VERSION ""

NS_ :

BS_:

BU_: BMS CVC_P EVCC FMCU RMCU POD_GW PCU ADCU_P DUMMY_ECU

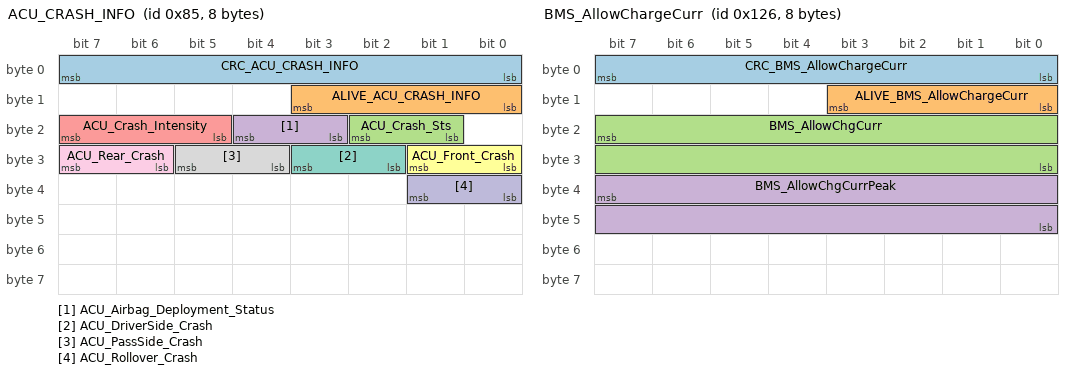
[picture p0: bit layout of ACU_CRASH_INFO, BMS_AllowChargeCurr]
BO_ 133 ACU_CRASH_INFO: 8 CVC_P
 SG_ CRC_ACU_CRASH_INFO : 7|8@0+ (1,0) [0|255] ""  BMS,EVCC,FMCU,RMCU,POD_GW,PCU
 SG_ ALIVE_ACU_CRASH_INFO : 11|4@0+ (1,0) [0|15] ""  BMS,EVCC,FMCU,RMCU,POD_GW,PCU
 SG_ ACU_Crash_Sts : 18|2@0+ (1,0) [0|3] ""  BMS,EVCC,FMCU,RMCU,POD_GW,PCU
 SG_ ACU_Airbag_Deployment_Status : 20|2@0+ (1,0) [0|3] ""  BMS,EVCC,FMCU,RMCU,POD_GW,PCU
 SG_ ACU_Crash_Intensity : 23|3@0+ (1,0) [0|7] ""  BMS,EVCC,FMCU,RMCU,POD_GW,PCU
 SG_ ACU_Front_Crash : 25|2@0+ (1,0) [0|3] ""  BMS,EVCC,FMCU,RMCU,POD_GW,PCU
 SG_ ACU_DriverSide_Crash : 27|2@0+ (1,0) [0|3] ""  BMS,EVCC,FMCU,RMCU,POD_GW,PCU
 SG_ ACU_PassSide_Crash : 29|2@0+ (1,0) [0|3] ""  BMS,EVCC,FMCU,RMCU,POD_GW,PCU
 SG_ ACU_Rear_Crash : 31|2@0+ (1,0) [0|3] ""  BMS,EVCC,FMCU,RMCU,POD_GW,PCU
 SG_ ACU_Rollover_Crash : 33|2@0+ (1,0) [0|3] ""  BMS,EVCC,FMCU,RMCU,POD_GW,PCU

BO_ 294 BMS_AllowChargeCurr: 8 BMS
 SG_ CRC_BMS_AllowChargeCurr : 7|8@0+ (1,0) [0|255] ""  CVC_P,EVCC
 SG_ ALIVE_BMS_AllowChargeCurr : 11|4@0+ (1,0) [0|15] ""  CVC_P,EVCC
 SG_ BMS_AllowChgCurr : 23|16@0+ (0.1,0) [0|1500] "A"  CVC_P,EVCC
 SG_ BMS_AllowChgCurrPeak : 39|16@0+ (0.1,0) [0|1500] "A"  CVC_P,EVCC

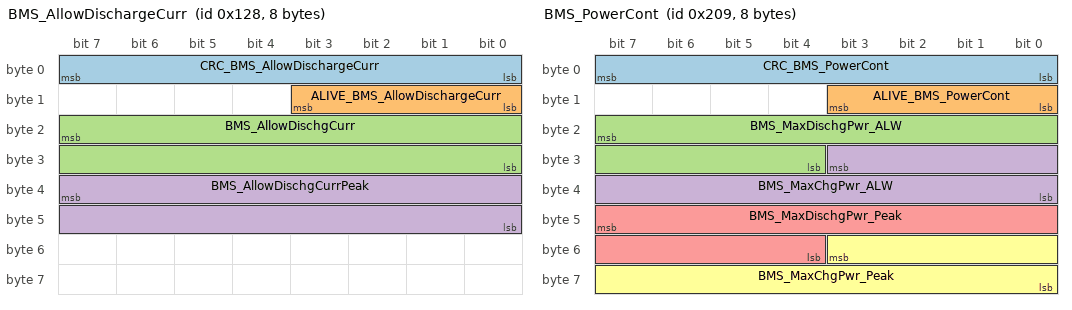
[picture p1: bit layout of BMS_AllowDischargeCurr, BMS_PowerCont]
BO_ 296 BMS_AllowDischargeCurr: 8 BMS
 SG_ CRC_BMS_AllowDischargeCurr : 7|8@0+ (1,0) [0|255] ""  CVC_P
 SG_ ALIVE_BMS_AllowDischargeCurr : 11|4@0+ (1,0) [0|15] ""  CVC_P
 SG_ BMS_AllowDischgCurr : 23|16@0+ (0.1,0) [0|1500] "A"  CVC_P
 SG_ BMS_AllowDischgCurrPeak : 39|16@0+ (0.1,0) [0|1500] "A"  CVC_P

BO_ 372 BMS_CurMeas: 24 BMS
 SG_ CRC_BMS_CurMeas : 7|8@0+ (1,0) [0|255] ""  CVC_P,EVCC,FMCU,RMCU,POD_GW,PCU
 SG_ ALIVE_BMS_CurMeas : 11|4@0+ (1,0) [0|15] ""  CVC_P,EVCC,FMCU,RMCU,POD_GW,PCU
 SG_ BMS_StartOfMeasument_STS : 15|1@0+ (1,0) [0|1] ""  CVC_P,EVCC
 SG_ BMS_PackCur_MEAS : 23|16@0+ (0.1,-3276.8) [-3276.8|3276.7] "A"  CVC_P,EVCC,FMCU,RMCU,POD_GW,PCU
 SG_ BMS_HVPackVol_MEAS : 39|16@0+ (0.1,0) [0|800] "V"  CVC_P,EVCC,FMCU,RMCU,PCU
 SG_ BMS_HVLinkVol_MEAS : 55|16@0+ (0.1,0) [0|800] "V"  CVC_P,EVCC,FMCU,RMCU,PCU
 SG_ BMS_HVBusVol_MEAS : 71|16@0+ (0.1,0) [0|800] "V"  CVC_P,EVCC,PCU
 SG_ BMS_HVFuseVol_MEAS : 87|16@0+ (0.1,0) [0|800] "V"  CVC_P
 SG_ BMS_MainNegRelay_Volt : 103|8@0+ (0.1,0) [0|5] "V"  CVC_P
 SG_ BMS_CellNumMinCellVol : 111|8@0+ (1,0) [0|255] ""  CVC_P
 SG_ BMS_CellNumMaxCellVol : 119|8@0+ (1,0) [0|255] ""  CVC_P
 SG_ BMS_MinCellVol : 127|13@0+ (0.001,0) [0|6] "V"  CVC_P
 SG_ BMS_MaxCellVol : 143|13@0+ (0.001,0) [0|6] "V"  CVC_P
 SG_ BMS_MaxMinDiffCellVol : 159|13@0+ (0.001,0) [0|2] "V"  CVC_P
 SG_ BMS_CVC_Insulation_Mon_Sts : 162|1@0+ (1,0) [0|1] ""  CVC_P,EVCC
 SG_ BMS_PackInsuRes : 175|16@0+ (1,0) [0|60000] "kOhm"  CVC_P,EVCC

BO_ 521 BMS_PowerCont: 8 BMS
 SG_ CRC_BMS_PowerCont : 7|8@0+ (1,0) [0|255] ""  CVC_P,FMCU,RMCU,PCU
 SG_ ALIVE_BMS_PowerCont : 11|4@0+ (1,0) [0|15] ""  CVC_P,FMCU,RMCU,PCU
 SG_ BMS_MaxDischgPwr_ALW : 23|12@0+ (0.1,0) [0|400] "kW"  CVC_P,FMCU,RMCU,PCU
 SG_ BMS_MaxChgPwr_ALW : 27|12@0+ (0.1,0) [0|400] "kW"  CVC_P,FMCU,RMCU,PCU
 SG_ BMS_MaxDischgPwr_Peak : 47|12@0+ (0.2,0) [0|800] "kW"  CVC_P,FMCU,RMCU,PCU
 SG_ BMS_MaxChgPwr_Peak : 51|12@0+ (0.2,0) [0|800] "kW"  CVC_P,FMCU,RMCU,PCU

BO_ 533 BMS_Sts: 16 BMS
 SG_ CRC_BMS_Sts : 7|8@0+ (1,0) [0|255] ""  CVC_P,EVCC,FMCU,RMCU,POD_GW,PCU
 SG_ ALIVE_BMS_Sts : 11|4@0+ (1,0) [0|15] ""  CVC_P,EVCC,FMCU,RMCU,POD_GW,PCU
 SG_ BMS_BatBalance_ERR : 12|1@0+ (1,0) [0|1] ""  CVC_P,EVCC,FMCU,RMCU,POD_GW,PCU
 SG_ BMS_Balance_STS : 13|1@0+ (1,0) [0|1] ""  CVC_P,EVCC,FMCU,RMCU,POD_GW,PCU
 SG_ BMS_IGN_Sts : 14|1@0+ (1,0) [0|1] ""  CVC_P,EVCC,FMCU,RMCU,POD_GW,PCU
 SG_ BMS_HWCrash_Sts : 15|1@0+ (1,0) [0|1] ""  CVC_P,EVCC,FMCU,RMCU,POD_GW,PCU
 SG_ BMS_HVIL_STS : 17|2@0+ (1,0) [0|3] ""  CVC_P,EVCC,FMCU,RMCU,POD_GW,PCU
 SG_ BMS_HVOnOff_STS : 19|2@0+ (1,0) [0|3] ""  CVC_P,EVCC,FMCU,RMCU,POD_GW,PCU
 SG_ BMS_ERR_LEV : 23|4@0+ (1,0) [0|7] ""  CVC_P,EVCC,FMCU,RMCU,POD_GW,PCU
 SG_ BMS_SocActual_EST : 25|10@0+ (0.1,0) [0|100] "%"  CVC_P,EVCC,FMCU,RMCU,POD_GW,PCU
 SG_ BMS_Sys_STS : 29|4@0+ (1,0) [0|15] ""  CVC_P,EVCC,FMCU,RMCU,POD_GW,PCU
 SG_ BMS_ISU_Status : 31|2@0+ (1,0) [0|3] ""  CVC_P,EVCC,FMCU,RMCU,POD_GW,PCU
 SG_ BMS_SOH : 47|8@0+ (0.5,0) [0|100] "%"  CVC_P,EVCC,FMCU,RMCU,POD_GW,PCU
 SG_ BMS_SOE : 55|8@0+ (0.5,0) [0|100] "%"  CVC_P,EVCC,FMCU,RMCU,POD_GW,PCU
 SG_ BMS_HV_Sts : 63|8@0+ (1,0) [0|255] ""  CVC_P,EVCC,FMCU,RMCU,POD_GW,PCU
 SG_ BMS_Display_SOC : 71|10@0+ (0.1,0) [0|100] "%"  CVC_P,EVCC,FMCU,RMCU,PCU
 SG_ BMS_SOCE : 87|14@0+ (0.01,0) [0|100] "%"  CVC_P

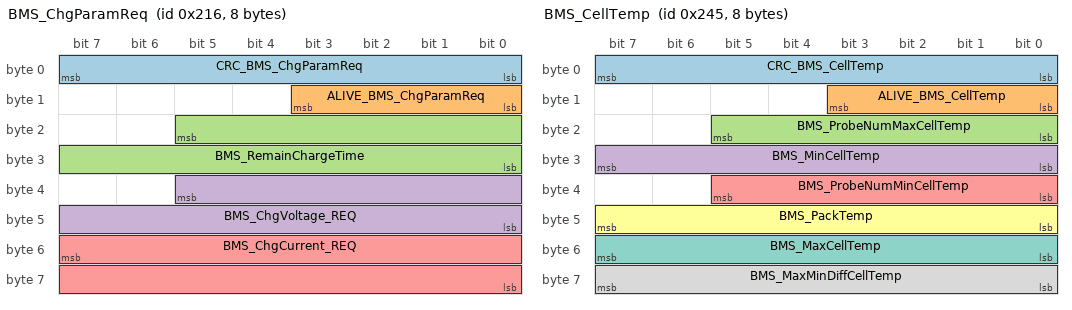
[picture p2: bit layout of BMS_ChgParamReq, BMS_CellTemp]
BO_ 534 BMS_ChgParamReq: 8 BMS
 SG_ CRC_BMS_ChgParamReq : 7|8@0+ (1,0) [0|255] ""  CVC_P,EVCC
 SG_ ALIVE_BMS_ChgParamReq : 11|4@0+ (1,0) [0|15] ""  CVC_P,EVCC
 SG_ BMS_RemainChargeTime : 21|14@0+ (1,0) [0|16383] "min"  CVC_P,EVCC
 SG_ BMS_ChgVoltage_REQ : 37|14@0+ (0.1,0) [0|800] "V"  CVC_P,EVCC
 SG_ BMS_ChgCurrent_REQ : 55|16@0+ (0.1,0) [0|1500] "A"  CVC_P,EVCC

BO_ 581 BMS_CellTemp: 8 BMS
 SG_ CRC_BMS_CellTemp : 7|8@0+ (1,0) [0|255] ""  CVC_P,EVCC,POD_GW
 SG_ ALIVE_BMS_CellTemp : 11|4@0+ (1,0) [0|15] ""  CVC_P,EVCC,POD_GW
 SG_ BMS_ProbeNumMaxCellTemp : 21|6@0+ (1,0) [0|63] ""  CVC_P,POD_GW
 SG_ BMS_MinCellTemp : 31|8@0+ (1,-40) [-40|215] "Degree C"  CVC_P
 SG_ BMS_ProbeNumMinCellTemp : 37|6@0+ (1,0) [0|63] ""  CVC_P,POD_GW
 SG_ BMS_PackTemp : 47|8@0+ (1,-40) [-40|215] "Degree C"  CVC_P
 SG_ BMS_MaxCellTemp : 55|8@0+ (1,-40) [-40|215] "Degree C"  CVC_P
 SG_ BMS_MaxMinDiffCellTemp : 63|8@0+ (1,-40) [-40|215] "Degree C"  CVC_P

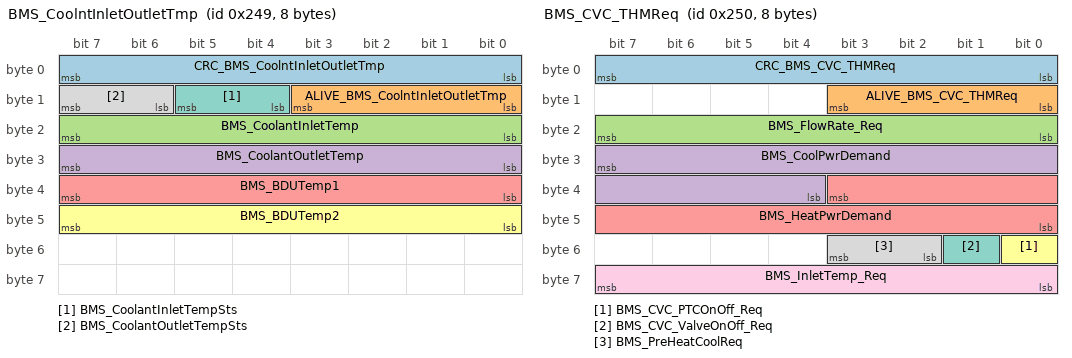
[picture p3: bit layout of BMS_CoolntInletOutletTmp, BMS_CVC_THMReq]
BO_ 585 BMS_CoolntInletOutletTmp: 8 BMS
 SG_ CRC_BMS_CoolntInletOutletTmp : 7|8@0+ (1,0) [0|255] ""  CVC_P,POD_GW
 SG_ ALIVE_BMS_CoolntInletOutletTmp : 11|4@0+ (1,0) [0|15] ""  CVC_P,POD_GW
 SG_ BMS_CoolantInletTemp : 23|8@0+ (1,-40) [-40|130] "Degree C"  CVC_P
 SG_ BMS_CoolantOutletTemp : 31|8@0+ (1,-40) [-40|130] "Degree C"  CVC_P
 SG_ BMS_BDUTemp1 : 39|8@0+ (1,-40) [-40|215] "Degree C"  CVC_P
 SG_ BMS_BDUTemp2 : 47|8@0+ (1,-40) [-40|215] "Degree C"  CVC_P
 SG_ BMS_CoolantInletTempSts : 13|2@0+ (1,0) [0|3] ""  CVC_P,POD_GW
 SG_ BMS_CoolantOutletTempSts : 15|2@0+ (1,0) [0|3] ""  CVC_P,POD_GW

BO_ 592 BMS_CVC_THMReq: 8 BMS
 SG_ CRC_BMS_CVC_THMReq : 7|8@0+ (1,0) [0|255] ""  CVC_P
 SG_ ALIVE_BMS_CVC_THMReq : 11|4@0+ (1,0) [0|15] ""  CVC_P
 SG_ BMS_FlowRate_Req : 23|8@0+ (1,0) [0|50] "l/min"  CVC_P
 SG_ BMS_CoolPwrDemand : 31|12@0+ (0.1,0) [0|10] "kW"  CVC_P
 SG_ BMS_HeatPwrDemand : 35|12@0+ (0.1,0) [0|10] "kW"  CVC_P
 SG_ BMS_CVC_PTCOnOff_Req : 48|1@0+ (1,0) [0|1] ""  CVC_P
 SG_ BMS_CVC_ValveOnOff_Req : 49|1@0+ (1,0) [0|1] ""  CVC_P
 SG_ BMS_PreHeatCoolReq : 51|2@0+ (1,0) [0|3] ""  CVC_P
 SG_ BMS_InletTemp_Req : 63|8@0+ (1,-40) [-40|215] "Degree C"  CVC_P

BO_ 816 BMS_HistData: 8 BMS
 SG_ CRC_BMS_HistData : 7|8@0+ (1,0) [0|255] ""  CVC_P
 SG_ ALIVE_BMS_HistData : 11|4@0+ (1,0) [0|15] ""  CVC_P
 SG_ BMS_ContactorAging : 23|8@0+ (1,0) [0|100] ""  CVC_P

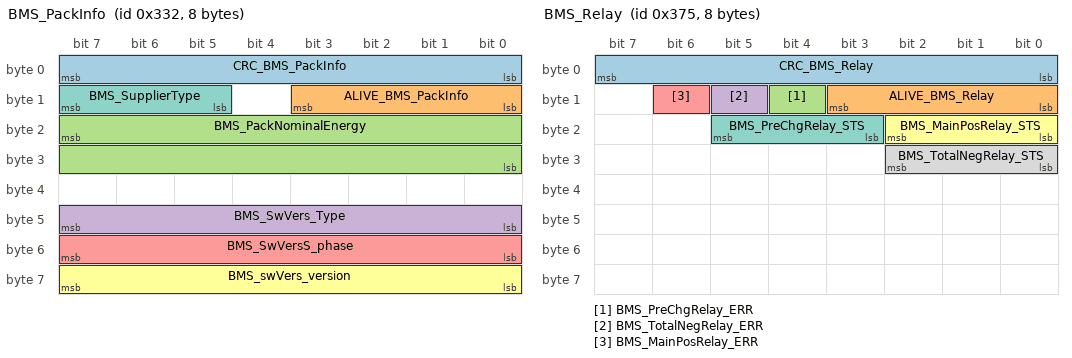
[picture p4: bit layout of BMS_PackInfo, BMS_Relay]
BO_ 818 BMS_PackInfo: 8 BMS
 SG_ CRC_BMS_PackInfo : 7|8@0+ (1,0) [0|255] ""  CVC_P
 SG_ ALIVE_BMS_PackInfo : 11|4@0+ (1,0) [0|15] ""  CVC_P
 SG_ BMS_PackNominalEnergy : 23|16@0+ (0.1,0) [0|6553.5] "kWh"  CVC_P
 SG_ BMS_SwVers_Type : 47|8@0+ (1,0) [0|255] ""  DUMMY_ECU
 SG_ BMS_SwVersS_phase : 55|8@0+ (1,0) [0|255] ""  DUMMY_ECU
 SG_ BMS_swVers_version : 63|8@0+ (1,0) [0|255] ""  DUMMY_ECU
 SG_ BMS_SupplierType : 15|3@0+ (1,0) [0|7] ""  DUMMY_ECU

BO_ 885 BMS_Relay: 8 BMS
 SG_ CRC_BMS_Relay : 7|8@0+ (1,0) [0|255] ""  CVC_P,FMCU,RMCU,POD_GW,PCU
 SG_ ALIVE_BMS_Relay : 11|4@0+ (1,0) [0|15] ""  CVC_P,FMCU,RMCU,POD_GW,PCU
 SG_ BMS_PreChgRelay_ERR : 12|1@0+ (1,0) [0|1] ""  CVC_P,FMCU,RMCU,POD_GW,PCU
 SG_ BMS_TotalNegRelay_ERR : 13|1@0+ (1,0) [0|1] ""  CVC_P,FMCU,RMCU,POD_GW,PCU
 SG_ BMS_MainPosRelay_ERR : 14|1@0+ (1,0) [0|1] ""  CVC_P,FMCU,RMCU,POD_GW,PCU
 SG_ BMS_MainPosRelay_STS : 18|3@0+ (1,0) [0|7] ""  CVC_P,FMCU,RMCU,POD_GW,PCU
 SG_ BMS_PreChgRelay_STS : 21|3@0+ (1,0) [0|7] ""  CVC_P,FMCU,RMCU,POD_GW,PCU
 SG_ BMS_TotalNegRelay_STS : 26|3@0+ (1,0) [0|7] ""  CVC_P,FMCU,RMCU,POD_GW,PCU

BO_ 1110 BMS_ERROR: 24 BMS
 SG_ CRC_BMS_ERROR : 7|8@0+ (1,0) [0|255] ""  CVC_P,PCU
 SG_ ALIVE_BMS_ERROR : 11|4@0+ (1,0) [0|15] ""  CVC_P,PCU
 SG_ BMS_CellLowVol_ERR : 17|2@0+ (1,0) [0|3] ""  CVC_P
 SG_ BMS_HVIL_Err : 19|2@0+ (1,0) [0|3] ""  CVC_P,PCU
 SG_ BMS_PackInsu_ERR : 21|2@0+ (1,0) [0|3] ""  CVC_P
 SG_ BMS_CellVoltDiff_ERR : 23|2@0+ (1,0) [0|3] ""  CVC_P
 SG_ BMS_ProbeTempDiff_ERR : 25|2@0+ (1,0) [0|3] ""  CVC_P
 SG_ BMS_PackHighVol_ERR : 27|2@0+ (1,0) [0|3] ""  CVC_P,PCU
 SG_ BMS_PackLowVol_ERR : 29|2@0+ (1,0) [0|3] ""  CVC_P
 SG_ BMS_CellHighVol_ERR : 31|2@0+ (1,0) [0|3] ""  CVC_P
 SG_ BMS_ProbeHighTemp_ERR : 33|2@0+ (1,0) [0|3] ""  CVC_P,PCU
 SG_ BMS_FuseStatus_ERR : 35|2@0+ (1,0) [0|1] ""  CVC_P
 SG_ BMS_PackOverCurr_ERR : 37|2@0+ (1,0) [0|3] ""  CVC_P,PCU
 SG_ BMS_ProbeLowTemp_ERR : 39|2@0+ (1,0) [0|3] ""  CVC_P,PCU
 SG_ BMS_faultnumber : 47|64@0+ (1,0) [0|1.84467E+019] ""  CVC_P
 SG_ EHPMon_bErrVehIslnRNvMon : 15|1@0+ (1,0) [0|1] ""  CVC_P
 SG_ EHPMon_bErrPackIslnRNvMon : 14|1@0+ (1,0) [0|1] ""  CVC_P

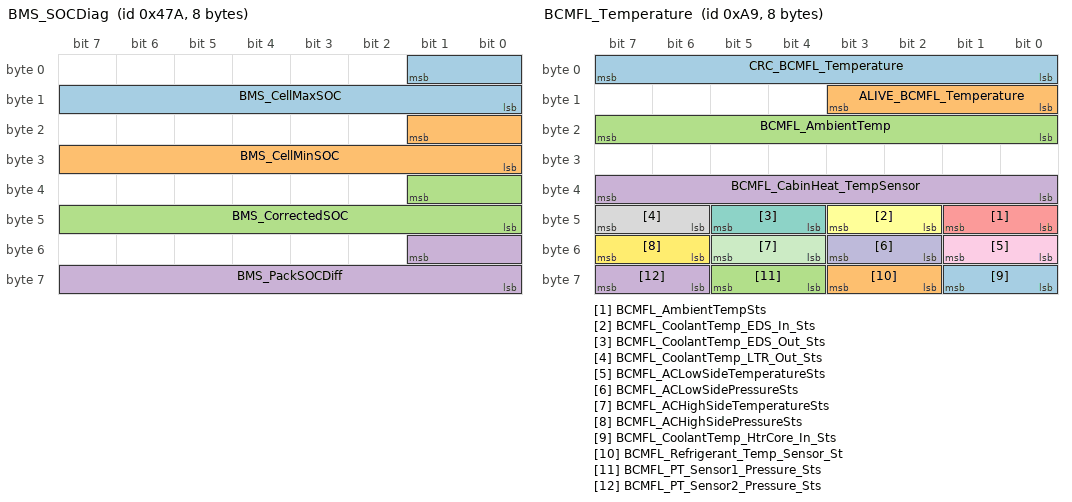
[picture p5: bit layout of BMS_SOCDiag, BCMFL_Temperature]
BO_ 1146 BMS_SOCDiag: 8 BMS
 SG_ BMS_CellMaxSOC : 1|10@0+ (0.1,0) [0|100] "%"  FMCU,RMCU,PCU
 SG_ BMS_CellMinSOC : 17|10@0+ (0.1,0) [0|100] "%"  FMCU,RMCU,PCU
 SG_ BMS_CorrectedSOC : 33|10@0+ (0.1,0) [0|100] "%"  FMCU,RMCU,PCU
 SG_ BMS_PackSOCDiff : 49|10@0+ (0.1,0) [0|100] "%"  FMCU,RMCU,PCU

BO_ 1171 BMS_WarnMsg: 8 BMS
 SG_ CRC_BMS_WarnMsg : 7|8@0+ (1,0) [0|255] ""  CVC_P,PCU
 SG_ ALIVE_BMS_WarnMsg : 11|4@0+ (1,0) [0|15] ""  CVC_P,PCU
 SG_ BMS_PackTempSts : 13|2@0+ (1,0) [0|3] ""  CVC_P
 SG_ BMS_ThermalRunaway : 14|1@0+ (1,0) [0|1] ""  CVC_P,PCU
 SG_ BMS_BatteryReplacement : 15|1@0+ (1,0) [0|1] ""  CVC_P
 SG_ BMS_Warning_PowerDegrade : 16|1@0+ (1,0) [0|1] ""  CVC_P
 SG_ BMS_Warning_DeltaSoC : 17|1@0+ (1,0) [0|1] ""  CVC_P
 SG_ BMS_Warning_HVILSts : 18|1@0+ (1,0) [0|1] ""  CVC_P
 SG_ BMS_Warning_Isolation : 19|1@0+ (1,0) [0|1] ""  CVC_P
 SG_ BMS_Warning_CoolantLeakage : 20|1@0+ (1,0) [0|1] ""  CVC_P
 SG_ BMS_MalfunctionSts : 21|1@0+ (1,0) [0|1] ""  CVC_P
 SG_ BMS_LowBattery : 23|2@0+ (1,0) [0|3] ""  CVC_P
 SG_ BMS_Warning_DeltaTemperature : 31|8@0+ (1,0) [0|255] ""  CVC_P
 SG_ BMS_Warning_BDUTemperatureSts : 39|8@0+ (1,0) [0|255] ""  CVC_P
 SG_ BMS_Warning_Contactor_Aging : 47|1@0+ (1,0) [0|1] ""  CVC_P
 SG_ BMS_Reserved_signal4 : 55|8@0+ (1,0) [0|255] ""  CVC_P
 SG_ BMS_Reserved_signal5 : 63|8@0+ (1,0) [0|255] ""  CVC_P

BO_ 1952 BMS_CellTemp_Info: 64 BMS
 SG_ BMS_CellT1 : 7|8@0+ (1,-40) [-40|210] "Degree C"  DUMMY_ECU
 SG_ BMS_CellT2 : 15|8@0+ (1,-40) [-40|210] "Degree C"  DUMMY_ECU
 SG_ BMS_CellT3 : 23|8@0+ (1,-40) [-40|210] "Degree C"  DUMMY_ECU
 SG_ BMS_CellT4 : 31|8@0+ (1,-40) [-40|210] "Degree C"  DUMMY_ECU
 SG_ BMS_CellT5 : 39|8@0+ (1,-40) [-40|210] "Degree C"  DUMMY_ECU
 SG_ BMS_CellT6 : 47|8@0+ (1,-40) [-40|210] "Degree C"  DUMMY_ECU
 SG_ BMS_CellT7 : 55|8@0+ (1,-40) [-40|210] "Degree C"  DUMMY_ECU
 SG_ BMS_CellT8 : 63|8@0+ (1,-40) [-40|210] "Degree C"  DUMMY_ECU
 SG_ BMS_CellT9 : 71|8@0+ (1,-40) [-40|210] "Degree C"  DUMMY_ECU
 SG_ BMS_CellT10 : 79|8@0+ (1,-40) [-40|210] "Degree C"  DUMMY_ECU
 SG_ BMS_CellT11 : 87|8@0+ (1,-40) [-40|210] "Degree C"  DUMMY_ECU
 SG_ BMS_CellT12 : 95|8@0+ (1,-40) [-40|210] "Degree C"  DUMMY_ECU
 SG_ BMS_CellT13 : 103|8@0+ (1,-40) [-40|210] "Degree C"  DUMMY_ECU
 SG_ BMS_CellT14 : 111|8@0+ (1,-40) [-40|210] "Degree C"  DUMMY_ECU
 SG_ BMS_CellT15 : 119|8@0+ (1,-40) [-40|210] "Degree C"  DUMMY_ECU
 SG_ BMS_CellT16 : 127|8@0+ (1,-40) [-40|210] "Degree C"  DUMMY_ECU
 SG_ BMS_CellT17 : 135|8@0+ (1,-40) [-40|210] "Degree C"  DUMMY_ECU
 SG_ BMS_CellT18 : 143|8@0+ (1,-40) [-40|210] "Degree C"  DUMMY_ECU
 SG_ BMS_CellT19 : 151|8@0+ (1,-40) [-40|210] "Degree C"  DUMMY_ECU
 SG_ BMS_CellT20 : 159|8@0+ (1,-40) [-40|210] "Degree C"  DUMMY_ECU
 SG_ BMS_CellT21 : 167|8@0+ (1,-40) [-40|210] "Degree C"  DUMMY_ECU
 SG_ BMS_CellT22 : 175|8@0+ (1,-40) [-40|210] "Degree C"  DUMMY_ECU
 SG_ BMS_CellT23 : 183|8@0+ (1,-40) [-40|210] "Degree C"  DUMMY_ECU
 SG_ BMS_CellT24 : 191|8@0+ (1,-40) [-40|210] "Degree C"  DUMMY_ECU
 SG_ BMS_CellT25 : 199|8@0+ (1,-40) [-40|210] "Degree C"  DUMMY_ECU
 SG_ BMS_CellT26 : 207|8@0+ (1,-40) [-40|210] "Degree C"  DUMMY_ECU
 SG_ BMS_CellT27 : 215|8@0+ (1,-40) [-40|210] "Degree C"  DUMMY_ECU
 SG_ BMS_CellT28 : 223|8@0+ (1,-40) [-40|210] "Degree C"  DUMMY_ECU
 SG_ BMS_CellT29 : 231|8@0+ (1,-40) [-40|210] "Degree C"  DUMMY_ECU
 SG_ BMS_CellT30 : 239|8@0+ (1,-40) [-40|210] "Degree C"  DUMMY_ECU
 SG_ BMS_CellT31 : 247|8@0+ (1,-40) [-40|210] "Degree C"  DUMMY_ECU
 SG_ BMS_CellT32 : 255|8@0+ (1,-40) [-40|210] "Degree C"  DUMMY_ECU
 SG_ BMS_CellT33 : 263|8@0+ (1,-40) [-40|210] "Degree C"  DUMMY_ECU
 SG_ BMS_CellT34 : 271|8@0+ (1,-40) [-40|210] "Degree C"  DUMMY_ECU
 SG_ BMS_CellT35 : 279|8@0+ (1,-40) [-40|210] "Degree C"  DUMMY_ECU
 SG_ BMS_CellT36 : 287|8@0+ (1,-40) [-40|210] "Degree C"  DUMMY_ECU
 SG_ BMS_BalArea_Temperature1 : 295|8@0+ (1,-50) [-50|150] "Degree C"  DUMMY_ECU
 SG_ BMS_BalArea_Temperature2 : 303|8@0+ (1,-50) [-50|150] "Degree C"  DUMMY_ECU
 SG_ BMS_BalArea_Temperature3 : 311|8@0+ (1,-50) [-50|150] "Degree C"  DUMMY_ECU
 SG_ BMS_BalArea_Temperature4 : 319|8@0+ (1,-50) [-50|150] "Degree C"  DUMMY_ECU
 SG_ BMS_BalArea_Temperature5 : 327|8@0+ (1,-50) [-50|150] "Degree C"  DUMMY_ECU
 SG_ BMS_BalArea_Temperature6 : 335|8@0+ (1,-50) [-50|150] "Degree C"  DUMMY_ECU
 SG_ BMS_BalArea_Temperature7 : 343|8@0+ (1,-50) [-50|150] "Degree C"  DUMMY_ECU
 SG_ BMS_BalArea_Temperature8 : 351|8@0+ (1,-50) [-50|150] "Degree C"  DUMMY_ECU
 SG_ BMS_BPS_pressureValue : 375|16@0+ (0.1,0) [0|409.5] "kpa"  DUMMY_ECU
 SG_ BMS_CVS_Temperature : 359|16@0+ (1,-50) [-50|150] "Degree C"  DUMMY_ECU
 SG_ BMS_KL30_Voltage : 391|16@0+ (0.001,0) [0|18] "V"  DUMMY_ECU

BO_ 1953 BMS_CellVolt_Info01: 64 BMS
 SG_ BMS_CellVolt_1 : 7|16@0+ (0.001,0) [0|5] "V"  DUMMY_ECU
 SG_ BMS_CellVolt_2 : 23|16@0+ (0.001,0) [0|5] "V"  DUMMY_ECU
 SG_ BMS_CellVolt_3 : 39|16@0+ (0.001,0) [0|5] "V"  DUMMY_ECU
 SG_ BMS_CellVolt_4 : 55|16@0+ (0.001,0) [0|5] "V"  DUMMY_ECU
 SG_ BMS_CellVolt_5 : 71|16@0+ (0.001,0) [0|5] "V"  DUMMY_ECU
 SG_ BMS_CellVolt_6 : 87|16@0+ (0.001,0) [0|5] "V"  DUMMY_ECU
 SG_ BMS_CellVolt_7 : 103|16@0+ (0.001,0) [0|5] "V"  DUMMY_ECU
 SG_ BMS_CellVolt_8 : 423|16@0+ (0.001,0) [0|5] "V"  DUMMY_ECU
 SG_ BMS_CellVolt_9 : 311|16@0+ (0.001,0) [0|5] "V"  DUMMY_ECU
 SG_ BMS_CellVolt_10 : 215|16@0+ (0.001,0) [0|5] "V"  DUMMY_ECU
 SG_ BMS_CellVolt_11 : 327|16@0+ (0.001,0) [0|5] "V"  DUMMY_ECU
 SG_ BMS_CellVolt_12 : 439|16@0+ (0.001,0) [0|5] "V"  DUMMY_ECU
 SG_ BMS_CellVolt_13 : 119|16@0+ (0.001,0) [0|5] "V"  DUMMY_ECU
 SG_ BMS_CellVolt_14 : 231|16@0+ (0.001,0) [0|5] "V"  DUMMY_ECU
 SG_ BMS_CellVolt_15 : 343|16@0+ (0.001,0) [0|5] "V"  DUMMY_ECU
 SG_ BMS_CellVolt_16 : 455|16@0+ (0.001,0) [0|5] "V"  DUMMY_ECU
 SG_ BMS_CellVolt_17 : 135|16@0+ (0.001,0) [0|5] "V"  DUMMY_ECU
 SG_ BMS_CellVolt_18 : 247|16@0+ (0.001,0) [0|5] "V"  DUMMY_ECU
 SG_ BMS_CellVolt_19 : 359|16@0+ (0.001,0) [0|5] "V"  DUMMY_ECU
 SG_ BMS_CellVolt_20 : 471|16@0+ (0.001,0) [0|5] "V"  DUMMY_ECU
 SG_ BMS_CellVolt_21 : 151|16@0+ (0.001,0) [0|5] "V"  DUMMY_ECU
 SG_ BMS_CellVolt_22 : 263|16@0+ (0.001,0) [0|5] "V"  DUMMY_ECU
 SG_ BMS_CellVolt_23 : 375|16@0+ (0.001,0) [0|5] "V"  DUMMY_ECU
 SG_ BMS_CellVolt_24 : 487|16@0+ (0.001,0) [0|5] "V"  DUMMY_ECU
 SG_ BMS_CellVolt_25 : 167|16@0+ (0.001,0) [0|5] "V"  DUMMY_ECU
 SG_ BMS_CellVolt_26 : 279|16@0+ (0.001,0) [0|5] "V"  DUMMY_ECU
 SG_ BMS_CellVolt_27 : 391|16@0+ (0.001,0) [0|5] "V"  DUMMY_ECU
 SG_ BMS_CellVolt_28 : 503|16@0+ (0.001,0) [0|5] "V"  DUMMY_ECU
 SG_ BMS_CellVolt_29 : 183|16@0+ (0.001,0) [0|5] "V"  DUMMY_ECU
 SG_ BMS_CellVolt_30 : 295|16@0+ (0.001,0) [0|5] "V"  DUMMY_ECU
 SG_ BMS_CellVolt_31 : 407|16@0+ (0.001,0) [0|5] "V"  DUMMY_ECU
 SG_ BMS_CellVolt_32 : 199|16@0+ (0.001,0) [0|5] "V"  DUMMY_ECU

BO_ 1954 BMS_CellVolt_Info02: 64 BMS
 SG_ BMS_CellVolt_33 : 71|16@0+ (0.001,0) [0|5] "V"  DUMMY_ECU
 SG_ BMS_CellVolt_34 : 87|16@0+ (0.001,0) [0|5] "V"  DUMMY_ECU
 SG_ BMS_CellVolt_35 : 103|16@0+ (0.001,0) [0|5] "V"  DUMMY_ECU
 SG_ BMS_CellVolt_36 : 119|16@0+ (0.001,0) [0|5] "V"  DUMMY_ECU
 SG_ BMS_CellVolt_37 : 135|16@0+ (0.001,0) [0|5] "V"  DUMMY_ECU
 SG_ BMS_CellVolt_38 : 151|16@0+ (0.001,0) [0|5] "V"  DUMMY_ECU
 SG_ BMS_CellVolt_39 : 167|16@0+ (0.001,0) [0|5] "V"  DUMMY_ECU
 SG_ BMS_CellVolt_40 : 183|16@0+ (0.001,0) [0|5] "V"  DUMMY_ECU
 SG_ BMS_CellVolt_41 : 199|16@0+ (0.001,0) [0|5] "V"  DUMMY_ECU
 SG_ BMS_CellVolt_42 : 215|16@0+ (0.001,0) [0|5] "V"  DUMMY_ECU
 SG_ BMS_CellVolt_43 : 231|16@0+ (0.001,0) [0|5] "V"  DUMMY_ECU
 SG_ BMS_CellVolt_44 : 247|16@0+ (0.001,0) [0|5] "V"  DUMMY_ECU
 SG_ BMS_CellVolt_45 : 263|16@0+ (0.001,0) [0|5] "V"  DUMMY_ECU
 SG_ BMS_CellVolt_46 : 279|16@0+ (0.001,0) [0|5] "V"  DUMMY_ECU
 SG_ BMS_CellVolt_47 : 295|16@0+ (0.001,0) [0|5] "V"  DUMMY_ECU
 SG_ BMS_CellVolt_48 : 311|16@0+ (0.001,0) [0|5] "V"  DUMMY_ECU
 SG_ BMS_CellVolt_49 : 327|16@0+ (0.001,0) [0|5] "V"  DUMMY_ECU
 SG_ BMS_CellVolt_50 : 343|16@0+ (0.001,0) [0|5] "V"  DUMMY_ECU
 SG_ BMS_CellVolt_51 : 359|16@0+ (0.001,0) [0|5] "V"  DUMMY_ECU
 SG_ BMS_CellVolt_52 : 375|16@0+ (0.001,0) [0|5] "V"  DUMMY_ECU
 SG_ BMS_CellVolt_53 : 391|16@0+ (0.001,0) [0|5] "V"  DUMMY_ECU
 SG_ BMS_CellVolt_54 : 407|16@0+ (0.001,0) [0|5] "V"  DUMMY_ECU
 SG_ BMS_CellVolt_55 : 423|16@0+ (0.001,0) [0|5] "V"  DUMMY_ECU
 SG_ BMS_CellVolt_56 : 439|16@0+ (0.001,0) [0|5] "V"  DUMMY_ECU
 SG_ BMS_CellVolt_57 : 455|16@0+ (0.001,0) [0|5] "V"  DUMMY_ECU
 SG_ BMS_CellVolt_58 : 471|16@0+ (0.001,0) [0|5] "V"  DUMMY_ECU
 SG_ BMS_CellVolt_59 : 487|16@0+ (0.001,0) [0|5] "V"  DUMMY_ECU
 SG_ BMS_CellVolt_60 : 503|16@0+ (0.001,0) [0|5] "V"  DUMMY_ECU
 SG_ BMS_CellVolt_61 : 7|16@0+ (0.001,0) [0|5] "V"  DUMMY_ECU
 SG_ BMS_CellVolt_62 : 23|16@0+ (0.001,0) [0|5] "V"  DUMMY_ECU
 SG_ BMS_CellVolt_63 : 39|16@0+ (0.001,0) [0|5] "V"  DUMMY_ECU
 SG_ BMS_CellVolt_64 : 55|16@0+ (0.001,0) [0|5] "V"  DUMMY_ECU

BO_ 1955 BMS_CellVolt_Info03: 64 BMS
 SG_ BMS_CellVolt_65 : 71|16@0+ (0.001,0) [0|5] "V"  DUMMY_ECU
 SG_ BMS_CellVolt_66 : 87|16@0+ (0.001,0) [0|5] "V"  DUMMY_ECU
 SG_ BMS_CellVolt_67 : 103|16@0+ (0.001,0) [0|5] "V"  DUMMY_ECU
 SG_ BMS_CellVolt_68 : 119|16@0+ (0.001,0) [0|5] "V"  DUMMY_ECU
 SG_ BMS_CellVolt_69 : 135|16@0+ (0.001,0) [0|5] "V"  DUMMY_ECU
 SG_ BMS_CellVolt_70 : 151|16@0+ (0.001,0) [0|5] "V"  DUMMY_ECU
 SG_ BMS_CellVolt_71 : 167|16@0+ (0.001,0) [0|5] "V"  DUMMY_ECU
 SG_ BMS_CellVolt_72 : 183|16@0+ (0.001,0) [0|5] "V"  DUMMY_ECU
 SG_ BMS_CellVolt_73 : 199|16@0+ (0.001,0) [0|5] "V"  DUMMY_ECU
 SG_ BMS_CellVolt_74 : 215|16@0+ (0.001,0) [0|5] "V"  DUMMY_ECU
 SG_ BMS_CellVolt_75 : 231|16@0+ (0.001,0) [0|5] "V"  DUMMY_ECU
 SG_ BMS_CellVolt_76 : 247|16@0+ (0.001,0) [0|5] "V"  DUMMY_ECU
 SG_ BMS_CellVolt_77 : 263|16@0+ (0.001,0) [0|5] "V"  DUMMY_ECU
 SG_ BMS_CellVolt_78 : 279|16@0+ (0.001,0) [0|5] "V"  DUMMY_ECU
 SG_ BMS_CellVolt_79 : 295|16@0+ (0.001,0) [0|5] "V"  DUMMY_ECU
 SG_ BMS_CellVolt_80 : 311|16@0+ (0.001,0) [0|5] "V"  DUMMY_ECU
 SG_ BMS_CellVolt_81 : 327|16@0+ (0.001,0) [0|5] "V"  DUMMY_ECU
 SG_ BMS_CellVolt_82 : 343|16@0+ (0.001,0) [0|5] "V"  DUMMY_ECU
 SG_ BMS_CellVolt_83 : 359|16@0+ (0.001,0) [0|5] "V"  DUMMY_ECU
 SG_ BMS_CellVolt_84 : 375|16@0+ (0.001,0) [0|5] "V"  DUMMY_ECU
 SG_ BMS_CellVolt_85 : 391|16@0+ (0.001,0) [0|5] "V"  DUMMY_ECU
 SG_ BMS_CellVolt_86 : 407|16@0+ (0.001,0) [0|5] "V"  DUMMY_ECU
 SG_ BMS_CellVolt_87 : 423|16@0+ (0.001,0) [0|5] "V"  DUMMY_ECU
 SG_ BMS_CellVolt_88 : 439|16@0+ (0.001,0) [0|5] "V"  DUMMY_ECU
 SG_ BMS_CellVolt_89 : 455|16@0+ (0.001,0) [0|5] "V"  DUMMY_ECU
 SG_ BMS_CellVolt_90 : 471|16@0+ (0.001,0) [0|5] "V"  DUMMY_ECU
 SG_ BMS_CellVolt_91 : 487|16@0+ (0.001,0) [0|5] "V"  DUMMY_ECU
 SG_ BMS_CellVolt_92 : 503|16@0+ (0.001,0) [0|5] "V"  DUMMY_ECU
 SG_ BMS_CellVolt_93 : 7|16@0+ (0.001,0) [0|5] "V"  DUMMY_ECU
 SG_ BMS_CellVolt_94 : 23|16@0+ (0.001,0) [0|5] "V"  DUMMY_ECU
 SG_ BMS_CellVolt_95 : 39|16@0+ (0.001,0) [0|5] "V"  DUMMY_ECU
 SG_ BMS_CellVolt_96 : 55|16@0+ (0.001,0) [0|5] "V"  DUMMY_ECU

BO_ 1956 BMS_CellVolt_Info04: 64 BMS
 SG_ BMS_CellVolt_97 : 71|16@0+ (0.001,0) [0|5] "V"  DUMMY_ECU
 SG_ BMS_CellVolt_98 : 87|16@0+ (0.001,0) [0|5] "V"  DUMMY_ECU
 SG_ BMS_CellVolt_99 : 103|16@0+ (0.001,0) [0|5] "V"  DUMMY_ECU
 SG_ BMS_CellVolt_100 : 119|16@0+ (0.001,0) [0|5] "V"  DUMMY_ECU
 SG_ BMS_CellVolt_101 : 135|16@0+ (0.001,0) [0|5] "V"  DUMMY_ECU
 SG_ BMS_CellVolt_102 : 151|16@0+ (0.001,0) [0|5] "V"  DUMMY_ECU
 SG_ BMS_CellVolt_103 : 167|16@0+ (0.001,0) [0|5] "V"  DUMMY_ECU
 SG_ BMS_CellVolt_104 : 183|16@0+ (0.001,0) [0|5] "V"  DUMMY_ECU
 SG_ BMS_CellVolt_105 : 199|16@0+ (0.001,0) [0|5] "V"  DUMMY_ECU
 SG_ BMS_CellVolt_106 : 215|16@0+ (0.001,0) [0|5] "V"  DUMMY_ECU
 SG_ BMS_CellVolt_107 : 231|16@0+ (0.001,0) [0|5] "V"  DUMMY_ECU
 SG_ BMS_CellVolt_108 : 247|16@0+ (0.001,0) [0|5] "V"  DUMMY_ECU
 SG_ BMS_CellVolt_109 : 263|16@0+ (0.001,0) [0|5] "V"  DUMMY_ECU
 SG_ BMS_CellVolt_110 : 279|16@0+ (0.001,0) [0|5] "V"  DUMMY_ECU
 SG_ BMS_CellVolt_111 : 295|16@0+ (0.001,0) [0|5] "V"  DUMMY_ECU
 SG_ BMS_CellVolt_112 : 311|16@0+ (0.001,0) [0|5] "V"  DUMMY_ECU
 SG_ BMS_CellVolt_113 : 327|16@0+ (0.001,0) [0|5] "V"  DUMMY_ECU
 SG_ BMS_CellVolt_114 : 343|16@0+ (0.001,0) [0|5] "V"  DUMMY_ECU
 SG_ BMS_CellVolt_115 : 359|16@0+ (0.001,0) [0|5] "V"  DUMMY_ECU
 SG_ BMS_CellVolt_116 : 375|16@0+ (0.001,0) [0|5] "V"  DUMMY_ECU
 SG_ BMS_CellVolt_117 : 391|16@0+ (0.001,0) [0|5] "V"  DUMMY_ECU
 SG_ BMS_CellVolt_118 : 407|16@0+ (0.001,0) [0|5] "V"  DUMMY_ECU
 SG_ BMS_CellVolt_119 : 423|16@0+ (0.001,0) [0|5] "V"  DUMMY_ECU
 SG_ BMS_CellVolt_120 : 439|16@0+ (0.001,0) [0|5] "V"  DUMMY_ECU
 SG_ BMS_CellVolt_121 : 455|16@0+ (0.001,0) [0|5] "V"  DUMMY_ECU
 SG_ BMS_CellVolt_122 : 471|16@0+ (0.001,0) [0|5] "V"  DUMMY_ECU
 SG_ BMS_CellVolt_123 : 487|16@0+ (0.001,0) [0|5] "V"  DUMMY_ECU
 SG_ BMS_CellVolt_124 : 503|16@0+ (0.001,0) [0|5] "V"  DUMMY_ECU
 SG_ BMS_CellVolt_125 : 7|16@0+ (0.001,0) [0|5] "V"  DUMMY_ECU
 SG_ BMS_CellVolt_126 : 23|16@0+ (0.001,0) [0|5] "V"  DUMMY_ECU
 SG_ BMS_CellVolt_127 : 39|16@0+ (0.001,0) [0|5] "V"  DUMMY_ECU
 SG_ BMS_CellVolt_128 : 55|16@0+ (0.001,0) [0|5] "V"  DUMMY_ECU

BO_ 1939 BMS_XCPTx: 8 BMS
 SG_ BMS_XCPTxData : 7|64@0+ (1,0) [0|0] ""  CVC_P

BO_ 169 BCMFL_Temperature: 8 CVC_P
 SG_ CRC_BCMFL_Temperature : 7|8@0+ (1,0) [0|255] ""  BMS,EVCC,FMCU,RMCU,POD_GW,PCU
 SG_ ALIVE_BCMFL_Temperature : 11|4@0+ (1,0) [0|15] ""  BMS,EVCC,FMCU,RMCU,POD_GW,PCU
 SG_ BCMFL_AmbientTemp : 23|8@0+ (0.5,-40) [-40|85] "Degree C"  BMS,EVCC,FMCU,RMCU,POD_GW,PCU
 SG_ BCMFL_CabinHeat_TempSensor : 39|8@0+ (0.5,-40) [-40|85] "Degree C"  BMS,EVCC,FMCU,RMCU,POD_GW,PCU
 SG_ BCMFL_AmbientTempSts : 41|2@0+ (1,0) [0|3] ""  BMS,EVCC,FMCU,RMCU,POD_GW,PCU
 SG_ BCMFL_CoolantTemp_EDS_In_Sts : 43|2@0+ (1,0) [0|3] ""  BMS,EVCC,FMCU,RMCU,POD_GW,PCU
 SG_ BCMFL_CoolantTemp_EDS_Out_Sts : 45|2@0+ (1,0) [0|3] ""  BMS,EVCC,FMCU,RMCU,POD_GW,PCU
 SG_ BCMFL_CoolantTemp_LTR_Out_Sts : 47|2@0+ (1,0) [0|3] ""  BMS,EVCC,FMCU,RMCU,POD_GW,PCU
 SG_ BCMFL_ACLowSideTemperatureSts : 49|2@0+ (1,0) [0|3] ""  BMS,EVCC,FMCU,RMCU,POD_GW,PCU
 SG_ BCMFL_ACLowSidePressureSts : 51|2@0+ (1,0) [0|3] ""  BMS,EVCC,FMCU,RMCU,POD_GW,PCU
 SG_ BCMFL_ACHighSideTemperatureSts : 53|2@0+ (1,0) [0|3] ""  BMS,EVCC,FMCU,RMCU,POD_GW,PCU
 SG_ BCMFL_ACHighSidePressureSts : 55|2@0+ (1,0) [0|3] ""  BMS,EVCC,FMCU,RMCU,POD_GW,PCU
 SG_ BCMFL_CoolantTemp_HtrCore_In_Sts : 57|2@0+ (1,0) [0|3] ""  BMS,EVCC,FMCU,RMCU,POD_GW,PCU
 SG_ BCMFL_Refrigerant_Temp_Sensor_St : 59|2@0+ (1,0) [0|3] ""  BMS,EVCC,FMCU,RMCU,POD_GW,PCU
 SG_ BCMFL_PT_Sensor1_Pressure_Sts : 61|2@0+ (1,0) [0|3] ""  BMS,EVCC,FMCU,RMCU,POD_GW,PCU
 SG_ BCMFL_PT_Sensor2_Pressure_Sts : 63|2@0+ (1,0) [0|3] ""  BMS,EVCC,FMCU,RMCU,POD_GW,PCU

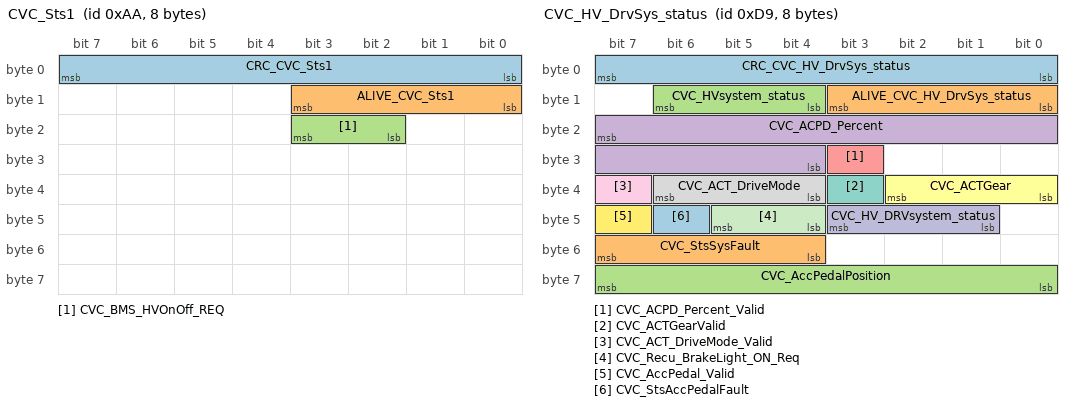
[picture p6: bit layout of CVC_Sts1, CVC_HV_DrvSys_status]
BO_ 170 CVC_Sts1: 8 CVC_P
 SG_ CRC_CVC_Sts1 : 7|8@0+ (1,0) [0|255] "W"  BMS
 SG_ ALIVE_CVC_Sts1 : 11|4@0+ (1,0) [0|15] ""  BMS
 SG_ CVC_BMS_HVOnOff_REQ : 19|2@0+ (1,0) [0|1] ""  BMS

BO_ 171 CVC_FMCU_Ctrl: 24 CVC_P
 SG_ CRC_CVC_FMCU_Ctrl : 7|8@0+ (1,0) [0|255] ""  FMCU,PCU
 SG_ ALIVE_CVC_FMCU_Ctrl : 11|4@0+ (1,0) [0|15] ""  FMCU,PCU
 SG_ CVC_FMCU_TargetTqReq : 23|16@0+ (0.1,-400) [-400|400] "Nm"  FMCU,PCU
 SG_ CVC_FMCU_TargetSpeedReq : 39|16@0+ (1,-20000) [-20000|45535] "rpm"  FMCU,PCU
 SG_ CVC_FMCU_StsModeReq : 51|4@0+ (1,0) [0|15] ""  FMCU,PCU
 SG_ CVC_FMCU_Oil_Pump_Relay_Sts : 53|1@0+ (1,0) [0|1] ""  FMCU,PCU
 SG_ CVC_FMCU_TargetTqReqV : 54|1@0+ (1,0) [0|1] ""  FMCU,PCU
 SG_ CVC_FMCU_TargetSpeedReqV : 55|1@0+ (1,0) [0|1] ""  FMCU,PCU
 SG_ CVC_FMCU_VehicleDirect : 56|1@0+ (1,0) [0|1] ""  FMCU,PCU
 SG_ CVC_MCU_AtvDischg_Req : 57|1@0+ (1,0) [0|1] ""  FMCU,PCU
 SG_ CVC_MCU_CtrlModeReq : 59|2@0+ (1,0) [0|3] ""  FMCU,PCU
 SG_ CVC_FMCU_ActiveHeatingReq : 62|3@0+ (1,0) [0|8] "kW"  FMCU,PCU
 SG_ Secure_ResetCnt_0x0AB : 135|16@0+ (1,0) [0|65535] ""  FMCU,PCU
 SG_ Secure_MsgCnt_0x0AB : 151|16@0+ (1,0) [0|65535] ""  FMCU,PCU
 SG_ Secure_MAC_0x0AB : 167|32@0+ (1,0) [0|4294967295] ""  FMCU,PCU

BO_ 172 CVC_RMCU_Ctrl: 24 CVC_P
 SG_ CRC_CVC_RMCU_Ctrl : 7|8@0+ (1,0) [0|255] ""  RMCU,PCU
 SG_ ALIVE_CVC_RMCU_Ctrl : 11|4@0+ (1,0) [0|15] ""  RMCU,PCU
 SG_ CVC_RMCU_TargetTqReq : 23|16@0+ (0.1,-400) [-400|400] "Nm"  RMCU,PCU
 SG_ CVC_RMCU_TargetSpeedReq : 39|16@0+ (1,-20000) [-20000|45535] "rpm"  RMCU
 SG_ CVC_RMCU_StsModeReq : 51|4@0+ (1,0) [0|15] ""  RMCU
 SG_ CVC_RMCU_Oil_Pump_Relay_Sts : 53|1@0+ (1,0) [0|1] ""  RMCU
 SG_ CVC_RMCU_TargetTqReqV : 54|1@0+ (1,0) [0|1] ""  RMCU
 SG_ CVC_RMCU_TargetSpeedReqV : 55|1@0+ (1,0) [0|1] ""  RMCU
 SG_ CVC_RMCU_VehicleDirect : 56|1@0+ (1,0) [0|1] ""  RMCU
 SG_ CVC_RMCU_AtvDischg_Req : 57|1@0+ (1,0) [0|1] ""  RMCU
 SG_ CVC_RMCU_CtrlModeReq : 59|2@0+ (1,0) [0|3] ""  RMCU
 SG_ CVC_RMCU_ActiveHeatingReq : 62|3@0+ (1,0) [0|8] "kW"  RMCU
 SG_ Secure_ResetCnt_0x0AC : 135|16@0+ (1,0) [0|65535] ""  RMCU
 SG_ Secure_MsgCnt_0x0AC : 151|16@0+ (1,0) [0|65535] ""  RMCU
 SG_ Secure_MAC_0x0AC : 167|32@0+ (1,0) [0|4294967295] ""  RMCU

BO_ 217 CVC_HV_DrvSys_status: 8 CVC_P
 SG_ CRC_CVC_HV_DrvSys_status : 7|8@0+ (1,0) [0|255] ""  EVCC,FMCU,RMCU,POD_GW,PCU,ADCU_P
 SG_ ALIVE_CVC_HV_DrvSys_status : 11|4@0+ (1,0) [0|15] ""  EVCC,FMCU,RMCU,POD_GW,PCU,ADCU_P
 SG_ CVC_HVsystem_status : 14|3@0+ (1,0) [0|7] ""  EVCC,FMCU,RMCU,POD_GW,PCU,ADCU_P
 SG_ CVC_ACPD_Percent : 23|12@0+ (0.0625,0) [0|100] "%"  EVCC,FMCU,RMCU,POD_GW,PCU,ADCU_P
 SG_ CVC_ACPD_Percent_Valid : 27|1@0+ (1,0) [0|1] ""  EVCC,FMCU,RMCU,POD_GW,PCU,ADCU_P
 SG_ CVC_ACTGear : 34|3@0+ (1,0) [0|7] ""  EVCC,FMCU,RMCU,POD_GW,PCU,ADCU_P
 SG_ CVC_ACTGearValid : 35|1@0+ (1,0) [0|1] ""  EVCC,FMCU,RMCU,POD_GW,PCU,ADCU_P
 SG_ CVC_ACT_DriveMode : 38|3@0+ (1,0) [0|7] ""  EVCC,FMCU,RMCU,POD_GW,PCU,ADCU_P
 SG_ CVC_ACT_DriveMode_Valid : 39|1@0+ (1,0) [0|1] ""  EVCC,FMCU,RMCU,POD_GW,PCU,ADCU_P
 SG_ CVC_HV_DRVsystem_status : 43|3@0+ (1,0) [0|7] ""  EVCC,FMCU,RMCU,POD_GW,PCU,ADCU_P
 SG_ CVC_Recu_BrakeLight_ON_Req : 45|2@0+ (1,0) [0|3] ""  EVCC,FMCU,RMCU,POD_GW,PCU,ADCU_P
 SG_ CVC_AccPedal_Valid : 47|1@0+ (1,0) [0|1] ""  FMCU,PCU
 SG_ CVC_StsAccPedalFault : 46|1@0+ (1,0) [0|1] ""  FMCU,PCU
 SG_ CVC_StsSysFault : 55|4@0+ (1,0) [0|15] ""  FMCU,PCU
 SG_ CVC_AccPedalPosition : 63|8@0+ (0.4,0) [0|100] "%"  FMCU,PCU

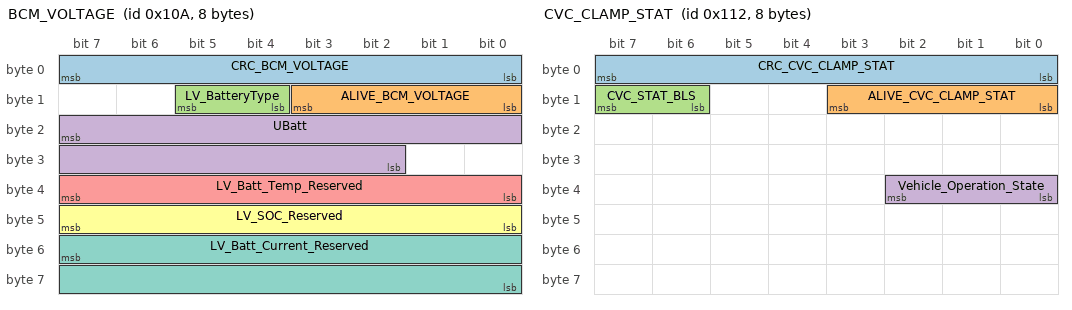
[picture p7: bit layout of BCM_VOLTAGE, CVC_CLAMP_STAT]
BO_ 266 BCM_VOLTAGE: 8 CVC_P
 SG_ CRC_BCM_VOLTAGE : 7|8@0+ (1,0) [0|255] ""  BMS,EVCC,FMCU,RMCU,POD_GW,PCU,ADCU_P
 SG_ ALIVE_BCM_VOLTAGE : 11|4@0+ (1,0) [0|15] ""  BMS,EVCC,FMCU,RMCU,POD_GW,PCU,ADCU_P
 SG_ LV_BatteryType : 13|2@0+ (1,0) [0|3] ""  BMS,EVCC,FMCU,RMCU,POD_GW,PCU,ADCU_P
 SG_ UBatt : 23|14@0+ (0.0009777,3) [3|18] "V"  BMS,EVCC,FMCU,RMCU,POD_GW,PCU,ADCU_P
 SG_ LV_Batt_Temp_Reserved : 39|8@0+ (1,-40) [-40|105] "Degree C" Vector__XXX
 SG_ LV_SOC_Reserved : 47|8@0+ (1,0) [0|100] "%"  BMS,EVCC,FMCU,RMCU,POD_GW,PCU,ADCU_P
 SG_ LV_Batt_Current_Reserved : 55|16@0+ (0.03125,-1536) [-1536|511.90625] "A"  BMS,EVCC,FMCU,RMCU,POD_GW,PCU,ADCU_P

BO_ 274 CVC_CLAMP_STAT: 8 CVC_P
 SG_ CRC_CVC_CLAMP_STAT : 7|8@0+ (1,0) [0|255] ""  BMS,EVCC,FMCU,RMCU,POD_GW,PCU,ADCU_P
 SG_ ALIVE_CVC_CLAMP_STAT : 11|4@0+ (1,0) [0|15] ""  BMS,EVCC,FMCU,RMCU,POD_GW,PCU,ADCU_P
 SG_ CVC_STAT_BLS : 15|2@0+ (1,0) [0|3] ""  BMS,EVCC,FMCU,RMCU,POD_GW,PCU,ADCU_P
 SG_ Vehicle_Operation_State : 34|3@0+ (1,0) [0|7] ""  BMS,EVCC,FMCU,RMCU,POD_GW,PCU,ADCU_P

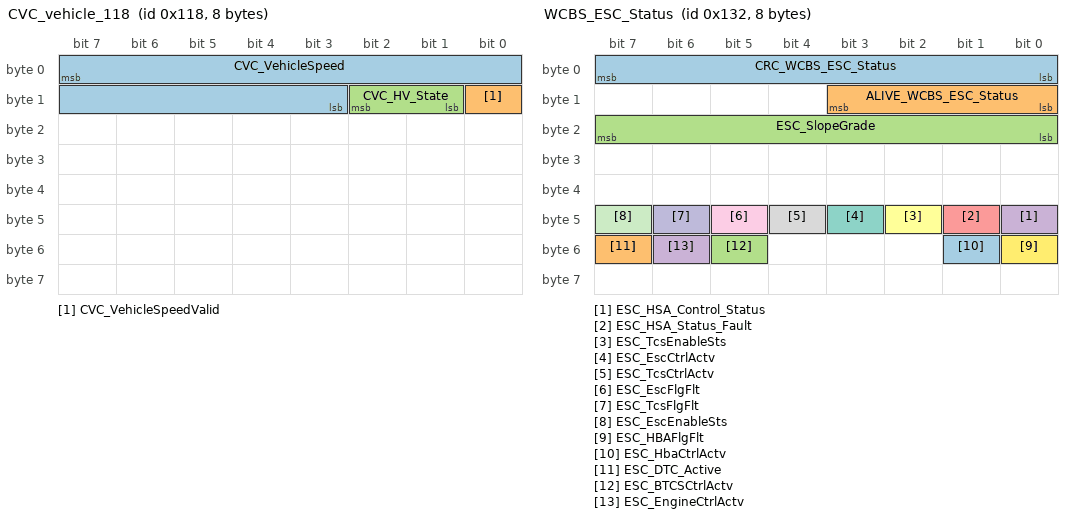
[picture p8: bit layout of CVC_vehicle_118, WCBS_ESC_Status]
BO_ 280 CVC_vehicle_118: 8 CVC_P
 SG_ CVC_VehicleSpeed : 7|13@0+ (0.05625,0) [0|270] "km/h"  BMS,PCU
 SG_ CVC_VehicleSpeedValid : 8|1@0+ (1,0) [0|1] ""  BMS,PCU
 SG_ CVC_HV_State : 10|2@0+ (1,0) [0|3] ""  BMS,PCU

BO_ 306 WCBS_ESC_Status: 8 CVC_P
 SG_ CRC_WCBS_ESC_Status : 7|8@0+ (1,0) [0|255] ""  FMCU,RMCU,PCU
 SG_ ALIVE_WCBS_ESC_Status : 11|4@0+ (1,0) [0|15] ""  FMCU,RMCU,PCU
 SG_ ESC_SlopeGrade : 23|8@0+ (1,-30) [-30|30] "%"  FMCU,RMCU,PCU
 SG_ ESC_HSA_Control_Status : 40|1@0+ (1,0) [0|1] ""  FMCU,RMCU,PCU
 SG_ ESC_HSA_Status_Fault : 41|1@0+ (1,0) [0|1] ""  FMCU,RMCU,PCU
 SG_ ESC_TcsEnableSts : 42|1@0+ (1,0) [0|1] ""  FMCU,RMCU,PCU
 SG_ ESC_EscCtrlActv : 43|1@0+ (1,0) [0|1] ""  FMCU,RMCU,PCU
 SG_ ESC_TcsCtrlActv : 44|1@0+ (1,0) [0|1] ""  FMCU,RMCU,PCU
 SG_ ESC_EscFlgFlt : 45|1@0+ (1,0) [0|1] ""  FMCU,RMCU,PCU
 SG_ ESC_TcsFlgFlt : 46|1@0+ (1,0) [0|1] ""  FMCU,RMCU,PCU
 SG_ ESC_EscEnableSts : 47|1@0+ (1,0) [0|1] ""  FMCU,RMCU,PCU
 SG_ ESC_HBAFlgFlt : 48|1@0+ (1,0) [0|1] ""  FMCU,RMCU,PCU
 SG_ ESC_HbaCtrlActv : 49|1@0+ (1,0) [0|1] ""  FMCU,RMCU,PCU
 SG_ ESC_DTC_Active : 55|1@0+ (1,0) [0|1] ""  FMCU,RMCU,PCU
 SG_ ESC_BTCSCtrlActv : 53|1@0+ (1,0) [0|1] ""  FMCU,RMCU,PCU
 SG_ ESC_EngineCtrlActv : 54|1@0+ (1,0) [0|1] ""  FMCU,RMCU,PCU

BO_ 344 CVC_EngineControl: 12 CVC_P
 SG_ CRC_CVC_EngineControl : 7|8@0+ (1,0) [0|255] ""  PCU
 SG_ ALIVE_CVC_EngineControl : 11|4@0+ (1,0) [0|15] ""  PCU
 SG_ CVC_REX_Mode : 13|2@0+ (1,0) [0|3] ""  DUMMY_ECU
 SG_ CVC_PCU_StopReq : 23|2@0+ (1,0) [0|3] ""  PCU
 SG_ CVC_PCU_StartReq : 21|2@0+ (1,0) [0|3] ""  PCU
 SG_ CVC_PCU_ActvDischg_Req : 19|2@0+ (1,0) [0|3] ""  PCU
 SG_ CVC_PCU_GenTargetPower : 17|12@0+ (0.2,0) [0|800] "kW"  PCU
 SG_ CVC_PCU_GenTargetVolt : 37|14@0+ (0.1,0) [0|1500] "V"  PCU
 SG_ CVC_PCU_GenTargetCurr : 55|16@0+ (0.1,-3276.8) [-3276.8|3276.7] "A"  PCU
 SG_ CVC_PCU_CurveSelection : 71|3@0+ (1,0) [0|7] ""  PCU

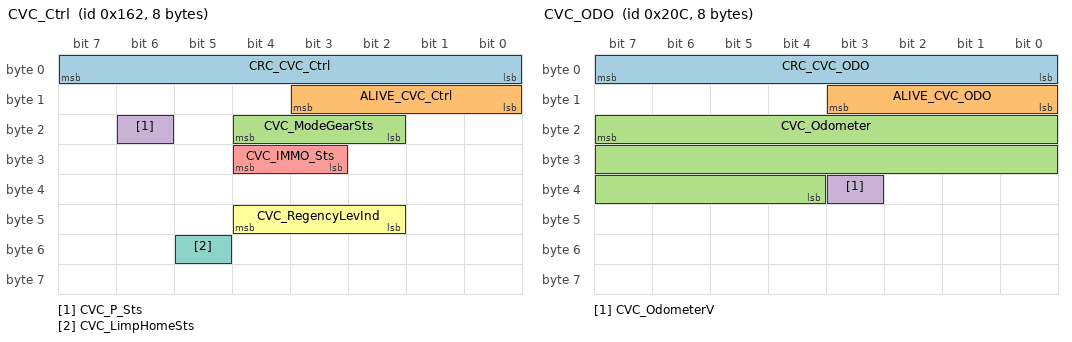
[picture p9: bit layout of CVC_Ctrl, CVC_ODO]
BO_ 354 CVC_Ctrl: 8 CVC_P
 SG_ CRC_CVC_Ctrl : 7|8@0+ (1,0) [0|255] ""  EVCC,FMCU,RMCU,POD_GW,PCU,ADCU_P
 SG_ ALIVE_CVC_Ctrl : 11|4@0+ (1,0) [0|15] ""  EVCC,FMCU,RMCU,POD_GW,PCU,ADCU_P
 SG_ CVC_ModeGearSts : 20|3@0+ (1,0) [0|7] ""  EVCC,FMCU,RMCU,PCU
 SG_ CVC_P_Sts : 22|1@0+ (1,0) [0|1] ""  EVCC,FMCU,RMCU,POD_GW,PCU
 SG_ CVC_IMMO_Sts : 28|2@0+ (1,0) [0|3] ""  EVCC,FMCU,RMCU,POD_GW,PCU,ADCU_P
 SG_ CVC_RegencyLevInd : 44|3@0+ (1,0) [0|7] ""  EVCC,FMCU,RMCU,POD_GW,PCU,ADCU_P
 SG_ CVC_LimpHomeSts : 53|1@0+ (1,0) [0|1] ""  EVCC,FMCU,RMCU,POD_GW,PCU,ADCU_P

BO_ 358 CVC_Status: 12 CVC_P
 SG_ CRC_CVC_Status : 7|8@0+ (1,0) [0|255] ""  FMCU,RMCU,PCU
 SG_ ALIVE_CVC_Status : 11|4@0+ (1,0) [0|15] ""  FMCU,RMCU,PCU
 SG_ CVC_DriveModeSts : 18|3@0+ (1,0) [0|7] ""  FMCU,RMCU,PCU
 SG_ CVC_DriveReady : 19|1@0+ (1,0) [0|1] ""  FMCU,RMCU,PCU
 SG_ CVC_Fault : 22|3@0+ (1,0) [0|7] ""  FMCU,RMCU,PCU
 SG_ CVC_VecFltInd : 23|1@0+ (1,0) [0|1] ""  FMCU,RMCU,PCU
 SG_ CVC_Creep_Sts : 25|2@0+ (1,0) [0|3] ""  FMCU,RMCU,PCU
 SG_ CVC_CruiseCtrlSts : 55|3@0+ (1,0) [0|7] ""  FMCU,RMCU,PCU
 SG_ CVC_StsBrakePedalSwitch : 29|2@0+ (1,0) [0|3] ""  FMCU,RMCU,PCU
 SG_ CVC_VehicleMode : 31|2@0+ (1,0) [0|3] ""  FMCU,RMCU,PCU
 SG_ CVC_CruiseSetSpd : 39|8@0+ (1,0) [30|120] ""  FMCU,RMCU,PCU
 SG_ CVC_CruiseFaultIndication : 41|2@0+ (1,0) [0|3] ""  FMCU,RMCU,PCU
 SG_ CVC_FuelDetectionSwitchState : 43|2@0+ (1,0) [0|3] ""  FMCU,RMCU,PCU
 SG_ CVC_FuelDetectionState : 45|2@0+ (1,0) [0|3] ""  FMCU,RMCU,PCU
 SG_ CVC_ParkingChargeRequest : 47|2@0+ (1,0) [0|3] ""  FMCU,RMCU,PCU
 SG_ CVC_ParkingChargeModeSet : 51|2@0+ (1,0) [0|3] ""  FMCU,RMCU,PCU
 SG_ CVC_REX_StartTimer : 49|10@0+ (1,0) [0|1023] "s"  DUMMY_ECU
 SG_ LV_EM_Rampup_Req : 15|2@0+ (1,0) [0|3] ""  DUMMY_ECU
 SG_ LV_PowerSupply_Status : 52|1@0+ (1,0) [0|1] ""  DUMMY_ECU
 SG_ LV_EM_OTA_Req : 27|2@0+ (1,0) [0|3] ""  DUMMY_ECU
 SG_ CVC_STAT_AirDistributionModeLH : 71|3@0+ (1,0) [0|7] ""  DUMMY_ECU
 SG_ CVC_STAT_AirDistributionModeRH : 68|3@0+ (1,0) [0|7] ""  DUMMY_ECU
 SG_ CVC_STAT_DriverOnly : 65|2@0+ (1,0) [0|3] ""  DUMMY_ECU

BO_ 524 CVC_ODO: 8 CVC_P
 SG_ CRC_CVC_ODO : 7|8@0+ (1,0) [0|255] ""  BMS,EVCC,FMCU,RMCU,POD_GW,PCU
 SG_ ALIVE_CVC_ODO : 11|4@0+ (1,0) [0|15] ""  BMS,EVCC,FMCU,RMCU,POD_GW,PCU
 SG_ CVC_Odometer : 23|20@0+ (1,0) [0|999999] "km"  BMS,EVCC,FMCU,RMCU,POD_GW,PCU
 SG_ CVC_OdometerV : 35|1@0+ (1,0) [0|1] ""  BMS,EVCC,FMCU,RMCU,POD_GW,PCU

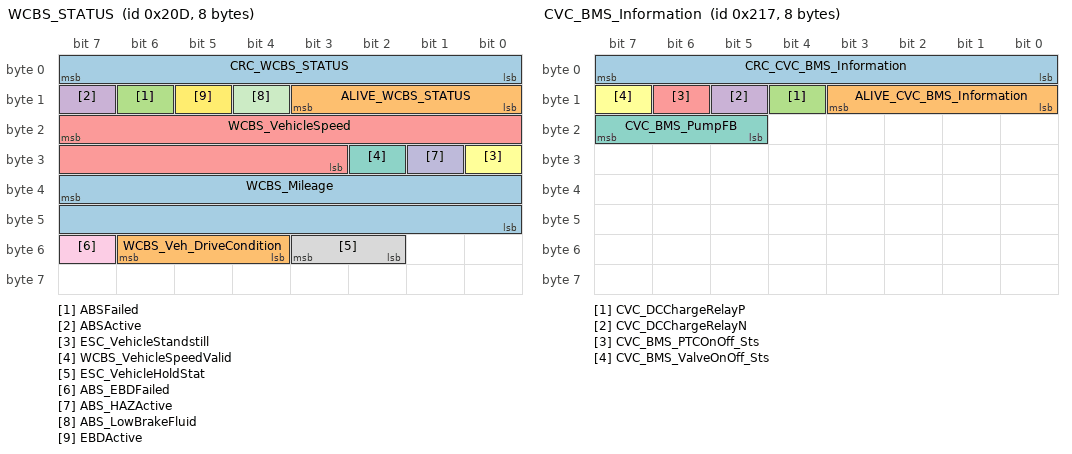
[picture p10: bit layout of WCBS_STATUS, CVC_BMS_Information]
BO_ 525 WCBS_STATUS: 8 CVC_P
 SG_ CRC_WCBS_STATUS : 7|8@0+ (1,0) [0|255] ""  BMS,EVCC,FMCU,RMCU,POD_GW,PCU
 SG_ ALIVE_WCBS_STATUS : 11|4@0+ (1,0) [0|15] ""  BMS,EVCC,FMCU,RMCU,POD_GW,PCU
 SG_ ABSFailed : 14|1@0+ (1,0) [0|1] ""  BMS,EVCC,FMCU,RMCU,POD_GW,PCU
 SG_ ABSActive : 15|1@0+ (1,0) [0|1] ""  BMS,EVCC,FMCU,RMCU,POD_GW,PCU
 SG_ WCBS_VehicleSpeed : 23|13@0+ (0.05625,0) [0|300] "km/h"  BMS,EVCC,FMCU,RMCU,POD_GW,PCU
 SG_ ESC_VehicleStandstill : 24|1@0+ (1,0) [0|1] ""  BMS,EVCC,FMCU,RMCU,POD_GW,PCU
 SG_ WCBS_VehicleSpeedValid : 26|1@0+ (1,0) [0|1] ""  BMS,EVCC,FMCU,RMCU,POD_GW,PCU
 SG_ ESC_VehicleHoldStat : 51|2@0+ (1,0) [0|3] ""  BMS,EVCC,FMCU,RMCU,POD_GW,PCU
 SG_ ABS_EBDFailed : 55|1@0+ (1,0) [0|1] ""  BMS,EVCC,FMCU,RMCU,POD_GW,PCU
 SG_ ABS_HAZActive : 25|1@0+ (1,0) [0|1] ""  BMS,EVCC,FMCU,RMCU,POD_GW,PCU
 SG_ ABS_LowBrakeFluid : 12|1@0+ (1,0) [0|1] ""  BMS,EVCC,FMCU,RMCU,POD_GW,PCU
 SG_ EBDActive : 13|1@0+ (1,0) [0|1] ""  BMS,EVCC,FMCU,RMCU,POD_GW,PCU
 SG_ WCBS_Mileage : 39|16@0+ (1,0) [0|65535] "cm"  BMS,EVCC,FMCU,RMCU,POD_GW,PCU
 SG_ WCBS_Veh_DriveCondition : 54|3@0+ (1,0) [0|7] ""  BMS,EVCC,FMCU,RMCU,POD_GW,PCU

BO_ 535 CVC_BMS_Information: 8 CVC_P
 SG_ CRC_CVC_BMS_Information : 7|8@0+ (1,0) [0|255] ""  BMS
 SG_ ALIVE_CVC_BMS_Information : 11|4@0+ (1,0) [0|15] ""  BMS
 SG_ CVC_DCChargeRelayP : 12|1@0+ (1,0) [0|1] ""  BMS
 SG_ CVC_DCChargeRelayN : 13|1@0+ (1,0) [0|1] ""  BMS
 SG_ CVC_BMS_PTCOnOff_Sts : 14|1@0+ (1,0) [0|1] ""  BMS
 SG_ CVC_BMS_ValveOnOff_Sts : 15|1@0+ (1,0) [0|1] ""  BMS
 SG_ CVC_BMS_PumpFB : 23|3@0+ (1,0) [0|3] ""  BMS

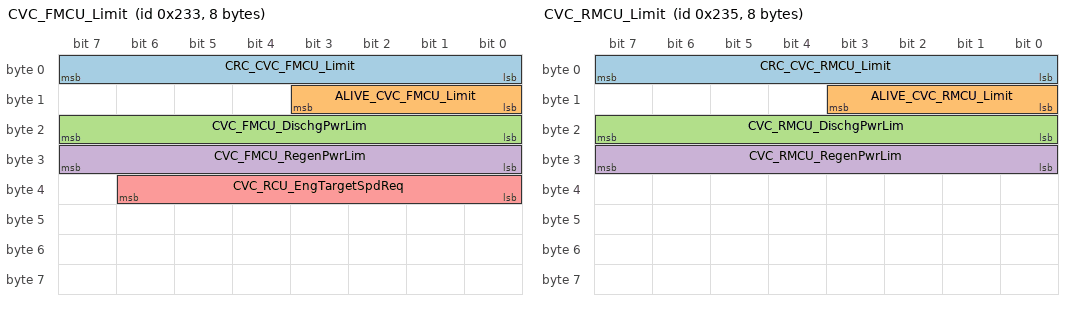
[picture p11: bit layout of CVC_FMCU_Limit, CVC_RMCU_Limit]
BO_ 563 CVC_FMCU_Limit: 8 CVC_P
 SG_ CRC_CVC_FMCU_Limit : 7|8@0+ (1,0) [0|255] ""  FMCU,PCU
 SG_ ALIVE_CVC_FMCU_Limit : 11|4@0+ (1,0) [0|15] ""  FMCU,PCU
 SG_ CVC_FMCU_DischgPwrLim : 23|8@0+ (1,0) [0|250] "kw"  FMCU,PCU
 SG_ CVC_FMCU_RegenPwrLim : 31|8@0+ (1,0) [0|250] "kw"  FMCU,PCU
 SG_ CVC_RCU_EngTargetSpdReq : 38|7@0+ (100,0) [0|800] "rpm"  PCU

BO_ 565 CVC_RMCU_Limit: 8 CVC_P
 SG_ CRC_CVC_RMCU_Limit : 7|8@0+ (1,0) [0|255] ""  RMCU
 SG_ ALIVE_CVC_RMCU_Limit : 11|4@0+ (1,0) [0|15] ""  RMCU
 SG_ CVC_RMCU_DischgPwrLim : 23|8@0+ (1,0) [0|250] "kw"  RMCU
 SG_ CVC_RMCU_RegenPwrLim : 31|8@0+ (1,0) [0|250] "kw"  RMCU

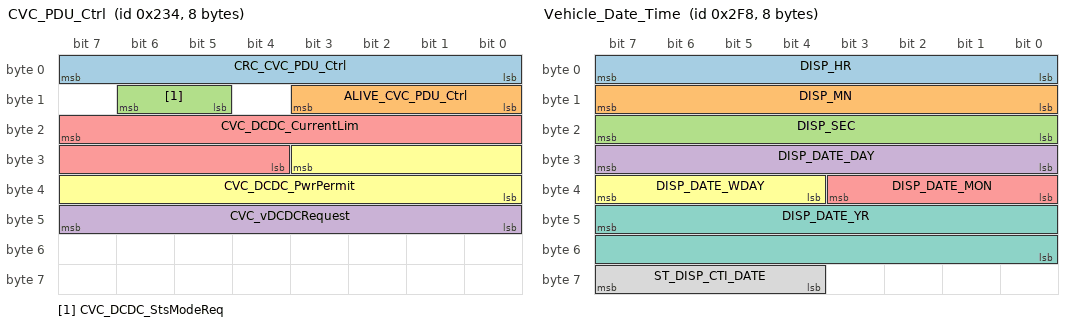
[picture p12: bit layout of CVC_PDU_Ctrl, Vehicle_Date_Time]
BO_ 564 CVC_PDU_Ctrl: 8 CVC_P
 SG_ CRC_CVC_PDU_Ctrl : 7|8@0+ (1,0) [0|255] ""  POD_GW
 SG_ ALIVE_CVC_PDU_Ctrl : 11|4@0+ (1,0) [0|15] ""  POD_GW
 SG_ CVC_DCDC_StsModeReq : 14|2@0+ (1,0) [0|3] ""  POD_GW
 SG_ CVC_vDCDCRequest : 47|8@0+ (0.0625,0) [9|15.9375] "V"  POD_GW
 SG_ CVC_DCDC_CurrentLim : 23|12@0+ (0.1,0) [0|250] "A"  POD_GW
 SG_ CVC_DCDC_PwrPermit : 27|12@0+ (1,0) [0|3000] "W"  POD_GW

BO_ 746 CVC_Temp: 16 CVC_P
 SG_ InteriorTemperature : 7|12@0+ (0.1,-80) [-80|329] "Degree C"  BMS,EVCC,FMCU,RMCU,POD_GW,PCU
 SG_ CVC_SW_Versions : 23|16@0+ (1,0) [0|255] ""  DUMMY_ECU
 SG_ CVC_Fan_Sts : 33|2@0+ (1,0) [0|3] ""  DUMMY_ECU
 SG_ CVC_DCChgPosTemp : 47|8@0+ (1,-40) [-40|210] "Degree C"  DUMMY_ECU
 SG_ CVC_DCChgNegTemp : 55|8@0+ (1,-40) [-40|210] "Degree C"  DUMMY_ECU
 SG_ CVC_ACChgLTerminalTemp : 63|8@0+ (1,-40) [-40|210] "Degree C"  DUMMY_ECU
 SG_ CVC_ACChgNTerminalTemp_Reserve : 71|8@0+ (1,-40) [-40|210] "Degree C"  DUMMY_ECU
 SG_ CVC_EdrivePump_Sts : 77|2@0+ (1,0) [0|3] ""  DUMMY_ECU
 SG_ CVC_BatPump_Sts : 79|2@0+ (1,0) [0|3] ""  DUMMY_ECU
 SG_ CVC_ActiveHeatingPower : 87|16@0+ (0.2,0) [0|8000] "kW"  DUMMY_ECU

BO_ 760 Vehicle_Date_Time: 8 CVC_P
 SG_ DISP_HR : 7|8@0+ (1,0) [0|23] "h"  BMS,EVCC,FMCU,RMCU,POD_GW,PCU
 SG_ DISP_MN : 15|8@0+ (1,0) [0|59] "min"  BMS,EVCC,FMCU,RMCU,POD_GW,PCU
 SG_ DISP_SEC : 23|8@0+ (1,0) [0|59] "s"  BMS,EVCC,FMCU,RMCU,POD_GW,PCU
 SG_ DISP_DATE_DAY : 31|8@0+ (1,0) [1|31] "Day"  BMS,EVCC,FMCU,RMCU,POD_GW,PCU
 SG_ DISP_DATE_MON : 35|4@0+ (1,0) [1|12] "Month"  BMS,EVCC,FMCU,RMCU,POD_GW,PCU
 SG_ DISP_DATE_WDAY : 39|4@0+ (1,0) [0|15] ""  BMS,EVCC,FMCU,RMCU,POD_GW,PCU
 SG_ DISP_DATE_YR : 47|16@0+ (1,0) [1|65534] "Year"  BMS,EVCC,FMCU,RMCU,POD_GW,PCU
 SG_ ST_DISP_CTI_DATE : 63|4@0+ (1,0) [0|15] ""  BMS,EVCC,FMCU,RMCU,POD_GW,PCU

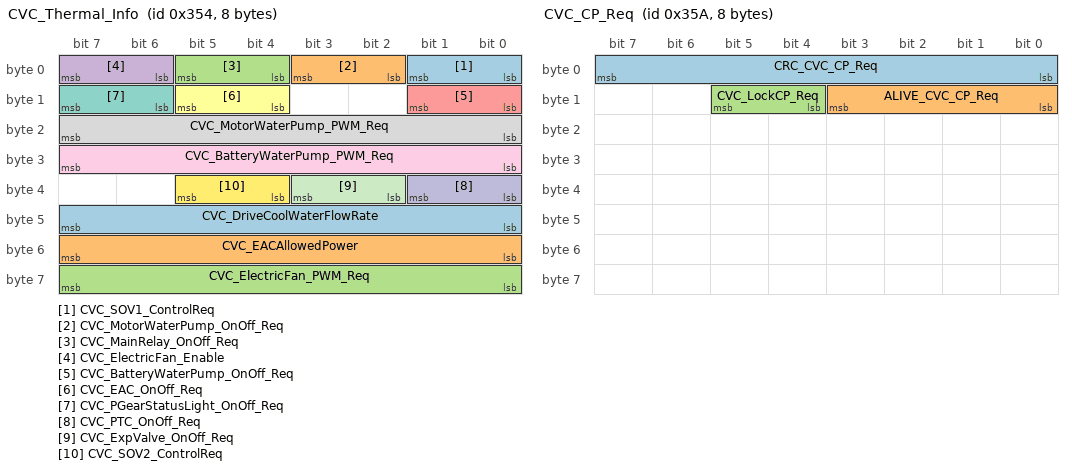
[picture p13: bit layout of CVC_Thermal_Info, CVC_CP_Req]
BO_ 852 CVC_Thermal_Info: 8 CVC_P
 SG_ CVC_SOV1_ControlReq : 1|2@0+ (1,0) [0|3] ""  EVCC,PCU
 SG_ CVC_MotorWaterPump_OnOff_Req : 3|2@0+ (1,0) [0|3] ""  EVCC,PCU
 SG_ CVC_MainRelay_OnOff_Req : 5|2@0+ (1,0) [0|3] ""  EVCC,PCU
 SG_ CVC_ElectricFan_Enable : 7|2@0+ (1,0) [0|3] ""  EVCC,PCU
 SG_ CVC_BatteryWaterPump_OnOff_Req : 9|2@0+ (1,0) [0|3] ""  EVCC,PCU
 SG_ CVC_EAC_OnOff_Req : 13|2@0+ (1,0) [0|3] ""  EVCC,PCU
 SG_ CVC_PGearStatusLight_OnOff_Req : 15|2@0+ (1,0) [0|3] ""  EVCC,PCU
 SG_ CVC_MotorWaterPump_PWM_Req : 23|8@0+ (1,0) [0|100] "%"  EVCC,PCU
 SG_ CVC_BatteryWaterPump_PWM_Req : 31|8@0+ (1,0) [0|100] "%"  EVCC,PCU
 SG_ CVC_PTC_OnOff_Req : 33|2@0+ (1,0) [0|3] ""  EVCC,PCU
 SG_ CVC_ExpValve_OnOff_Req : 35|2@0+ (1,0) [0|3] ""  EVCC,PCU
 SG_ CVC_SOV2_ControlReq : 37|2@0+ (1,0) [0|3] ""  EVCC,PCU
 SG_ CVC_DriveCoolWaterFlowRate : 47|8@0+ (0.1,0) [0|25] "L/min"  FMCU,RMCU,PCU
 SG_ CVC_EACAllowedPower : 55|8@0+ (40,0) [0|10200] "W"  PCU
 SG_ CVC_ElectricFan_PWM_Req : 63|8@0+ (1,0) [0|100] "%"  EVCC,PCU

BO_ 858 CVC_CP_Req: 8 CVC_P
 SG_ CRC_CVC_CP_Req : 7|8@0+ (1,0) [0|255] ""  EVCC
 SG_ ALIVE_CVC_CP_Req : 11|4@0+ (1,0) [0|15] ""  EVCC
 SG_ CVC_LockCP_Req : 13|2@0+ (1,0) [0|3] ""  EVCC

BO_ 862 CVC_Vehicle_info: 16 CVC_P
 SG_ CRC_CVC_Vehicle_info : 7|8@0+ (1,0) [0|255] ""  BMS,EVCC,POD_GW
 SG_ ALIVE_CVC_Vehicle_info : 11|4@0+ (1,0) [0|15] ""  BMS,EVCC,POD_GW
 SG_ CVC_VehLock_STS : 13|2@0+ (1,0) [0|3] ""  EVCC
 SG_ CVC_VehSpd_ScreenDisplay : 23|8@0+ (1,0) [0|254] ""  EVCC
 SG_ CVC_VehChgAllow : 25|2@0+ (1,0) [0|3] ""  BMS,EVCC,POD_GW
 SG_ CVC_VehDischgAllow : 15|2@0+ (1,0) [0|3] ""  BMS,EVCC,POD_GW
 SG_ Re_InitCharging_Req : 27|2@0+ (1,0) [0|3] ""  EVCC
 SG_ CVC_StopChg_Req : 28|1@0+ (1,0) [0|1] ""  EVCC
 SG_ CVC_GunUnlock_Req : 30|2@0+ (1,0) [0|3] ""  EVCC
 SG_ CVC_Ack_LimitSetting_SOC : 39|7@0+ (1,0) [0|100] "%"  BMS,EVCC
 SG_ CVC_ACInputChgCurLim : 47|6@0+ (1,0) [0|48] "A"  EVCC
 SG_ CVC_HV_DispSOC : 41|10@0+ (0.1,0) [0|100] "%"  EVCC
 SG_ CVC_HV_Cur_LoadComp : 63|10@0+ (0.1,0) [0|100] "A"  EVCC

BO_ 884 CVC_PTC_Info1: 8 CVC_P
 SG_ PTC_PCBT : 23|8@0+ (1,-48) [-48|207] "Degree C" Vector__XXX
 SG_ PTC_Crt : 31|16@0+ (0.001,0) [0|65.535] "A"  PCU
 SG_ PTC_CrtSts : 41|2@0+ (1,0) [0|3] "" Vector__XXX
 SG_ PTC_HVIntlkFlt : 42|1@0+ (1,0) [0|1] "" Vector__XXX
 SG_ PTC_ComLost_ECC : 43|1@0+ (1,0) [0|1] "" Vector__XXX
 SG_ PTC_OverCrtFlt : 44|1@0+ (1,0) [0|1] "" Vector__XXX
 SG_ PTC_HVUnderVoltFlt : 45|1@0+ (1,0) [0|1] "" Vector__XXX
 SG_ PTC_HVOverVoltFlt : 46|1@0+ (1,0) [0|1] "" Vector__XXX
 SG_ PTC_ChkBattOverVoltFlt : 47|1@0+ (1,0) [0|1] "" Vector__XXX
 SG_ PTC_ChkBattUnderVoltFlt : 48|1@0+ (1,0) [0|1] "" Vector__XXX
 SG_ PTC_InlTSnsrFlt : 49|1@0+ (1,0) [0|1] "" Vector__XXX
 SG_ PTC_OutlTSnsrFlt : 50|1@0+ (1,0) [0|1] "" Vector__XXX
 SG_ PTC_InlOverTFlt : 51|1@0+ (1,0) [0|1] "" Vector__XXX
 SG_ PTC_OutlOverTFlt : 52|1@0+ (1,0) [0|1] "" Vector__XXX
 SG_ PTC_PCBOverTFlt : 53|1@0+ (1,0) [0|1] "" Vector__XXX
 SG_ PTC_PCBTSnsrFlt : 54|1@0+ (1,0) [0|1] "" Vector__XXX
 SG_ PTC_PwrOutpFlt : 55|1@0+ (1,0) [0|1] "" Vector__XXX

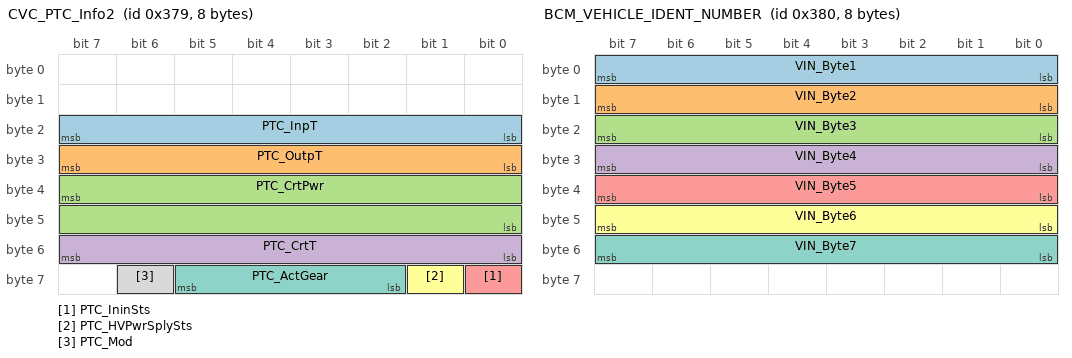
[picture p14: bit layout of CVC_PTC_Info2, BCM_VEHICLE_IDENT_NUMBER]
BO_ 889 CVC_PTC_Info2: 8 CVC_P
 SG_ PTC_InpT : 23|8@0+ (1,-48) [-48|207] "Degree C" Vector__XXX
 SG_ PTC_OutpT : 31|8@0+ (1,-48) [-48|207] "Degree C" Vector__XXX
 SG_ PTC_CrtPwr : 39|16@0+ (1,0) [0|10000] "W"  PCU
 SG_ PTC_CrtT : 55|8@0+ (1,-48) [-48|207] "Degree C" Vector__XXX
 SG_ PTC_IninSts : 56|1@0+ (1,0) [0|1] "" Vector__XXX
 SG_ PTC_HVPwrSplySts : 57|1@0+ (1,0) [0|1] "" Vector__XXX
 SG_ PTC_ActGear : 61|4@0+ (1,0) [0|15] "" Vector__XXX
 SG_ PTC_Mod : 62|1@0+ (1,0) [0|1] "" Vector__XXX

BO_ 891 CVC_SOV_Sts: 8 CVC_P
 SG_ CVC_Front_SOV_OnOff_Sts : 1|2@0+ (1,0) [0|3] ""  DUMMY_ECU
 SG_ CVC_Rear_SOV_OnOff_Sts : 3|2@0+ (1,0) [0|3] ""  DUMMY_ECU

BO_ 896 BCM_VEHICLE_IDENT_NUMBER: 8 CVC_P
 SG_ VIN_Byte1 : 7|8@0+ (1,0) [0|255] ""  FMCU,RMCU,POD_GW,PCU
 SG_ VIN_Byte2 : 15|8@0+ (1,0) [0|255] ""  FMCU,RMCU,POD_GW,PCU
 SG_ VIN_Byte3 : 23|8@0+ (1,0) [0|255] ""  FMCU,RMCU,POD_GW,PCU
 SG_ VIN_Byte4 : 31|8@0+ (1,0) [0|255] ""  FMCU,RMCU,POD_GW,PCU
 SG_ VIN_Byte5 : 39|8@0+ (1,0) [0|255] ""  FMCU,RMCU,POD_GW,PCU
 SG_ VIN_Byte6 : 47|8@0+ (1,0) [0|255] ""  FMCU,RMCU,POD_GW,PCU
 SG_ VIN_Byte7 : 55|8@0+ (1,0) [0|255] ""  FMCU,RMCU,POD_GW,PCU

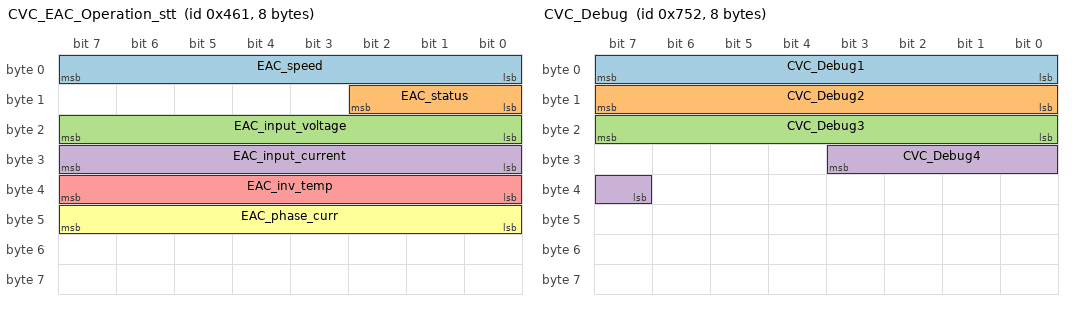
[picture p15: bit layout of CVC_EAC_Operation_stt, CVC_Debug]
BO_ 1121 CVC_EAC_Operation_stt: 8 CVC_P
 SG_ EAC_speed : 7|8@0+ (50,0) [0|12750] "rpm" Vector__XXX
 SG_ EAC_status : 10|3@0+ (1,0) [0|7] "" Vector__XXX
 SG_ EAC_input_voltage : 23|8@0+ (2,0) [0|510] "V"  PCU
 SG_ EAC_input_current : 31|8@0+ (0.5,0) [0|127.5] "A"  PCU
 SG_ EAC_inv_temp : 39|8@0+ (1,-50) [-50|205] "Degree C" Vector__XXX
 SG_ EAC_phase_curr : 47|8@0+ (0.5,0) [0|127.5] "A" Vector__XXX

BO_ 1873 CVC_DebugDiag: 8 CVC_P
 SG_ CVC_DebugDiag2 : 4|3@0+ (1,0) [0|4] ""  DUMMY_ECU
 SG_ CVC_DebugDiag1 : 7|3@0+ (1,0) [0|4] ""  DUMMY_ECU
 SG_ CVC_DebugDiag5 : 9|3@0+ (1,0) [0|4] ""  DUMMY_ECU
 SG_ CVC_DebugDiag4 : 12|3@0+ (1,0) [0|4] ""  DUMMY_ECU
 SG_ CVC_DebugDiag3 : 15|3@0+ (1,0) [0|4] ""  DUMMY_ECU
 SG_ CVC_DebugDiag8 : 16|3@0+ (1,0) [0|4] ""  DUMMY_ECU
 SG_ CVC_DebugDiag7 : 19|3@0+ (1,0) [0|4] ""  DUMMY_ECU
 SG_ CVC_DebugDiag6 : 22|3@0+ (1,0) [0|4] ""  DUMMY_ECU
 SG_ CVC_DebugDiag10 : 26|3@0+ (1,0) [0|4] ""  DUMMY_ECU
 SG_ CVC_DebugDiag9 : 29|3@0+ (1,0) [0|4] ""  DUMMY_ECU
 SG_ CVC_DebugDiag13 : 33|3@0+ (1,0) [0|4] ""  DUMMY_ECU
 SG_ CVC_DebugDiag12 : 36|3@0+ (1,0) [0|4] ""  DUMMY_ECU
 SG_ CVC_DebugDiag11 : 39|3@0+ (1,0) [0|4] ""  DUMMY_ECU
 SG_ CVC_DebugDiag16 : 40|3@0+ (1,0) [0|4] ""  DUMMY_ECU
 SG_ CVC_DebugDiag15 : 43|3@0+ (1,0) [0|4] ""  DUMMY_ECU
 SG_ CVC_DebugDiag14 : 46|3@0+ (1,0) [0|4] ""  DUMMY_ECU
 SG_ CVC_DebugDiag18 : 50|3@0+ (1,0) [0|4] ""  DUMMY_ECU
 SG_ CVC_DebugDiag17 : 53|3@0+ (1,0) [0|4] ""  DUMMY_ECU
 SG_ CVC_DebugDiag20 : 60|3@0+ (1,0) [0|4] ""  DUMMY_ECU
 SG_ CVC_DebugDiag19 : 63|3@0+ (1,0) [0|4] ""  DUMMY_ECU

BO_ 1874 CVC_Debug: 8 CVC_P
 SG_ CVC_Debug1 : 7|8@0+ (1,0) [0|255] ""  DUMMY_ECU
 SG_ CVC_Debug2 : 15|8@0+ (1,0) [0|255] ""  DUMMY_ECU
 SG_ CVC_Debug3 : 23|8@0+ (1,0) [0|255] ""  DUMMY_ECU
 SG_ CVC_Debug4 : 27|5@0+ (1,0) [0|31] ""  DUMMY_ECU

BO_ 1878 BMS_XCPRx: 8 CVC_P
 SG_ BMS_XCPRxData : 7|64@0+ (1,0) [0|0] ""  BMS

BO_ 1968 CVC_Synchronization_Master: 8 EVCC
 SG_ Sync_TripCnt : 7|24@0+ (1,0) [0|16777215] ""  FMCU,PCU
 SG_ Sync_ResetCnt : 31|16@0+ (1,0) [0|65535] ""  FMCU,PCU
 SG_ Sync_MAC : 47|24@0+ (1,0) [0|16777215] ""  FMCU,PCU

BO_ 537 EVCC_OBC_Ctrl: 12 EVCC
 SG_ CRC_EVCC_OBC_Ctrl : 7|8@0+ (1,0) [0|255] ""  CVC_P,POD_GW,PCU
 SG_ ALIVE_EVCC_OBC_Ctrl : 11|4@0+ (1,0) [0|15] ""  CVC_P,POD_GW,PCU
 SG_ EVCC_OBC_StsModeReq : 63|4@0+ (1,0) [0|15] ""  CVC_P,POD_GW
 SG_ EVCC_ACChgVoltAllow : 71|16@0+ (0.1,0) [0|1000] "V"  CVC_P,POD_GW
 SG_ EVCC_ACChgCurReq : 31|16@0+ (0.1,-1000) [-1000|1000] "A"  CVC_P,POD_GW,PCU
 SG_ EVCC_S2_Sts : 43|3@0+ (1,0) [0|7] ""  CVC_P,POD_GW
 SG_ EVCC_StsChgCC : 47|4@0+ (1,0) [0|15] ""  CVC_P,POD_GW
 SG_ EVCC_CP_DutyCycle : 55|8@0+ (0.4,0) [0|100] "%"  CVC_P,POD_GW

BO_ 593 EVCC01: 12 EVCC
 SG_ EVCC_ChargeMode : 1|2@0+ (1,0) [0|3] ""  BMS,CVC_P
 SG_ EVCC_DCChgPosTemp : 39|8@0+ (1,-40) [-40|210] "Degree C" Vector__XXX
 SG_ EVCC_DCChgNegTemp : 47|8@0+ (1,-40) [-40|210] "Degree C" Vector__XXX
 SG_ EVCC_ACChgL1TerminalTemp : 55|8@0+ (1,-40) [-40|210] "Degree C" Vector__XXX
 SG_ EVCC_ACChgNTerminalTemp_Reserve : 63|8@0+ (1,-40) [-40|210] "Degree C" Vector__XXX
 SG_ EVCC_uCPActDiag : 71|9@0+ (0.01,0) [0|5.11] ""  BMS,CVC_P
 SG_ EVCC_uPPAct : 78|9@0+ (0.01,0) [0|5.11] ""  BMS,CVC_P
 SG_ EVCC_uPlgLckFb : 85|7@0+ (0.1,0) [0|12.7] ""  BMS,CVC_P

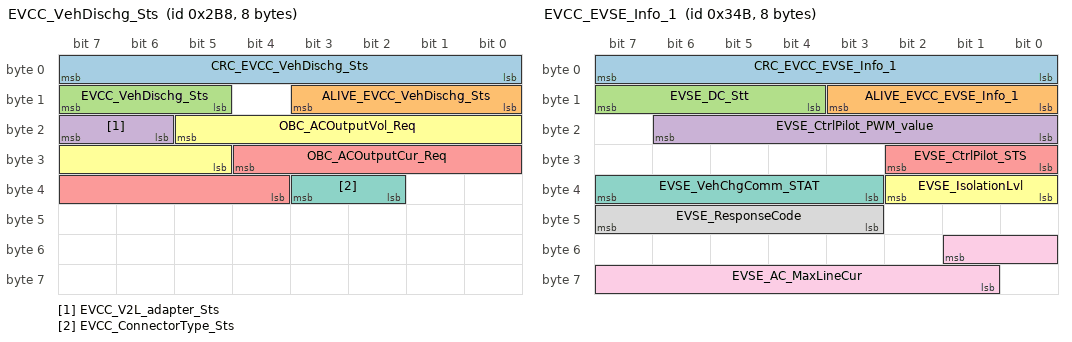
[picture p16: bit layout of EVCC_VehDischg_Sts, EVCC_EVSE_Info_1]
BO_ 696 EVCC_VehDischg_Sts: 8 EVCC
 SG_ CRC_EVCC_VehDischg_Sts : 7|8@0+ (1,0) [0|255] ""  CVC_P,POD_GW
 SG_ ALIVE_EVCC_VehDischg_Sts : 11|4@0+ (1,0) [0|15] ""  CVC_P,POD_GW
 SG_ EVCC_VehDischg_Sts : 15|3@0+ (1,0) [0|5] ""  CVC_P,POD_GW
 SG_ EVCC_V2L_adapter_Sts : 23|2@0+ (1,0) [0|3] ""  CVC_P,POD_GW
 SG_ OBC_ACOutputCur_Req : 28|9@0+ (0.1,0) [0|48] "A"  CVC_P,POD_GW
 SG_ OBC_ACOutputVol_Req : 21|9@0+ (1,0) [0|500] "V"  CVC_P,POD_GW
 SG_ EVCC_ConnectorType_Sts : 35|2@0+ (1,0) [0|2] ""  CVC_P,POD_GW

BO_ 843 EVCC_EVSE_Info_1: 8 EVCC
 SG_ CRC_EVCC_EVSE_Info_1 : 7|8@0+ (1,0) [0|255] ""  CVC_P
 SG_ ALIVE_EVCC_EVSE_Info_1 : 11|4@0+ (1,0) [0|15] ""  CVC_P
 SG_ EVSE_DC_Stt : 15|4@0+ (1,0) [0|12] ""  CVC_P
 SG_ EVSE_CtrlPilot_PWM_value : 22|7@0+ (1,0) [0|100] "%"  CVC_P
 SG_ EVSE_CtrlPilot_STS : 26|3@0+ (1,0) [0|6] ""  CVC_P
 SG_ EVSE_IsolationLvl : 34|3@0+ (1,0) [0|5] ""  CVC_P
 SG_ EVSE_VehChgComm_STAT : 39|5@0+ (1,0) [0|27] ""  CVC_P
 SG_ EVSE_ResponseCode : 47|5@0+ (1,0) [0|26] ""  CVC_P
 SG_ EVSE_AC_MaxLineCur : 49|9@0+ (1,0) [0|400] "A"  CVC_P

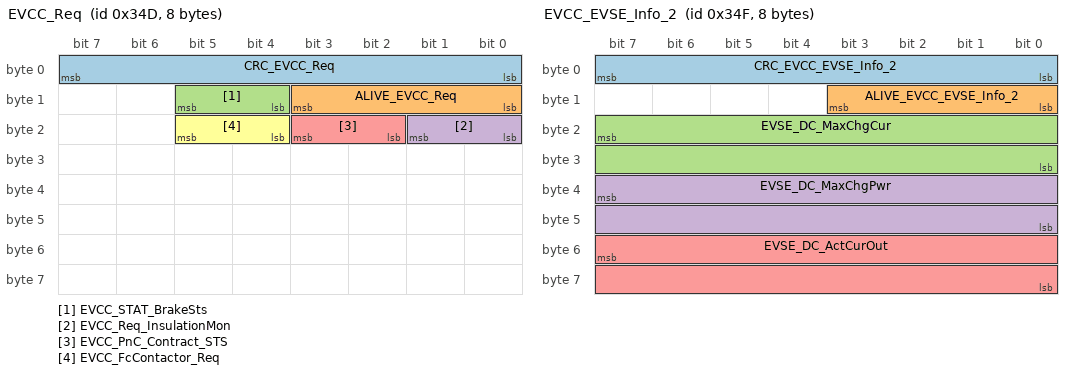
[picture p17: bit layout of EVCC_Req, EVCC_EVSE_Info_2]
BO_ 845 EVCC_Req: 8 EVCC
 SG_ CRC_EVCC_Req : 7|8@0+ (1,0) [0|255] ""  BMS,CVC_P,POD_GW
 SG_ ALIVE_EVCC_Req : 11|4@0+ (1,0) [0|15] ""  BMS,CVC_P,POD_GW
 SG_ EVCC_STAT_BrakeSts : 13|2@0+ (1,0) [0|3] ""  CVC_P
 SG_ EVCC_Req_InsulationMon : 17|2@0+ (1,0) [0|3] ""  BMS,CVC_P,POD_GW
 SG_ EVCC_PnC_Contract_STS : 19|2@0+ (1,0) [0|3] ""  BMS,CVC_P,POD_GW
 SG_ EVCC_FcContactor_Req : 21|2@0+ (1,0) [0|3] ""  BMS,CVC_P,POD_GW

BO_ 847 EVCC_EVSE_Info_2: 8 EVCC
 SG_ CRC_EVCC_EVSE_Info_2 : 7|8@0+ (1,0) [0|255] ""  CVC_P
 SG_ ALIVE_EVCC_EVSE_Info_2 : 11|4@0+ (1,0) [0|15] ""  CVC_P
 SG_ EVSE_DC_MaxChgCur : 23|16@0+ (0.1,0) [0|6553.5] "A"  CVC_P
 SG_ EVSE_DC_MaxChgPwr : 39|16@0+ (0.1,0) [0|6553.5] "kW"  CVC_P
 SG_ EVSE_DC_ActCurOut : 55|16@0+ (0.1,0) [0|6553.5] "A"  CVC_P

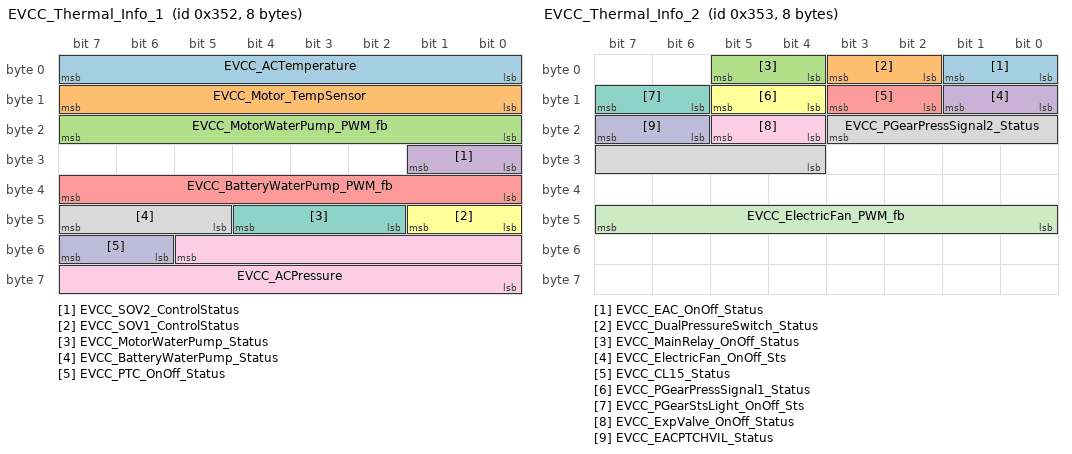
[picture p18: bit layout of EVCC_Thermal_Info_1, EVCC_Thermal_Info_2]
BO_ 850 EVCC_Thermal_Info_1: 8 EVCC
 SG_ EVCC_ACTemperature : 7|8@0+ (1,-40) [-40|140] "Degree C" Vector__XXX
 SG_ EVCC_Motor_TempSensor : 15|8@0+ (1,-40) [-40|140] "Degree C" Vector__XXX
 SG_ EVCC_MotorWaterPump_PWM_fb : 23|8@0+ (1,0) [0|100] "%"  CVC_P
 SG_ EVCC_SOV2_ControlStatus : 25|2@0+ (1,0) [0|3] ""  CVC_P
 SG_ EVCC_BatteryWaterPump_PWM_fb : 39|8@0+ (1,0) [0|100] "%"  CVC_P
 SG_ EVCC_SOV1_ControlStatus : 41|2@0+ (1,0) [0|3] ""  CVC_P
 SG_ EVCC_MotorWaterPump_Status : 44|3@0+ (1,0) [0|4] ""  CVC_P
 SG_ EVCC_BatteryWaterPump_Status : 47|3@0+ (1,0) [0|6] ""  CVC_P
 SG_ EVCC_ACPressure : 53|14@0+ (0.295,-60) [0|1150] "kPa"  CVC_P
 SG_ EVCC_PTC_OnOff_Status : 55|2@0+ (1,0) [0|3] ""  CVC_P

BO_ 851 EVCC_Thermal_Info_2: 8 EVCC
 SG_ EVCC_EAC_OnOff_Status : 1|2@0+ (1,0) [0|3] ""  CVC_P
 SG_ EVCC_DualPressureSwitch_Status : 3|2@0+ (1,0) [0|3] ""  CVC_P
 SG_ EVCC_MainRelay_OnOff_Status : 5|2@0+ (1,0) [0|3] ""  CVC_P
 SG_ EVCC_ElectricFan_OnOff_Sts : 9|2@0+ (1,0) [0|3] ""  CVC_P
 SG_ EVCC_CL15_Status : 11|2@0+ (1,0) [0|3] ""  CVC_P
 SG_ EVCC_PGearPressSignal1_Status : 13|2@0+ (1,0) [0|3] ""  CVC_P
 SG_ EVCC_PGearStsLight_OnOff_Sts : 15|2@0+ (1,0) [0|3] ""  CVC_P
 SG_ EVCC_PGearPressSignal2_Status : 19|8@0+ (1,0) [0|255] "kilo ohms" Vector__XXX
 SG_ EVCC_ExpValve_OnOff_Status : 21|2@0+ (1,0) [0|3] ""  CVC_P
 SG_ EVCC_EACPTCHVIL_Status : 23|2@0+ (1,0) [0|3] ""  CVC_P
 SG_ EVCC_ElectricFan_PWM_fb : 47|8@0+ (1,0) [0|100] "%"  CVC_P

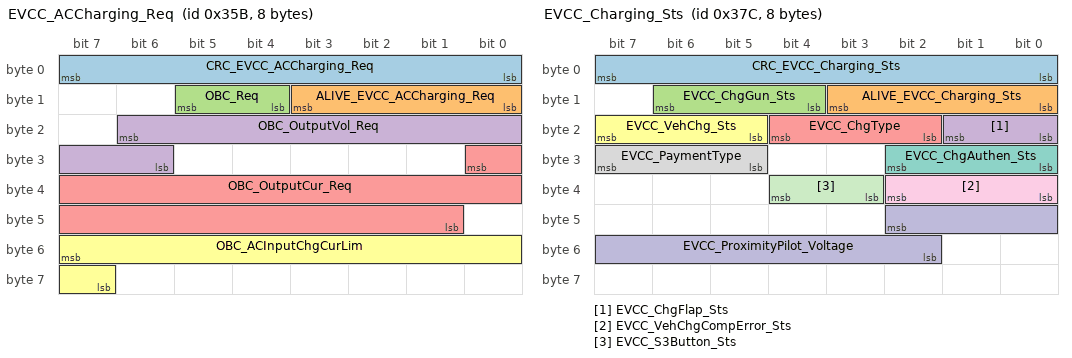
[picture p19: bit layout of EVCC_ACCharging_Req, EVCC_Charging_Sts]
BO_ 859 EVCC_ACCharging_Req: 8 EVCC
 SG_ CRC_EVCC_ACCharging_Req : 7|8@0+ (1,0) [0|255] ""  CVC_P,POD_GW
 SG_ ALIVE_EVCC_ACCharging_Req : 11|4@0+ (1,0) [0|15] ""  CVC_P,POD_GW
 SG_ OBC_Req : 13|2@0+ (1,0) [0|3] ""  CVC_P,POD_GW
 SG_ OBC_OutputVol_Req : 22|9@0+ (1,0) [0|500] "V"  CVC_P,POD_GW
 SG_ OBC_OutputCur_Req : 24|16@0+ (0.1,0) [0|48] "A"  CVC_P,POD_GW
 SG_ OBC_ACInputChgCurLim : 55|9@0+ (0.1,0) [0|48] "A"  CVC_P,POD_GW

BO_ 892 EVCC_Charging_Sts: 8 EVCC
 SG_ CRC_EVCC_Charging_Sts : 7|8@0+ (1,0) [0|255] ""  BMS,CVC_P
 SG_ ALIVE_EVCC_Charging_Sts : 11|4@0+ (1,0) [0|15] ""  BMS,CVC_P
 SG_ EVCC_ChgGun_Sts : 14|3@0+ (1,0) [0|7] ""  BMS,CVC_P
 SG_ EVCC_ChgFlap_Sts : 17|2@0+ (1,0) [0|3] ""  BMS,CVC_P
 SG_ EVCC_ChgType : 20|3@0+ (1,0) [0|7] ""  BMS,CVC_P
 SG_ EVCC_VehChg_Sts : 23|3@0+ (1,0) [0|7] ""  BMS,CVC_P
 SG_ EVCC_ChgAuthen_Sts : 26|3@0+ (1,0) [0|7] ""  BMS,CVC_P
 SG_ EVCC_PaymentType : 31|3@0+ (1,0) [0|7] ""  BMS,CVC_P
 SG_ EVCC_VehChgCompError_Sts : 34|3@0+ (1,0) [0|7] ""  BMS,CVC_P
 SG_ EVCC_ProximityPilot_Voltage : 42|9@0+ (0.01,0) [0|5] "V"  BMS,CVC_P
 SG_ EVCC_S3Button_Sts : 36|2@0+ (1,0) [0|3] ""  BMS,CVC_P

BO_ 1145 EVCC_EventMatrix: 24 EVCC
 SG_ EVCC_evt_ePP : 0|1@0+ (1,0) [0|1] ""  DUMMY_ECU
 SG_ EVCC_evt_eCP : 1|1@0+ (1,0) [0|1] ""  DUMMY_ECU
 SG_ EVCC_evt_eGunLck : 2|1@0+ (1,0) [0|1] ""  DUMMY_ECU
 SG_ EVCC_evt_eV2G : 3|1@0+ (1,0) [0|1] ""  DUMMY_ECU
 SG_ EVCC_evt_eAcPlugTemp : 4|1@0+ (1,0) [0|1] ""  DUMMY_ECU
 SG_ EVCC_evt_eDcPlugTemp : 5|1@0+ (1,0) [0|1] ""  DUMMY_ECU
 SG_ EVCC_evt_eBmsLvl : 6|1@0+ (1,0) [0|1] ""  DUMMY_ECU
 SG_ EVCC_bChEndShortDeb : 7|1@0+ (1,0) [0|1] ""  DUMMY_ECU
 SG_ EVCC_evt_iEvseDcPeakRpl : 8|1@0+ (1,0) [0|1] ""  DUMMY_ECU
 SG_ EVCC_evt_eObcLvl : 9|1@0+ (1,0) [0|1] ""  DUMMY_ECU
 SG_ EVCC_evt_ChgGunStkOpnd : 10|1@0+ (1,0) [0|1] ""  DUMMY_ECU
 SG_ EVCC_evt_ChgGunStkClsd : 11|1@0+ (1,0) [0|1] ""  DUMMY_ECU
 SG_ EVCC_evt_AcTmpShortVcc : 12|1@0+ (1,0) [0|1] ""  DUMMY_ECU
 SG_ EVCC_evt_PPShortVcc : 13|1@0+ (1,0) [0|1] ""  DUMMY_ECU
 SG_ EVCC_evt_PPShortGnd : 14|1@0+ (1,0) [0|1] ""  DUMMY_ECU
 SG_ EVCC_evt_DcPTmpShortGnd : 15|1@0+ (1,0) [0|1] ""  DUMMY_ECU
 SG_ EVCC_evt_eFCWelded : 16|1@0+ (1,0) [0|1] ""  DUMMY_ECU
 SG_ EVCC_evt_eHVBusTemp : 17|1@0+ (1,0) [0|1] ""  DUMMY_ECU
 SG_ EVCC_evt_ChgFlapHBShtGnd : 18|1@0+ (1,0) [0|1] ""  DUMMY_ECU
 SG_ EVCC_evt_ChgFlapHBShtBatt : 19|1@0+ (1,0) [0|1] ""  DUMMY_ECU
 SG_ EVCC_evt_ChgFlapHBOpnCir : 20|1@0+ (1,0) [0|1] ""  DUMMY_ECU
 SG_ EVCC_evt_ChgFlapHBOCVCrr : 21|1@0+ (1,0) [0|1] ""  DUMMY_ECU
 SG_ EVCC_evt_ChgFlapHBOvTemp : 22|1@0+ (1,0) [0|1] ""  DUMMY_ECU
 SG_ EVCC_evt_DcPTmpShortVcc : 23|1@0+ (1,0) [0|1] ""  DUMMY_ECU
 SG_ EVCC_evt_AcTmpShortGnd : 24|1@0+ (1,0) [0|1] ""  DUMMY_ECU
 SG_ EVCC_evt_eBmsInsu : 25|1@0+ (1,0) [0|1] ""  DUMMY_ECU
 SG_ EVCC_evt_eChrgUpEvseNotifStp : 26|1@0+ (1,0) [0|1] ""  DUMMY_ECU
 SG_ EVCC_evt_ePLCSubTimeOut : 27|1@0+ (1,0) [0|1] ""  DUMMY_ECU
 SG_ EVCC_bChEndLongDeb : 28|1@0+ (1,0) [0|1] ""  DUMMY_ECU
 SG_ EVCC_evt_eDcFcLvl3 : 29|1@0+ (1,0) [0|1] ""  DUMMY_ECU
 SG_ EVCC_evt_eEVSE : 30|1@0+ (1,0) [0|1] ""  DUMMY_ECU
 SG_ EVCC_evt_S2StkClsd : 31|1@0+ (1,0) [0|1] ""  DUMMY_ECU
 SG_ EVCC_evt_S2StkOpnd : 32|1@0+ (1,0) [0|1] ""  DUMMY_ECU
 SG_ EVCC_evt_CpFreqFailr : 33|1@0+ (1,0) [0|1] ""  DUMMY_ECU
 SG_ EVCC_evt_bPmicOV : 34|1@0+ (1,0) [0|1] ""  DUMMY_ECU
 SG_ EVCC_evt_bPmicUV : 35|1@0+ (1,0) [0|1] ""  DUMMY_ECU
 SG_ EVCC_evt_bMissCvcMsg : 36|1@0+ (1,0) [0|1] ""  DUMMY_ECU
 SG_ EVCC_evt_bMissBmsMsg : 37|1@0+ (1,0) [0|1] ""  DUMMY_ECU
 SG_ EVCC_evt_bMissPodMsg : 38|1@0+ (1,0) [0|1] ""  DUMMY_ECU
 SG_ EVCC_evt_bMissBcmMsg : 39|1@0+ (1,0) [0|1] ""  DUMMY_ECU
 SG_ EVCC_evt_bE2eCvcMsg : 40|1@0+ (1,0) [0|1] ""  DUMMY_ECU
 SG_ EVCC_evt_bE2eBmsMsg : 41|1@0+ (1,0) [0|1] ""  DUMMY_ECU
 SG_ EVCC_evt_bE2ePodMsg : 42|1@0+ (1,0) [0|1] ""  DUMMY_ECU
 SG_ EVCC_evt_bE2eBcmMsg : 43|1@0+ (1,0) [0|1] ""  DUMMY_ECU
 SG_ EVCC_evt_ChgGunHBOvTemp : 44|1@0+ (1,0) [0|1] ""  DUMMY_ECU
 SG_ EVCC_evt_ChgGunHBOCVCrr : 45|1@0+ (1,0) [0|1] ""  DUMMY_ECU
 SG_ EVCC_evt_ChgGunHBOpnCir : 46|1@0+ (1,0) [0|1] ""  DUMMY_ECU
 SG_ EVCC_evt_ChgGunHBShtBatt : 47|1@0+ (1,0) [0|1] ""  DUMMY_ECU
 SG_ EVCC_evt_ChgFlapHBPorErr : 48|1@0+ (1,0) [0|1] ""  DUMMY_ECU
 SG_ EVCC_evt_ChgFlapHBSpiComErr : 49|1@0+ (1,0) [0|1] ""  DUMMY_ECU
 SG_ EVCC_evt_ChgGunHBPorErr : 50|1@0+ (1,0) [0|1] ""  DUMMY_ECU
 SG_ EVCC_evt_ChgGunHBShtGnd : 51|1@0+ (1,0) [0|1] ""  DUMMY_ECU
 SG_ EVCC_evt_DcNTmpShortVcc : 52|1@0+ (1,0) [0|1] ""  DUMMY_ECU
 SG_ EVCC_evt_DcNTmpShortGnd : 53|1@0+ (1,0) [0|1] ""  DUMMY_ECU
 SG_ EVCC_evt_L2ChkErr : 54|1@0+ (1,0) [0|1] ""  DUMMY_ECU
 SG_ EVCC_evt_ChgTypeErr : 55|1@0+ (1,0) [0|1] ""  DUMMY_ECU
 SG_ EVCC_evt_ChgGunHBSpiComErr : 56|1@0+ (1,0) [0|1] ""  DUMMY_ECU
 SG_ EVCC_evt_PreconditionFlt : 57|1@0+ (1,0) [0|1] ""  DUMMY_ECU
 SG_ EVCC_bS2RlyCtl : 58|1@0+ (1,0) [0|1] ""  DUMMY_ECU
 SG_ EVCC_bS2Clsd : 59|1@0+ (1,0) [0|1] ""  DUMMY_ECU
 SG_ EVCC_bChGunDir : 60|1@0+ (1,0) [0|1] ""  DUMMY_ECU
 SG_ EVCC_stV2GErr : 71|8@0+ (1,0) [0|255] ""  DUMMY_ECU
 SG_ EVCC_stSup : 79|8@0+ (1,0) [0|255] ""  DUMMY_ECU
 SG_ EVCC_stPLCReqDc : 83|4@0+ (1,0) [0|15] ""  DUMMY_ECU
 SG_ EVCC_stPLCReqAc : 87|4@0+ (1,0) [0|15] ""  DUMMY_ECU
 SG_ EVCC_evt_eGunPlugTemp : 88|1@0+ (1,0) [0|1] ""  DUMMY_ECU
 SG_ EVCC_evt_eObcSts : 90|1@0+ (1,0) [0|1] ""  DUMMY_ECU
 SG_ EVCC_evt_eBmsInsuProc : 91|1@0+ (1,0) [0|1] ""  DUMMY_ECU
 SG_ EVCC_evt_eHvBatSupVolt : 92|1@0+ (1,0) [0|1] ""  DUMMY_ECU
 SG_ EVCC_evt_eDcfcStsProc : 93|1@0+ (1,0) [0|1] ""  DUMMY_ECU
 SG_ EVCC_evt_eDcfcStsSna : 94|1@0+ (1,0) [0|1] ""  DUMMY_ECU
 SG_ EVCC_evt_eChrgPortHiVolt : 96|1@0+ (1,0) [0|1] ""  DUMMY_ECU
 SG_ EVCC_evt_eTempSnsDatInvd : 97|1@0+ (1,0) [0|1] ""  DUMMY_ECU
 SG_ EVCC_evt_FS23LostComm : 98|1@0+ (1,0) [0|1] ""  DUMMY_ECU
 SG_ EVCC_evt_eFS23SelfTestFail : 99|1@0+ (1,0) [0|1] ""  DUMMY_ECU
 SG_ EVCC_evt_eMcuPwrFail : 100|1@0+ (1,0) [0|1] ""  DUMMY_ECU
 SG_ EVCC_evt_eAcuCrs : 101|1@0+ (1,0) [0|1] ""  DUMMY_ECU
 SG_ EVCC_WkSource : 63|3@0+ (1,0) [0|7] ""  DUMMY_ECU
 SG_ EVCC_H_Dir : 102|1@0+ (1,0) [0|1] ""  DUMMY_ECU
 SG_ EVCC_H_Status : 103|1@0+ (1,0) [0|1] ""  DUMMY_ECU
 SG_ EVCC_bChPlgLckReq : 104|1@0+ (1,0) [0|1] ""  DUMMY_ECU
 SG_ EVCC_bRawPlugPresent : 105|1@0+ (1,0) [0|1] ""  DUMMY_ECU
 SG_ EVCC_bSleepValid : 107|1@0+ (1,0) [0|1] ""  DUMMY_ECU
 SG_ V2GEVCC_stEvseNotif : 109|2@0+ (1,0) [0|3] ""  DUMMY_ECU
 SG_ V2GEVCC_uDcEvChReq : 119|6@0+ (1,0) [0|63] ""  DUMMY_ECU
 SG_ V2GEVCC_uEvseDcMax : 113|6@0+ (1,0) [0|63] ""  DUMMY_ECU
 SG_ EVCC_percChGunLckMot : 135|8@0+ (0.1,0) [0|25.5] ""  DUMMY_ECU
 SG_ EVCC_State : 123|3@0+ (1,0) [0|7] ""  DUMMY_ECU
 SG_ EVCC_EvseAppPtcolSupport : 111|2@0+ (1,0) [0|3] ""  DUMMY_ECU
 SG_ EVCC_SLAC_Attenuation : 142|7@0+ (1,0) [0|100] ""  DUMMY_ECU
 SG_ EVCC_SlacState : 147|4@0+ (1,0) [0|15] ""  DUMMY_ECU
 SG_ EVCC_TCP_Socket_Sts : 151|4@0+ (1,0) [0|15] ""  DUMMY_ECU
 SG_ EVCC_Hse_status : 155|4@0+ (1,0) [0|15] ""  DUMMY_ECU

BO_ 90 FMCU_ResetInfo: 12 FMCU
 SG_ FMCU_Trap_Tin : 7|16@0+ (1,0) [0|65535] ""  DUMMY_ECU
 SG_ FMCU_Trap_Class : 23|16@0+ (1,0) [0|65535] ""  DUMMY_ECU
 SG_ FMCU_ReturnAddress : 71|32@0+ (1,0) [0|4294967295] ""  DUMMY_ECU
 SG_ FMCU_DEADD_Value : 39|32@0+ (1,0) [0|4294967295] ""  DUMMY_ECU

CM_ BO_ 133 "ACU Message for crash details";
CM_ SG_ 133 CRC_ACU_CRASH_INFO "Checksum";
CM_ SG_ 133 ALIVE_ACU_CRASH_INFO "Alive Counter";
CM_ SG_ 133 ACU_Crash_Sts "Crash status";
CM_ SG_ 133 ACU_Airbag_Deployment_Status "Signal to indicate if airbag pretensioner pyrofuse is deployed";
CM_ SG_ 133 ACU_Crash_Intensity "Indicate crash intensity level";
CM_ SG_ 133 ACU_Front_Crash "Frontal collision";
CM_ SG_ 133 ACU_DriverSide_Crash "Driver's side collision";
CM_ SG_ 133 ACU_PassSide_Crash "Passenger side collision";
CM_ SG_ 133 ACU_Rear_Crash "Rear collision";
CM_ SG_ 133 ACU_Rollover_Crash "Has the vehicle experienced a rollover collision";
CM_ SG_ 294 CRC_BMS_AllowChargeCurr "Checksum";
CM_ SG_ 294 ALIVE_BMS_AllowChargeCurr "Rolling Counter";
CM_ SG_ 294 BMS_AllowChgCurr "Continuous maximum allowable charge current of battery";
CM_ SG_ 294 BMS_AllowChgCurrPeak "Instantaneous maximum allowable charge current of battery for 30 seconds";
CM_ SG_ 296 CRC_BMS_AllowDischargeCurr "Checksum";
CM_ SG_ 296 ALIVE_BMS_AllowDischargeCurr "Rolling Counter";
CM_ SG_ 296 BMS_AllowDischgCurr "Instantaneous maximum allowable discharge current of battery";
CM_ SG_ 296 BMS_AllowDischgCurrPeak "Instantaneous maximum allowable discharge current of battery for 30 seconds";
CM_ SG_ 372 CRC_BMS_CurMeas "Checksum";
CM_ SG_ 372 ALIVE_BMS_CurMeas "Alive Counter";
CM_ SG_ 372 BMS_StartOfMeasument_STS "Synchronize signals indicate start of cell/pack voltage measument";
CM_ SG_ 372 BMS_PackCur_MEAS "Battery Pack Total Current";
CM_ SG_ 372 BMS_HVPackVol_MEAS "Pack Voltage";
CM_ SG_ 372 BMS_HVLinkVol_MEAS "Link Voltage";
CM_ SG_ 372 BMS_HVBusVol_MEAS "BUS Voltage, it is informative";
CM_ SG_ 372 BMS_HVFuseVol_MEAS "Measure voltage after fuse to identify the fuse is blown or not";
CM_ SG_ 372 BMS_MainNegRelay_Volt "main negative relay diagnosis voltage";
CM_ SG_ 372 BMS_CellNumMinCellVol "Cell Number of Min Cell Voltage";
CM_ SG_ 372 BMS_CellNumMaxCellVol "Cell Number of Max Cell Voltage";
CM_ SG_ 372 BMS_MinCellVol "Min Cell Voltage";
CM_ SG_ 372 BMS_MaxCellVol "Max Cell Voltage";
CM_ SG_ 372 BMS_MaxMinDiffCellVol "max and min cell voltage differences";
CM_ SG_ 372 BMS_CVC_Insulation_Mon_Sts "Feedback for the Insulation Monitoring signal";
CM_ SG_ 372 BMS_PackInsuRes "Minimum value of BCU_PosInsuRes and BCU_NegInsuRes";
CM_ SG_ 521 CRC_BMS_PowerCont "Checksum";
CM_ SG_ 521 ALIVE_BMS_PowerCont "Rolling Counter";
CM_ SG_ 521 BMS_MaxDischgPwr_ALW "Allow Max Discharge Power accepted";
CM_ SG_ 521 BMS_MaxChgPwr_ALW "Allow Max Regenerative Power accepted.";
CM_ SG_ 521 BMS_MaxDischgPwr_Peak "Allow Max Discharge Power accepted in 30s";
CM_ SG_ 521 BMS_MaxChgPwr_Peak "Allow Max Regenerative Power accepted in 30s.";
CM_ SG_ 533 CRC_BMS_Sts "Checksum";
CM_ SG_ 533 ALIVE_BMS_Sts "Rolling Counter";
CM_ SG_ 533 BMS_BatBalance_ERR "Battery Balance Error indicates Balancing switch is short or open";
CM_ SG_ 533 BMS_Balance_STS "BMS Balance Status";
CM_ SG_ 533 BMS_IGN_Sts "the ignition signal status (on/off)";
CM_ SG_ 533 BMS_HWCrash_Sts "Battery Pack Hardware Crash signal Status";
CM_ SG_ 533 BMS_HVIL_STS "The HVIL state of BMS";
CM_ SG_ 533 BMS_HVOnOff_STS "Status of the High Voltage";
CM_ SG_ 533 BMS_ERR_LEV "BMS requesting CVC to operate at the limited operating strategy (LOS)";
CM_ SG_ 533 BMS_SocActual_EST "Actual SOC";
CM_ SG_ 533 BMS_Sys_STS "BMS_Status(Self-test after BMS wake-up) BMS CVC";
CM_ SG_ 533 BMS_ISU_Status "Pack Insulation Status";
CM_ SG_ 533 BMS_SOH "BMS State Of Health";
CM_ SG_ 533 BMS_SOE "BMS State Of Enegy";
CM_ SG_ 533 BMS_HV_Sts "HV Status";
CM_ SG_ 533 BMS_Display_SOC "Display SOC";
CM_ SG_ 533 BMS_SOCE "State of certified energy";
CM_ SG_ 534 CRC_BMS_ChgParamReq "Checksum";
CM_ SG_ 534 ALIVE_BMS_ChgParamReq "Rolling Counter";
CM_ SG_ 534 BMS_RemainChargeTime "Remain Charge Time send to other ECU (XGW - IPC)";
CM_ SG_ 534 BMS_ChgVoltage_REQ "Charge Voltage Request";
CM_ SG_ 534 BMS_ChgCurrent_REQ "Charge Current Request";
CM_ SG_ 581 CRC_BMS_CellTemp "Checksum";
CM_ SG_ 581 ALIVE_BMS_CellTemp "Rolling Counter";
CM_ SG_ 581 BMS_ProbeNumMaxCellTemp "Probe Number of Max Cell Temperature";
CM_ SG_ 581 BMS_MinCellTemp "Min Cell Temperature";
CM_ SG_ 581 BMS_ProbeNumMinCellTemp "Probe Number of Min Cell Temperature";
CM_ SG_ 581 BMS_PackTemp "Pack Temperature";
CM_ SG_ 581 BMS_MaxCellTemp "Max Cell Temperature";
CM_ SG_ 581 BMS_MaxMinDiffCellTemp "max and min cell temperature differences";
CM_ SG_ 585 CRC_BMS_CoolntInletOutletTmp "Check sum";
CM_ SG_ 585 ALIVE_BMS_CoolntInletOutletTmp "Alive counter";
CM_ SG_ 585 BMS_CoolantInletTemp "Temperature of Battery Coolant Inlet";
CM_ SG_ 585 BMS_CoolantOutletTemp "Temperature of Battery Coolant Outlet";
CM_ SG_ 585 BMS_BDUTemp1 "BDU Temperature";
CM_ SG_ 585 BMS_BDUTemp2 "BDU Temperature";
CM_ SG_ 585 BMS_CoolantInletTempSts "BMS coolant inlet temperature status";
CM_ SG_ 585 BMS_CoolantOutletTempSts "BMS coolant outlet temperature status";
CM_ SG_ 592 CRC_BMS_CVC_THMReq "Check sum";
CM_ SG_ 592 ALIVE_BMS_CVC_THMReq "Alive counter";
CM_ SG_ 592 BMS_FlowRate_Req "Flow rate required";
CM_ SG_ 592 BMS_CoolPwrDemand "requesting the cooling power required fro the battery pack";
CM_ SG_ 592 BMS_HeatPwrDemand "requesting the heating power required fro the battery pack";
CM_ SG_ 592 BMS_CVC_PTCOnOff_Req "PTC Heater turn on and off request";
CM_ SG_ 592 BMS_CVC_ValveOnOff_Req "requesting CVC to turn on and off the valve";
CM_ SG_ 592 BMS_PreHeatCoolReq "Battery pack precondition information";
CM_ SG_ 592 BMS_InletTemp_Req "Target water inlet temperature request";
CM_ SG_ 816 CRC_BMS_HistData "Checksum";
CM_ SG_ 816 ALIVE_BMS_HistData "Rolling Counter";
CM_ SG_ 816 BMS_ContactorAging "Aging condition of contactor - PreCharge Realy - Positive Contactor - Negative Contactor";
CM_ SG_ 818 CRC_BMS_PackInfo "Checksum";
CM_ SG_ 818 ALIVE_BMS_PackInfo "Rolling Counter";
CM_ SG_ 818 BMS_PackNominalEnergy "Nominal capacity of the battery pack";
CM_ SG_ 818 BMS_SwVers_Type "BMS software scheme number";
CM_ SG_ 818 BMS_SwVersS_phase "BMS software version number";
CM_ SG_ 818 BMS_swVers_version "BMS version number";
CM_ SG_ 818 BMS_SupplierType "define the battery supplier";
CM_ SG_ 885 CRC_BMS_Relay "Checksum";
CM_ SG_ 885 ALIVE_BMS_Relay "Rolling Counter";
CM_ SG_ 885 BMS_PreChgRelay_ERR "Precahrge relay is not working properly";
CM_ SG_ 885 BMS_TotalNegRelay_ERR "Main Negative Relay Error";
CM_ SG_ 885 BMS_MainPosRelay_ERR "Main Position Relay Error";
CM_ SG_ 885 BMS_MainPosRelay_STS "Main Positive Relay Status";
CM_ SG_ 885 BMS_PreChgRelay_STS "PreCharge Relay Status";
CM_ SG_ 885 BMS_TotalNegRelay_STS "Main Negative Relay Status";
CM_ SG_ 1110 CRC_BMS_ERROR "Checksum";
CM_ SG_ 1110 ALIVE_BMS_ERROR "Rolling Counter";
CM_ SG_ 1110 BMS_CellLowVol_ERR "under voltage of the cell is detected";
CM_ SG_ 1110 BMS_HVIL_Err "High Voltage Interlock loop circuit error";
CM_ SG_ 1110 BMS_PackInsu_ERR "Insulation check lines have problems, short to ground or short to bat";
CM_ SG_ 1110 BMS_CellVoltDiff_ERR "max and min cell voltage difference is too large";
CM_ SG_ 1110 BMS_ProbeTempDiff_ERR "The difference in temperture between max and min is beyound the permissable limit";
CM_ SG_ 1110 BMS_PackHighVol_ERR "Pack voltage is higher than the permittable values";
CM_ SG_ 1110 BMS_PackLowVol_ERR "Pack voltage is lower than the permittable values";
CM_ SG_ 1110 BMS_CellHighVol_ERR "Over voltage of the cell is detected";
CM_ SG_ 1110 BMS_ProbeHighTemp_ERR "Over temperature of the cell is detected";
CM_ SG_ 1110 BMS_FuseStatus_ERR "Fuse and Pyro fuse blowup status";
CM_ SG_ 1110 BMS_PackOverCurr_ERR "When the over current is detected during charging and discharging for the given period of time, then the BMS_Packovercurr_err will set";
CM_ SG_ 1110 BMS_ProbeLowTemp_ERR "Under Temperature of the cell is detected";
CM_ SG_ 1110 EHPMon_bErrVehIslnRNvMon "Non-volatile error flag indicating pack level isolation resistance fault.";
CM_ SG_ 1110 EHPMon_bErrPackIslnRNvMon "Non-volatile error flag indicating vehicle level isolation resistance fault.";
CM_ SG_ 1146 BMS_CellMaxSOC "BMS Cell Max SOC";
CM_ SG_ 1146 BMS_CellMinSOC "BMS Cell Min SOC";
CM_ SG_ 1146 BMS_CorrectedSOC "BMS SOC correction";
CM_ SG_ 1146 BMS_PackSOCDiff "BMS diagnostic signal for pack SoC difference";
CM_ SG_ 1171 CRC_BMS_WarnMsg "Checksum";
CM_ SG_ 1171 ALIVE_BMS_WarnMsg "Alive Counter";
CM_ SG_ 1171 BMS_PackTempSts "Pack temperature warning";
CM_ SG_ 1171 BMS_ThermalRunaway "Thermal runaway warning";
CM_ SG_ 1171 BMS_BatteryReplacement "Separate signal to indicate the battery replacement information(Battery replacement MHU)";
CM_ SG_ 1171 BMS_Warning_PowerDegrade "Pack Power Degrade: Battery is cold & limited capacity, please charge";
CM_ SG_ 1171 BMS_Warning_DeltaSoC "EV Battery Delta SOC is high, range reduction in vehicle will be absorbed";
CM_ SG_ 1171 BMS_Warning_HVILSts "HVIL warning signal";
CM_ SG_ 1171 BMS_Warning_Isolation "Coolant Leakage warning";
CM_ SG_ 1171 BMS_Warning_CoolantLeakage "Coolant Leakage warning";
CM_ SG_ 1171 BMS_MalfunctionSts "Malfunction status of battery for MHU display";
CM_ SG_ 1171 BMS_LowBattery "Low Battery Warning";
CM_ SG_ 1171 BMS_Warning_DeltaTemperature "Delta temperature warning signal";
CM_ SG_ 1171 BMS_Warning_BDUTemperatureSts "BDU temperature warning signal";
CM_ SG_ 1171 BMS_Warning_Contactor_Aging "Contactor Aging Warning";
CM_ SG_ 1171 BMS_Reserved_signal4 "Warning Message Flag, Component owner, Supplier align and define for this signal";
CM_ SG_ 1171 BMS_Reserved_signal5 "Warning Message Flag, Component owner, Supplier align and define for this signal";
CM_ SG_ 1952 BMS_CellT1 "BMS_CellT1";
CM_ SG_ 1952 BMS_CellT2 "BMS_CellT2";
CM_ SG_ 1952 BMS_CellT3 "BMS_CellT3";
CM_ SG_ 1952 BMS_CellT4 "BMS_CellT4";
CM_ SG_ 1952 BMS_CellT5 "BMS_CellT5";
CM_ SG_ 1952 BMS_CellT6 "BMS_CellT6";
CM_ SG_ 1952 BMS_CellT7 "BMS_CellT7";
CM_ SG_ 1952 BMS_CellT8 "BMS_CellT8";
CM_ SG_ 1952 BMS_CellT9 "BMS_CellT9";
CM_ SG_ 1952 BMS_CellT10 "BMS_CellT10";
CM_ SG_ 1952 BMS_CellT11 "BMS_CellT11";
CM_ SG_ 1952 BMS_CellT12 "BMS_CellT12";
CM_ SG_ 1952 BMS_CellT13 "BMS_CellT13";
CM_ SG_ 1952 BMS_CellT14 "BMS_CellT14";
CM_ SG_ 1952 BMS_CellT15 "BMS_CellT15";
CM_ SG_ 1952 BMS_CellT16 "BMS_CellT16";
CM_ SG_ 1952 BMS_CellT17 "BMS_CellT17";
CM_ SG_ 1952 BMS_CellT18 "BMS_CellT18";
CM_ SG_ 1952 BMS_CellT19 "BMS_CellT19";
CM_ SG_ 1952 BMS_CellT20 "BMS_CellT20";
CM_ SG_ 1952 BMS_CellT21 "BMS_CellT21";
CM_ SG_ 1952 BMS_CellT22 "BMS_CellT22";
CM_ SG_ 1952 BMS_CellT23 "BMS_CellT23";
CM_ SG_ 1952 BMS_CellT24 "BMS_CellT24";
CM_ SG_ 1952 BMS_CellT25 "BMS_CellT25";
CM_ SG_ 1952 BMS_CellT26 "BMS_CellT26";
CM_ SG_ 1952 BMS_CellT27 "BMS_CellT27";
CM_ SG_ 1952 BMS_CellT28 "BMS_CellT28";
CM_ SG_ 1952 BMS_CellT29 "BMS_CellT29";
CM_ SG_ 1952 BMS_CellT30 "BMS_CellT30";
CM_ SG_ 1952 BMS_CellT31 "BMS_CellT31";
CM_ SG_ 1952 BMS_CellT32 "BMS_CellT32";
CM_ SG_ 1952 BMS_CellT33 "BMS_CellT33";
CM_ SG_ 1952 BMS_CellT34 "BMS_CellT34";
CM_ SG_ 1952 BMS_CellT35 "BMS_CellT35";
CM_ SG_ 1952 BMS_CellT36 "BMS_CellT36";
CM_ BO_ 1939 "BMS XCP TX message";
CM_ SG_ 1939 BMS_XCPTxData "XCP TX signal";
CM_ SG_ 169 BCMFL_AmbientTemp "Ambient temperature";
CM_ SG_ 169 BCMFL_CabinHeat_TempSensor "the Interior Temperature with Celcius Degree";
CM_ SG_ 169 BCMFL_AmbientTempSts "Environmental temperature sensor input value";
CM_ SG_ 169 BCMFL_CoolantTemp_EDS_In_Sts "Front EDS Inlet Coolant Temperature Sensor Status";
CM_ SG_ 169 BCMFL_CoolantTemp_EDS_Out_Sts "Front EDS Outlet Coolant Temperature";
CM_ SG_ 169 BCMFL_CoolantTemp_LTR_Out_Sts "LTR Outlet Coolant Temperature Sensor Status";
CM_ SG_ 169 BCMFL_ACLowSideTemperatureSts "Temperature status on the low-pressure side of the air conditioner";
CM_ SG_ 169 BCMFL_ACLowSidePressureSts "Pressure state on the low-pressure side of the air conditioner";
CM_ SG_ 169 BCMFL_ACHighSideTemperatureSts "Temperature status on the high-pressure side of the air conditioner";
CM_ SG_ 169 BCMFL_ACHighSidePressureSts "Pressure status on the high-pressure side of the air conditioner";
CM_ SG_ 169 BCMFL_CoolantTemp_HtrCore_In_Sts "Heater Core Inlet Coolant Temperature Sensor Status";
CM_ SG_ 169 BCMFL_Refrigerant_Temp_Sensor_St "Refrigerant temperature sensor status";
CM_ SG_ 169 BCMFL_PT_Sensor1_Pressure_Sts "Pressure state of pressure and temperature sensor [1]";
CM_ SG_ 169 BCMFL_PT_Sensor2_Pressure_Sts "Pressure state of pressure and temperature sensor [2]";
CM_ SG_ 170 CRC_CVC_Sts1 "CHSKM_CVC_Sts1";
CM_ SG_ 170 CVC_BMS_HVOnOff_REQ "BMS decides whether to close or disconnect the primary and negative relays by judging this command";
CM_ SG_ 171 CRC_CVC_FMCU_Ctrl "Checksum of this message";
CM_ SG_ 171 ALIVE_CVC_FMCU_Ctrl "Signal counting the times of this message";
CM_ SG_ 171 CVC_FMCU_TargetTqReq "Front Motor Target torque Request";
CM_ SG_ 171 CVC_FMCU_TargetSpeedReq "Front Motor Target speed Request";
CM_ SG_ 171 CVC_FMCU_StsModeReq "FMCU Status Request";
CM_ SG_ 171 CVC_FMCU_TargetTqReqV "Front Motor Target torque Request Validity";
CM_ SG_ 171 CVC_FMCU_TargetSpeedReqV "Front Motor Target speed Request Validity";
CM_ SG_ 171 CVC_FMCU_VehicleDirect "Vehicle direct";
CM_ SG_ 171 CVC_MCU_AtvDischg_Req "MCU Active Discharge Request";
CM_ SG_ 171 CVC_MCU_CtrlModeReq "Control Mode Request";
CM_ SG_ 171 CVC_FMCU_ActiveHeatingReq "Heating Request";
CM_ SG_ 172 CRC_CVC_RMCU_Ctrl "Checksum of this message";
CM_ SG_ 172 ALIVE_CVC_RMCU_Ctrl "Signal counting the times of this message";
CM_ SG_ 172 CVC_RMCU_TargetTqReq "Rear Motor Target torque Request";
CM_ SG_ 172 CVC_RMCU_TargetSpeedReq "Rear Motor Target speed Request";
CM_ SG_ 172 CVC_RMCU_StsModeReq "RMCU Status Request";
CM_ SG_ 172 CVC_RMCU_TargetTqReqV "Rear Motor Target torque Request Validity";
CM_ SG_ 172 CVC_RMCU_TargetSpeedReqV "Rear Motor Target speed Request Validity";
CM_ SG_ 172 CVC_RMCU_VehicleDirect "Vehicle direct";
CM_ SG_ 172 CVC_RMCU_AtvDischg_Req "MCU Active Discharge Request";
CM_ SG_ 172 CVC_RMCU_CtrlModeReq "Control Mode Request";
CM_ SG_ 172 CVC_RMCU_ActiveHeatingReq "Heating Request";
CM_ SG_ 217 CRC_CVC_HV_DrvSys_status "Checksum";
CM_ SG_ 217 ALIVE_CVC_HV_DrvSys_status "Alive counter";
CM_ SG_ 217 CVC_HVsystem_status "High Voltage system status";
CM_ SG_ 217 CVC_ACPD_Percent "The signal contains the actual angle of the acceleration pedal100% acceleration pedal position shall only provided in case of kick down.Without kickdown the maximum value shall be 99.";
CM_ SG_ 217 CVC_ACPD_Percent_Valid "Qualifier for corresponding signal.  In value table not defined values are reserved";
CM_ SG_ 217 CVC_ACTGear "actual gear,Provide gear shift signal";
CM_ SG_ 217 CVC_ACTGearValid "Indicate the current gear position";
CM_ SG_ 217 CVC_ACT_DriveMode "Vehicle drive mode";
CM_ SG_ 217 CVC_ACT_DriveMode_Valid "Vehicle drive mode status";
CM_ SG_ 217 CVC_HV_DRVsystem_status "Status of driving system ( Highvoltage )";
CM_ SG_ 217 CVC_Recu_BrakeLight_ON_Req "CVC request brake light ON when regen";
CM_ SG_ 217 CVC_AccPedal_Valid "Accelerate pedal position signal Valid";
CM_ SG_ 217 CVC_StsAccPedalFault "Accelerate pedal fault status";
CM_ SG_ 217 CVC_StsSysFault "Drive system fault level";
CM_ SG_ 217 CVC_AccPedalPosition "Accelerate pedal position";
CM_ SG_ 266 CRC_BCM_VOLTAGE "Checksum";
CM_ SG_ 266 ALIVE_BCM_VOLTAGE "Alive counter";
CM_ SG_ 266 LV_BatteryType "LV Battery Type (Lead Acid or Lithium)";
CM_ SG_ 266 UBatt "Battery Voltage";
CM_ SG_ 266 LV_Batt_Temp_Reserved "Low voltage Battery Temperature";
CM_ SG_ 266 LV_SOC_Reserved "State Of charge for Low Voltage Battery";
CM_ SG_ 266 LV_Batt_Current_Reserved "Current of Low Voltage Battery";
CM_ SG_ 274 CRC_CVC_CLAMP_STAT "Checksum";
CM_ SG_ 274 ALIVE_CVC_CLAMP_STAT "Alive counter";
CM_ SG_ 274 CVC_STAT_BLS "Signal represent plausibility of both HW Inputs for brake light switch.";
CM_ SG_ 274 Vehicle_Operation_State "Represent the status of physical terminal";
CM_ SG_ 280 CVC_VehicleSpeed "Vehicle reference speed";
CM_ SG_ 280 CVC_VehicleSpeedValid "Indicate vehicle reference speed valid";
CM_ SG_ 280 CVC_HV_State "High voltage power-on status";
CM_ SG_ 306 ESC_SlopeGrade "Vehicle slope,Uphill is negative (head is higher than tail), downhill is positive (tail is higher than head)";
CM_ SG_ 306 ESC_HSA_Control_Status "Indicate HSA function is active or not";
CM_ SG_ 306 ESC_HSA_Status_Fault "Detect the HAS Fault status";
CM_ SG_ 306 ESC_TcsEnableSts "Indicate the TCS function can use or not";
CM_ SG_ 306 ESC_EscCtrlActv "Indicate ESC  function is active or not";
CM_ SG_ 306 ESC_TcsCtrlActv "Indicate TCS  function is active or not";
CM_ SG_ 306 ESC_EscFlgFlt "Detect the ESC function fault status";
CM_ SG_ 306 ESC_TcsFlgFlt "Detect the TCS function fault status";
CM_ SG_ 306 ESC_EscEnableSts "Indicate the ESC function can use or not";
CM_ SG_ 306 ESC_HBAFlgFlt "Detect the HBA(Hydraulic Brake Assist) function status";
CM_ SG_ 306 ESC_HbaCtrlActv "Indicate HBA(Hydraulic Brake Assist)   function is active or not";
CM_ SG_ 306 ESC_DTC_Active "DTC active or not";
CM_ SG_ 306 ESC_BTCSCtrlActv "Indicate Brake TCS is active or not";
CM_ SG_ 306 ESC_EngineCtrlActv "ESC Engine control active status(reserved)";
CM_ SG_ 344 CVC_PCU_StopReq "Engine stop request";
CM_ SG_ 344 CVC_PCU_StartReq "Engine start request";
CM_ SG_ 344 CVC_PCU_ActvDischg_Req "REX active discharge request";
CM_ SG_ 344 CVC_PCU_GenTargetPower "Target generator drive power";
CM_ SG_ 344 CVC_PCU_GenTargetVolt "Target generator voltage";
CM_ SG_ 344 CVC_PCU_GenTargetCurr "Target generator current";
CM_ SG_ 344 CVC_PCU_CurveSelection "Select engine operating curves";
CM_ SG_ 354 CVC_ModeGearSts "gear information";
CM_ SG_ 354 CVC_P_Sts "P gear status";
CM_ SG_ 354 CVC_IMMO_Sts "Indicates the IMMO Fail";
CM_ SG_ 354 CVC_RegencyLevInd "Indicates Regency Level";
CM_ SG_ 354 CVC_LimpHomeSts "Limp Home State";
CM_ SG_ 358 CRC_CVC_Status "CRC code to check the data integrity";
CM_ SG_ 358 ALIVE_CVC_Status "signal couting the times of this message";
CM_ SG_ 358 CVC_DriveModeSts "CVC_Drive Mode Status";
CM_ SG_ 358 CVC_DriveReady "Drive ready indicator";
CM_ SG_ 358 CVC_Fault "Vehicle Fault Level";
CM_ SG_ 358 CVC_VecFltInd "Vehicle Fault Indication";
CM_ SG_ 358 CVC_Creep_Sts "Creep Status";
CM_ SG_ 358 CVC_CruiseCtrlSts "cruise control Status";
CM_ SG_ 358 CVC_StsBrakePedalSwitch "Brake pedal Switch status";
CM_ SG_ 358 CVC_VehicleMode "Vehiclemodestatus";
CM_ SG_ 358 CVC_CruiseSetSpd "Cruise set speed";
CM_ SG_ 358 CVC_CruiseFaultIndication "CVC_Cruise Fault";
CM_ SG_ 358 CVC_FuelDetectionSwitchState "Fuel detection switch status feedback";
CM_ SG_ 358 CVC_FuelDetectionState "Fuel detection mode";
CM_ SG_ 358 CVC_ParkingChargeRequest "Parking charging switch";
CM_ SG_ 358 CVC_ParkingChargeModeSet "Parking charging mode setting";
CM_ SG_ 524 CRC_CVC_ODO "Checksum";
CM_ SG_ 524 ALIVE_CVC_ODO "Alive Counter";
CM_ SG_ 524 CVC_Odometer "Odometer information.";
CM_ BO_ 525 "WCBS status";
CM_ SG_ 525 CRC_WCBS_STATUS "Checksum";
CM_ SG_ 525 ALIVE_WCBS_STATUS "Alive counter";
CM_ SG_ 525 ABSFailed "ABS Fault Status";
CM_ SG_ 525 ABSActive "Further details when which bit will be set are defined within attached Excel file: Functions_Interventions File is at the moment under review at Bosch WCBS side";
CM_ SG_ 525 WCBS_VehicleSpeed "Vehicle Speed";
CM_ SG_ 525 ESC_VehicleStandstill "Vehicle stationary detected";
CM_ SG_ 525 WCBS_VehicleSpeedValid "Vehicle Speed Status";
CM_ SG_ 525 ESC_VehicleHoldStat "Set if vehicle stationary for ACC is detected";
CM_ SG_ 525 ABS_EBDFailed "Signal from ABS/ABS to indicate EBD failure for driver";
CM_ SG_ 525 ABS_HAZActive "Emergency Stop Active";
CM_ SG_ 525 ABS_LowBrakeFluid "Detect the brake fluid level";
CM_ SG_ 525 EBDActive "Signal from ABS/ABS to indicate if EBD is activate or not";
CM_ SG_ 525 WCBS_Mileage "Mileage in cm";
CM_ SG_ 525 WCBS_Veh_DriveCondition "Driving Condition";
CM_ SG_ 535 CRC_CVC_BMS_Information "Checksum";
CM_ SG_ 535 ALIVE_CVC_BMS_Information "Rolling Counter";
CM_ SG_ 535 CVC_DCChargeRelayP "DC charge positive relay request status";
CM_ SG_ 535 CVC_DCChargeRelayN "DC charge negative relay request status";
CM_ SG_ 535 CVC_BMS_PTCOnOff_Sts "CVC sends the status of the PTC Heater";
CM_ SG_ 535 CVC_BMS_ValveOnOff_Sts "CVC sends the status of the valve";
CM_ SG_ 535 CVC_BMS_PumpFB "CVC sends the PUMP feedback";
CM_ SG_ 563 CRC_CVC_FMCU_Limit "Checksum of this message";
CM_ SG_ 563 ALIVE_CVC_FMCU_Limit "Signal counting the times of this message";
CM_ SG_ 563 CVC_FMCU_DischgPwrLim "Limit Front Motor Discharge Power";
CM_ SG_ 563 CVC_FMCU_RegenPwrLim "Limit Front Motor Regen Power";
CM_ SG_ 565 CRC_CVC_RMCU_Limit "Checksum of this message";
CM_ SG_ 565 ALIVE_CVC_RMCU_Limit "Signal counting the times of this message";
CM_ SG_ 565 CVC_RMCU_DischgPwrLim "Limit Rear Motor Discharge Power";
CM_ SG_ 565 CVC_RMCU_RegenPwrLim "Limit Rear Motor Regen Power";
CM_ SG_ 564 CVC_DCDC_StsModeReq "CVC to DCDC control command";
CM_ SG_ 564 CVC_vDCDCRequest "voltage output request for DCDC";
CM_ SG_ 564 CVC_DCDC_CurrentLim "Limit DCDC Output Current";
CM_ SG_ 564 CVC_DCDC_PwrPermit "Permit DCDC Output Power";
CM_ SG_ 746 InteriorTemperature "Interior Temprature value from LIN UIF_Temperature";
CM_ SG_ 746 CVC_SW_Versions "CVC software version";
CM_ SG_ 746 CVC_Fan_Sts "CVC control fan status";
CM_ SG_ 746 CVC_DCChgPosTemp "The Positive Temperature of DC Charging";
CM_ SG_ 746 CVC_DCChgNegTemp "The Negative Temperature of DC Charging";
CM_ SG_ 746 CVC_ACChgLTerminalTemp "Temperature of AC Charging L terminal";
CM_ SG_ 746 CVC_ACChgNTerminalTemp_Reserve "Temperature of AC Charging  N terminal_Reserve";
CM_ SG_ 746 CVC_EdrivePump_Sts "Electric drive water pump working status";
CM_ SG_ 746 CVC_BatPump_Sts "Battery water pump working status";
CM_ SG_ 746 CVC_ActiveHeatingPower "Active heating power for PTC in battery pre-heat for debugging";
CM_ SG_ 760 DISP_HR "The signal / parameter indicates the current hour.";
CM_ SG_ 760 DISP_MN "The signal / parameter indicates the current minute.";
CM_ SG_ 760 DISP_SEC "The signal / parameter indicates the current second.";
CM_ SG_ 760 DISP_DATE_DAY "The signal / parameter indicates the current day.";
CM_ SG_ 760 DISP_DATE_MON "The signal / parameter indicates the current month.";
CM_ SG_ 760 DISP_DATE_WDAY "The signal   parameter indicates the current day of the week.";
CM_ SG_ 760 DISP_DATE_YR "The signal / parameter indicates the current year.";
CM_ SG_ 760 ST_DISP_CTI_DATE "The signal / parameter indicates the state of the switch summer winter time.";
CM_ SG_ 852 CVC_SOV1_ControlReq "Request ON/OFF SOV 1";
CM_ SG_ 852 CVC_MotorWaterPump_OnOff_Req "Request ON/OFF Motor water pump";
CM_ SG_ 852 CVC_MainRelay_OnOff_Req "Request ON/OFF main relay";
CM_ SG_ 852 CVC_ElectricFan_Enable "Request ON/OFF electric fan lo speed";
CM_ SG_ 852 CVC_BatteryWaterPump_OnOff_Req "Request ON/OFF Battery water pump";
CM_ SG_ 852 CVC_EAC_OnOff_Req "Enable Operation of HV-EAC";
CM_ SG_ 852 CVC_PGearStatusLight_OnOff_Req "Request ON/OFF P Gear Status Light";
CM_ SG_ 852 CVC_MotorWaterPump_PWM_Req "Request PWM value to control Motor water pump";
CM_ SG_ 852 CVC_BatteryWaterPump_PWM_Req "Request PWM value to control Baterry water pump";
CM_ SG_ 852 CVC_PTC_OnOff_Req "Enable Operation of HV-PTC";
CM_ SG_ 852 CVC_ExpValve_OnOff_Req "Request ON/OFF Expansion Valve";
CM_ SG_ 852 CVC_SOV2_ControlReq "Request ON/OFF SOV 2";
CM_ SG_ 852 CVC_DriveCoolWaterFlowRate "Actual drive cool water flow rate";
CM_ SG_ 852 CVC_EACAllowedPower "EAC Allowed Power";
CM_ SG_ 852 CVC_ElectricFan_PWM_Req "Request PWM to electric fan speed";
CM_ SG_ 858 CRC_CVC_CP_Req "Checksum";
CM_ SG_ 858 ALIVE_CVC_CP_Req "Alive counter";
CM_ SG_ 858 CVC_LockCP_Req "Indicate the request for EVCC to lock/unlock the charge port.";
CM_ SG_ 862 CRC_CVC_Vehicle_info "Checksum";
CM_ SG_ 862 ALIVE_CVC_Vehicle_info "Alive counter";
CM_ SG_ 862 CVC_VehLock_STS "Vehicle Lock Status";
CM_ SG_ 862 CVC_VehSpd_ScreenDisplay "Indicate the display speed on HMI screen calculated according to Vehicle actual speed.";
CM_ SG_ 862 CVC_VehChgAllow "Indicate the request to allow the vehicle to start charging";
CM_ SG_ 862 CVC_VehDischgAllow "Indicate the request to allow the vehicle to start discharging";
CM_ SG_ 862 Re_InitCharging_Req "Request re-initiate charging";
CM_ SG_ 862 CVC_StopChg_Req "Stop charging request";
CM_ SG_ 862 CVC_GunUnlock_Req "Unlock charging gun request";
CM_ SG_ 862 CVC_Ack_LimitSetting_SOC "Indicate the acknowledge setting value for the limit of the HV state-of-charge.";
CM_ SG_ 862 CVC_ACInputChgCurLim "Indicate the setting value for the limit of the AC input charge current.";
CM_ SG_ 862 CVC_HV_DispSOC "Indicate the state-of-charge of the HV battery rounded by CVC to display to user";
CM_ SG_ 862 CVC_HV_Cur_LoadComp "Indicate the necessary current estimated by CVC to compensate HV load during charging.";
CM_ SG_ 884 PTC_PCBT "PTC_PCB temperature";
CM_ SG_ 884 PTC_Crt "Current working current of PTC";
CM_ SG_ 884 PTC_CrtSts "Current working status of PTC";
CM_ SG_ 884 PTC_HVIntlkFlt "PTC High Voltage Interlock Malfunction-P164B94-E00";
CM_ SG_ 884 PTC_ComLost_ECC "PTC and ECC communication loss fault U198187-E00";
CM_ SG_ 884 PTC_OverCrtFlt "PTC overcurrent fault";
CM_ SG_ 884 PTC_HVUnderVoltFlt "PTC high voltage undervoltage fault";
CM_ SG_ 884 PTC_HVOverVoltFlt "PTC high voltage overvoltage fault";
CM_ SG_ 884 PTC_ChkBattOverVoltFlt "PTC detects high battery voltage fault U190017-E00";
CM_ SG_ 884 PTC_ChkBattUnderVoltFlt "PTC detects low battery voltage fault _ U190016_ E00";
CM_ SG_ 884 PTC_InlTSnsrFlt "PTC inlet temperature sensor malfunction-P16491C-E00";
CM_ SG_ 884 PTC_OutlTSnsrFlt "PTC outlet temperature sensor malfunction-P164A1C_E00";
CM_ SG_ 884 PTC_InlOverTFlt "PTC inlet temperature over temperature fault _ P164998-E00";
CM_ SG_ 884 PTC_OutlOverTFlt "PTC outlet temperature over temperature fault";
CM_ SG_ 884 PTC_PCBOverTFlt "PTC circuit board (PCB) overheating fault";
CM_ SG_ 884 PTC_PCBTSnsrFlt "PTC Circuit Board (PCB) Temperature Sensor Malfunction-P16481C_E00";
CM_ SG_ 884 PTC_PwrOutpFlt "PTC power output fault _ P164C00_ E00";
CM_ SG_ 889 PTC_InpT "PTC inlet temperature";
CM_ SG_ 889 PTC_OutpT "PTC outlet temperature";
CM_ SG_ 889 PTC_CrtPwr "PTC current power";
CM_ SG_ 889 PTC_CrtT "PTC current operating temperature";
CM_ SG_ 889 PTC_IninSts "PTC initialization status";
CM_ SG_ 889 PTC_HVPwrSplySts "PTC high voltage power supply status";
CM_ SG_ 889 PTC_ActGear "PTC actual gear position";
CM_ SG_ 889 PTC_Mod "PTC current working mode";
CM_ SG_ 891 CVC_Front_SOV_OnOff_Sts "Front SOV OnOff Status";
CM_ SG_ 891 CVC_Rear_SOV_OnOff_Sts "Rear SOV OnOff Status";
CM_ SG_ 896 VIN_Byte1 "This signal contains the seventh last digit of the chassis number. (The individual digits are encoded in ASCII characters.)Bit 0: LSB, Bit 7: MSB";
CM_ SG_ 896 VIN_Byte2 "This signal contains the sixth last digit of the chassis number. (The individual digits are encoded in ASCII characters.)Bit 0: LSB, Bit 7: MSB";
CM_ SG_ 896 VIN_Byte3 "This signal contains the fifth last digit of the chassis number. (The individual digits are encoded in ASCII characters.)Bit 0: LSB, Bit 7: MSB";
CM_ SG_ 896 VIN_Byte4 "This signal contains the fourth last digit of the chassis number. (The individual digits are encoded in ASCII characters.)Bit 0: LSB, Bit 7: MSB";
CM_ SG_ 896 VIN_Byte5 "This signal contains the third last digit of the chassis number. (The individual digits are encoded in ASCII characters.)Bit 0: LSB, Bit 7: MSB";
CM_ SG_ 896 VIN_Byte6 "This signal contains the penultimate digit of the chassis number. (The individual digits are encoded in ASCII characters.)Bit 0: LSB, Bit 7: MSB";
CM_ SG_ 896 VIN_Byte7 "This signal contains the last digit of the chassis number. (The individual digits are encoded in ASCII characters.)Bit 0: LSB, Bit 7: MSB";
CM_ SG_ 1121 EAC_speed "Electric Air Compressor Speed";
CM_ SG_ 1121 EAC_status "Electric Air Compressor Status";
CM_ SG_ 1121 EAC_input_voltage "Electric Air Compressor Input Voltage";
CM_ SG_ 1121 EAC_input_current "Electric Air Compressor Input Current";
CM_ SG_ 1121 EAC_inv_temp "Electric Air Compressor Inverter Temperature";
CM_ SG_ 1121 EAC_phase_curr "Electric Air Compressor Phase Current";
CM_ SG_ 1873 CVC_DebugDiag2 "CVC Acm component error level";
CM_ SG_ 1873 CVC_DebugDiag1 "CVC xGW component error level";
CM_ SG_ 1873 CVC_DebugDiag5 "CVC Regen brake component error level";
CM_ SG_ 1873 CVC_DebugDiag4 "CVC Idb component error level";
CM_ SG_ 1873 CVC_DebugDiag3 "CVC Brake component error level";
CM_ SG_ 1873 CVC_DebugDiag8 "CVC Ags component error level";
CM_ SG_ 1873 CVC_DebugDiag7 "CVC Lvd component error level";
CM_ SG_ 1873 CVC_DebugDiag6 "CVC Eds component error level";
CM_ SG_ 1873 CVC_DebugDiag10 "CVC Fan component error level";
CM_ SG_ 1873 CVC_DebugDiag9 "CVC Ptc component error level";
CM_ SG_ 1873 CVC_DebugDiag13 "CVC Valve component error level";
CM_ SG_ 1873 CVC_DebugDiag12 "CVC Tsen component error level";
CM_ SG_ 1873 CVC_DebugDiag11 "CVC Hvac component error level";
CM_ SG_ 1873 CVC_DebugDiag16 "CVC Bms component error level";
CM_ SG_ 1873 CVC_DebugDiag15 "CVC Vehicle speed component error level";
CM_ SG_ 1873 CVC_DebugDiag14 "CVC Water pump component error level";
CM_ SG_ 1873 CVC_DebugDiag18 "CVC Accelerator pedal component error level";
CM_ SG_ 1873 CVC_DebugDiag17 "CVC Obc component error level";
CM_ SG_ 1873 CVC_DebugDiag20 "CVC Dcdc component error level";
CM_ SG_ 1873 CVC_DebugDiag19 "CVC charging component errror level";
CM_ SG_ 1874 CVC_Debug1 "PUPD_state";
CM_ SG_ 1874 CVC_Debug2 "Charging Status";
CM_ SG_ 1874 CVC_Debug3 "Termal Status";
CM_ SG_ 1874 CVC_Debug4 "CVC Diagnostic System Error Level";
CM_ BO_ 1878 "BMS XCPRx";
CM_ SG_ 1878 BMS_XCPRxData "XCP RX signal";
CM_ SG_ 537 EVCC_OBC_StsModeReq "BMS Mode Request of OBC";
CM_ SG_ 537 EVCC_ACChgVoltAllow "BMS AC Charge Voltage Allow";
CM_ SG_ 537 EVCC_ACChgCurReq "BMS AC Charge Current Request";
CM_ SG_ 537 EVCC_S2_Sts "S2 State";
CM_ SG_ 537 EVCC_StsChgCC "Charge CC State";
CM_ SG_ 537 EVCC_CP_DutyCycle "CP duty cycle";
CM_ SG_ 593 EVCC_ChargeMode "Charge mode";
CM_ SG_ 593 EVCC_DCChgPosTemp "The Positive Temperature of DC Charging";
CM_ SG_ 593 EVCC_DCChgNegTemp "The Negative Temperature of DC Charging";
CM_ SG_ 593 EVCC_ACChgL1TerminalTemp "Temperature of AC Charging L terminal";
CM_ SG_ 593 EVCC_ACChgNTerminalTemp_Reserve "Temperature of AC Charging  N terminal_Reserve";
CM_ SG_ 696 ALIVE_EVCC_VehDischg_Sts "Alive counter";
CM_ SG_ 696 EVCC_VehDischg_Sts "Indicate the charging status";
CM_ SG_ 696 EVCC_V2L_adapter_Sts "Indicate the V2L adapter status";
CM_ SG_ 696 OBC_ACOutputCur_Req "Indicate the request for the OBC AC output voltage";
CM_ SG_ 696 OBC_ACOutputVol_Req "Indicate the request for the OBC AC output current";
CM_ SG_ 696 EVCC_ConnectorType_Sts "Add new state to define ConnectorType when V2L adapter not connect";
CM_ SG_ 843 CRC_EVCC_EVSE_Info_1 "Checksum";
CM_ SG_ 843 ALIVE_EVCC_EVSE_Info_1 "Alive counter";
CM_ SG_ 843 EVSE_DC_Stt "Debug Indicate DC-EVSE internal state, element DC_EVSEStatusCode as definded in annex C.6, ISO 15118- 2:2016.";
CM_ SG_ 843 EVSE_CtrlPilot_PWM_value "(Debug) Indicate the PWM value of Control Pilot.";
CM_ SG_ 843 EVSE_CtrlPilot_STS "(Debug) Indicate Control Pilot state, as definded in Table A.4, IEC 61851-1:2017";
CM_ SG_ 843 EVSE_IsolationLvl "(Debug) Indicate EVSE isolation level, element EVSEIsolationStatus as definded in annex C.6, ISO 15118- 2:2016.";
CM_ SG_ 843 EVSE_VehChgComm_STAT "(Debug) Indicate vehicle charging communication state.";
CM_ SG_ 843 EVSE_ResponseCode "(Debug) Indicate EVSE response code, element responseCode as definded in annex C.6, ISO 15118-2:2016.";
CM_ SG_ 843 EVSE_AC_MaxLineCur "The information sent from EVSE to indicate the maximum line current per phase the EV can draw. Element EVSEMaxCurrent as definded in ISO 15118-2:2016.";
CM_ SG_ 845 CRC_EVCC_Req "Checksum";
CM_ SG_ 845 ALIVE_EVCC_Req "Alive counter";
CM_ SG_ 845 EVCC_STAT_BrakeSts "Braking status of EVCC";
CM_ SG_ 845 EVCC_Req_InsulationMon "Indicate the request on/off insulation monitor for DC charging from EVCC.";
CM_ SG_ 845 EVCC_PnC_Contract_STS "Indicate the status of the PnC Contract Certificate";
CM_ SG_ 845 EVCC_FcContactor_Req "Indicate the requested state of FC contactors.";
CM_ SG_ 847 CRC_EVCC_EVSE_Info_2 "Checksum";
CM_ SG_ 847 ALIVE_EVCC_EVSE_Info_2 "Alive counter";
CM_ SG_ 847 EVSE_DC_MaxChgCur "(Debug) The information sent from EVSE to indicate the maximum DC current the EVSE can deliver. Element EVSEMaximumCurrentLimit as definded in ISO 15118-2:2016.";
CM_ SG_ 847 EVSE_DC_MaxChgPwr "The information was sent from EVSE to indicate the maximum DC power the EVSE can deliver. Element EVSEMaximumPowerLimit as definded in ISO 15118-2:2016.";
CM_ SG_ 847 EVSE_DC_ActCurOut "(Debug) The information was sent from EVSE to indicate the present output current of the EVSE. Element EVSEPresentCurrent as definded in ISO 15118-2:2016.";
CM_ SG_ 850 EVCC_ACTemperature "EVCC get temperature signal from Temp and pressure sensor";
CM_ SG_ 850 EVCC_Motor_TempSensor "EVCC get temperature signal from Motor colling temp sensor";
CM_ SG_ 850 EVCC_MotorWaterPump_PWM_fb "Feedback of Motor water pump PWM";
CM_ SG_ 850 EVCC_SOV2_ControlStatus "Status ON/OFF SOV 2";
CM_ SG_ 850 EVCC_BatteryWaterPump_PWM_fb "Feedback of Battery water pump PWM";
CM_ SG_ 850 EVCC_SOV1_ControlStatus "Status ON/OFF SOV 1";
CM_ SG_ 850 EVCC_MotorWaterPump_Status "Status of Motor water pump";
CM_ SG_ 850 EVCC_BatteryWaterPump_Status "Status of Battery water pump";
CM_ SG_ 850 EVCC_ACPressure "EVCC_ACPressure EVCC get pressure signal from Temp and pressure sensor";
CM_ SG_ 850 EVCC_PTC_OnOff_Status "Operation status of heater";
CM_ SG_ 851 EVCC_EAC_OnOff_Status "Operation status of EAC";
CM_ SG_ 851 EVCC_DualPressureSwitch_Status "Status of dual pressure switch";
CM_ SG_ 851 EVCC_MainRelay_OnOff_Status "Operation status of main relay";
CM_ SG_ 851 EVCC_ElectricFan_OnOff_Sts "Status ON/OFF electric fan lo speed";
CM_ SG_ 851 EVCC_CL15_Status "Status of Ignition on switch";
CM_ SG_ 851 EVCC_PGearPressSignal1_Status "Status of P Gear Press Signal 1";
CM_ SG_ 851 EVCC_PGearStsLight_OnOff_Sts "Status ON/OFF P Gear Status Light";
CM_ SG_ 851 EVCC_PGearPressSignal2_Status "Status of P Gear Press Signal 2";
CM_ SG_ 851 EVCC_ExpValve_OnOff_Status "Status ON/OFF of Expansion Valve";
CM_ SG_ 851 EVCC_EACPTCHVIL_Status "HVIL status of EAC and PTC";
CM_ SG_ 851 EVCC_ElectricFan_PWM_fb "Feedback of electric fan speed PWM";
CM_ SG_ 859 CRC_EVCC_ACCharging_Req "Checksum";
CM_ SG_ 859 ALIVE_EVCC_ACCharging_Req "Alive counter";
CM_ SG_ 859 OBC_Req "Indicate the request of the OBC state";
CM_ SG_ 859 OBC_OutputVol_Req "Indicate the request for the OBC output voltage.";
CM_ SG_ 859 OBC_OutputCur_Req "Indicate the request for the OBC output current";
CM_ SG_ 859 OBC_ACInputChgCurLim "Indicate the request for the limit of the OBC input current.";
CM_ SG_ 892 CRC_EVCC_Charging_Sts "Checksum";
CM_ SG_ 892 ALIVE_EVCC_Charging_Sts "Alive counter";
CM_ SG_ 892 EVCC_ChgGun_Sts "Indicate the status of the charge gun: whether it is connected, removed, or if there is an error.";
CM_ SG_ 892 EVCC_ChgFlap_Sts "Indicate the status of the charge flap: whether it is opened, closed and locked or released.";
CM_ SG_ 892 EVCC_ChgType "Indicate the charging type for the charging session. The charging type is detected via the PWM value of the CP pin and the message pair ServiceDiscovery during PLC communication";
CM_ SG_ 892 EVCC_VehChg_Sts "Indicate the charging status.";
CM_ SG_ 892 EVCC_ChgAuthen_Sts "Indicate the authentication status of charging session, whether the vehicle and the EVSE is compatible or not.";
CM_ SG_ 892 EVCC_PaymentType "Description Indicate the payment type for the charging session.";
CM_ SG_ 892 EVCC_VehChgCompError_Sts "Indicate the error status of the charging components from the vehicle.";
CM_ SG_ 892 EVCC_ProximityPilot_Voltage "Indicate the measure voltage of Proximity pilot (PP) pin";
CM_ SG_ 892 EVCC_S3Button_Sts "S3 button state";
CM_ BO_ 90 "FMCU Reset Information";
CM_ SG_ 90 FMCU_Trap_Tin "FMCU Trap Tin";
CM_ SG_ 90 FMCU_Trap_Class "FMCU Trap Class";
CM_ SG_ 90 FMCU_ReturnAddress "FMCU Return Address";
CM_ SG_ 90 FMCU_DEADD_Value "FMCU DEADD Value";
BA_DEF_ BO_  "DiagRequest" ENUM  "No","Yes";
BA_DEF_ BO_  "DiagResponse" ENUM  "No","Yes";
BA_DEF_ BO_  "DiagState" ENUM  "No","Yes";
BA_DEF_ BO_  "GenMsgCycleTime" INT 0 65535;
BA_DEF_ BO_  "GenMsgCycleTimeFast" INT 0 65535;
BA_DEF_ BO_  "GenMsgDelayTime" INT 0 65535;
BA_DEF_ BO_  "GenMsgILSupport" ENUM  "No","Yes";
BA_DEF_ BO_  "GenMsgNrOfRepetition" INT 0 65535;
BA_DEF_ BO_  "GenMsgSendType" ENUM  "Cyclic","NoMsgSendType","NotUsed","NotUsed","NotUsed","NotUsed","NotUsed","IfActive","NoMsgSendType","NotUsed";
BA_DEF_ BO_  "NmAsrMessage" ENUM  "No","Yes";
BA_DEF_ BO_  "NmMessage" ENUM  "No","Yes";
BA_DEF_ SG_  "GenSigSendType" ENUM  "Cyclic","NoSigSendType","OnWriteWithRepetition","OnChange","OnChangeWithRepetition","IfActive","IfActiveWithRepetition","OnWrite","NotUsed","NotUsed","NotUsed","NotUsed","NotUsed";
BA_DEF_ SG_  "GenSigStartValue" INT 0 2147483647;
BA_DEF_ SG_  "GenSigTimeoutTime_ALL" INT 0 65535;
BA_DEF_ SG_  "InvalidValue" STRING ;
BA_DEF_ SG_  "GenSigInactiveValue" INT 0 2147483647;
BA_DEF_ BU_  "ILUsed" ENUM  "No","Yes";
BA_DEF_ BU_  "NmStationAddress" HEX 0 0;
BA_DEF_ BU_  "Address" HEX 0 255;
BA_DEF_ BU_  "NmAsrCanMsgReducedTime" INT 320 640;
BA_DEF_ BU_  "NmAsrNode" ENUM  "No","Yes";
BA_DEF_ BU_  "NmAsrNodeIdentifier" HEX 0 255;
BA_DEF_ BU_  "TpSTMin" INT 0 255;
BA_DEF_  "Baudrate" INT 1000 1000000;
BA_DEF_  "BaudRateCANFD" FLOAT 1000 10000000;
BA_DEF_ BO_  "VFrameFormat" ENUM  "StandardCAN","ExtendedCAN","reserved","J1939PG","reserved","reserved","reserved","reserved","reserved","reserved","reserved","reserved","reserved","reserved","StandardCAN_FD","ExtendedCAN_FD";
BA_DEF_ BO_  "CANFD_BRS" ENUM  "0","1";
BA_DEF_  "DBName" STRING ;
BA_DEF_  "BusType" STRING ;
BA_DEF_  "Manufacturer" STRING ;
BA_DEF_  "NmAsrBaseAddress" HEX 0 2047;
BA_DEF_  "NmAsrCanMsgCycleTime" INT 0 65535;
BA_DEF_  "NmAsrMessageCount" INT 1 256;
BA_DEF_  "NmAsrRepeatMessageTime" INT 0 65535;
BA_DEF_  "NmAsrTimeoutTime" INT 0 65535;
BA_DEF_  "NmAsrWaitBusSleepTime" INT 0 65535;
BA_DEF_  "NmType" STRING ;
BA_DEF_ SG_  "SystemSignalLongSymbol" STRING ;
BA_DEF_DEF_  "DiagRequest" "No";
BA_DEF_DEF_  "DiagResponse" "No";
BA_DEF_DEF_  "DiagState" "No";
BA_DEF_DEF_  "GenMsgCycleTime" 0;
BA_DEF_DEF_  "GenMsgCycleTimeFast" 0;
BA_DEF_DEF_  "GenMsgDelayTime" 0;
BA_DEF_DEF_  "GenMsgILSupport" "Yes";
BA_DEF_DEF_  "GenMsgNrOfRepetition" 0;
BA_DEF_DEF_  "GenMsgSendType" "Cyclic";
BA_DEF_DEF_  "NmAsrMessage" "No";
BA_DEF_DEF_  "NmMessage" "No";
BA_DEF_DEF_  "GenSigSendType" "Cyclic";
BA_DEF_DEF_  "GenSigStartValue" 0;
BA_DEF_DEF_  "GenSigTimeoutTime_ALL" 0;
BA_DEF_DEF_  "InvalidValue" "";
BA_DEF_DEF_  "GenSigInactiveValue" 0;
BA_DEF_DEF_  "ILUsed" "Yes";
BA_DEF_DEF_  "NmStationAddress" 0;
BA_DEF_DEF_  "Address" 0;
BA_DEF_DEF_  "NmAsrCanMsgReducedTime" 320;
BA_DEF_DEF_  "NmAsrNode" "No";
BA_DEF_DEF_  "NmAsrNodeIdentifier" 0;
BA_DEF_DEF_  "TpSTMin" 20;
BA_DEF_DEF_  "Baudrate" 500000;
BA_DEF_DEF_  "BaudRateCANFD" 2000000;
BA_DEF_DEF_  "VFrameFormat" "StandardCAN_FD";
BA_DEF_DEF_  "CANFD_BRS" "1";
BA_DEF_DEF_  "DBName" "";
BA_DEF_DEF_  "BusType" "";
BA_DEF_DEF_  "Manufacturer" "LaunchDesign";
BA_DEF_DEF_  "NmAsrBaseAddress" 1280;
BA_DEF_DEF_  "NmAsrCanMsgCycleTime" 640;
BA_DEF_DEF_  "NmAsrMessageCount" 128;
BA_DEF_DEF_  "NmAsrRepeatMessageTime" 3200;
BA_DEF_DEF_  "NmAsrTimeoutTime" 2000;
BA_DEF_DEF_  "NmAsrWaitBusSleepTime" 1500;
BA_DEF_DEF_  "NmType" "NmAsr";
BA_DEF_DEF_  "SystemSignalLongSymbol" "";
BA_ "Manufacturer" "VinFast";
BA_ "BusType" "CAN FD";
BA_ "DBName" "PCAN";
BA_ "NmAsrNode" BU_ BMS 1;
BA_ "NmAsrNodeIdentifier" BU_ BMS 19;
BA_ "Address" BU_ BMS 19;
BA_ "NmStationAddress" BU_ BMS 19;
BA_ "NmAsrNode" BU_ CVC_P 1;
BA_ "NmAsrNodeIdentifier" BU_ CVC_P 2;
BA_ "Address" BU_ CVC_P 2;
BA_ "NmStationAddress" BU_ CVC_P 2;
BA_ "NmAsrNode" BU_ EVCC 1;
BA_ "NmAsrNodeIdentifier" BU_ EVCC 31;
BA_ "Address" BU_ EVCC 31;
BA_ "NmStationAddress" BU_ EVCC 31;
BA_ "NmAsrNode" BU_ FMCU 1;
BA_ "NmAsrNodeIdentifier" BU_ FMCU 27;
BA_ "Address" BU_ FMCU 27;
BA_ "NmStationAddress" BU_ FMCU 27;
BA_ "NmAsrNode" BU_ RMCU 1;
BA_ "NmAsrNodeIdentifier" BU_ RMCU 26;
BA_ "Address" BU_ RMCU 26;
BA_ "NmStationAddress" BU_ RMCU 26;
BA_ "NmAsrNode" BU_ POD_GW 1;
BA_ "NmAsrNodeIdentifier" BU_ POD_GW 63;
BA_ "Address" BU_ POD_GW 63;
BA_ "NmStationAddress" BU_ POD_GW 63;
BA_ "NmAsrNode" BU_ PCU 1;
BA_ "NmAsrNodeIdentifier" BU_ PCU 56;
BA_ "Address" BU_ PCU 56;
BA_ "NmStationAddress" BU_ PCU 56;
BA_ "NmAsrNodeIdentifier" BU_ ADCU_P 64;
BA_ "Address" BU_ ADCU_P 64;
BA_ "NmStationAddress" BU_ ADCU_P 64;
BA_ "GenMsgCycleTime" BO_ 133 20;
BA_ "GenMsgCycleTime" BO_ 294 20;
BA_ "GenMsgCycleTime" BO_ 296 20;
BA_ "GenMsgCycleTime" BO_ 372 20;
BA_ "GenMsgCycleTime" BO_ 521 20;
BA_ "GenMsgCycleTime" BO_ 533 50;
BA_ "GenMsgCycleTime" BO_ 534 50;
BA_ "GenMsgCycleTime" BO_ 581 20;
BA_ "GenMsgCycleTime" BO_ 585 100;
BA_ "GenMsgCycleTime" BO_ 592 100;
BA_ "GenMsgCycleTime" BO_ 816 100;
BA_ "GenMsgCycleTime" BO_ 818 100;
BA_ "GenMsgCycleTime" BO_ 885 50;
BA_ "GenMsgCycleTime" BO_ 1110 100;
BA_ "GenMsgCycleTime" BO_ 1146 1000;
BA_ "GenMsgCycleTime" BO_ 1171 1000;
BA_ "GenMsgCycleTime" BO_ 1952 2000;
BA_ "GenMsgCycleTime" BO_ 1953 1000;
BA_ "GenMsgCycleTime" BO_ 1954 1000;
BA_ "GenMsgCycleTime" BO_ 1955 1000;
BA_ "GenMsgCycleTime" BO_ 1956 1000;
BA_ "GenMsgSendType" BO_ 1939 1;
BA_ "GenMsgCycleTime" BO_ 169 100;
BA_ "GenMsgCycleTime" BO_ 170 10;
BA_ "GenMsgCycleTime" BO_ 171 10;
BA_ "GenMsgCycleTime" BO_ 172 10;
BA_ "GenMsgCycleTime" BO_ 217 20;
BA_ "GenMsgCycleTime" BO_ 266 100;
BA_ "GenMsgCycleTime" BO_ 274 100;
BA_ "GenMsgCycleTime" BO_ 280 20;
BA_ "GenMsgCycleTime" BO_ 306 20;
BA_ "GenMsgCycleTime" BO_ 344 20;
BA_ "GenMsgCycleTime" BO_ 354 20;
BA_ "GenMsgCycleTime" BO_ 358 20;
BA_ "GenMsgCycleTime" BO_ 524 100;
BA_ "GenMsgCycleTime" BO_ 525 20;
BA_ "GenMsgCycleTime" BO_ 535 100;
BA_ "GenMsgCycleTime" BO_ 563 100;
BA_ "GenMsgCycleTime" BO_ 565 100;
BA_ "GenMsgCycleTime" BO_ 564 100;
BA_ "GenMsgCycleTime" BO_ 746 200;
BA_ "GenMsgCycleTime" BO_ 760 1000;
BA_ "GenMsgCycleTime" BO_ 852 100;
BA_ "GenMsgCycleTime" BO_ 858 100;
BA_ "GenMsgCycleTime" BO_ 862 100;
BA_ "GenMsgCycleTime" BO_ 884 100;
BA_ "GenMsgCycleTime" BO_ 889 100;
BA_ "GenMsgCycleTime" BO_ 891 100;
BA_ "GenMsgCycleTime" BO_ 896 1000;
BA_ "GenMsgCycleTime" BO_ 1121 200;
BA_ "GenMsgCycleTime" BO_ 1873 100;
BA_ "GenMsgCycleTime" BO_ 1874 100;
BA_ "GenMsgSendType" BO_ 1878 1;
BA_ "GenMsgNrOfRepetition" BO_ 1968 2;
BA_ "GenMsgCycleTimeFast" BO_ 1968 50;
BA_ "GenMsgCycleTime" BO_ 1968 15000;
BA_ "GenMsgCycleTime" BO_ 537 100;
BA_ "GenMsgCycleTime" BO_ 593 100;
BA_ "GenMsgCycleTime" BO_ 696 100;
BA_ "GenMsgCycleTime" BO_ 843 100;
BA_ "GenMsgCycleTime" BO_ 845 100;
BA_ "GenMsgCycleTime" BO_ 847 100;
BA_ "GenMsgCycleTime" BO_ 850 100;
BA_ "GenMsgCycleTime" BO_ 851 100;
BA_ "GenMsgCycleTime" BO_ 859 100;
BA_ "GenMsgCycleTime" BO_ 892 100;
BA_ "GenMsgCycleTime" BO_ 1145 100;
BA_ "GenMsgCycleTime" BO_ 90 100;
BA_ "GenSigTimeoutTime_ALL" SG_ 133 CRC_ACU_CRASH_INFO 200;
BA_ "GenSigTimeoutTime_ALL" SG_ 133 ALIVE_ACU_CRASH_INFO 200;
BA_ "InvalidValue" SG_ 133 ALIVE_ACU_CRASH_INFO "Fh";
BA_ "GenSigTimeoutTime_ALL" SG_ 133 ACU_Crash_Sts 200;
BA_ "InvalidValue" SG_ 133 ACU_Crash_Sts "3h";
BA_ "GenSigTimeoutTime_ALL" SG_ 133 ACU_Airbag_Deployment_Status 200;
BA_ "InvalidValue" SG_ 133 ACU_Airbag_Deployment_Status "3h";
BA_ "GenSigTimeoutTime_ALL" SG_ 133 ACU_Crash_Intensity 200;
BA_ "InvalidValue" SG_ 133 ACU_Crash_Intensity "7h";
BA_ "GenSigTimeoutTime_ALL" SG_ 133 ACU_Front_Crash 200;
BA_ "InvalidValue" SG_ 133 ACU_Front_Crash "3h";
BA_ "GenSigTimeoutTime_ALL" SG_ 133 ACU_DriverSide_Crash 200;
BA_ "InvalidValue" SG_ 133 ACU_DriverSide_Crash "3h";
BA_ "GenSigTimeoutTime_ALL" SG_ 133 ACU_PassSide_Crash 200;
BA_ "InvalidValue" SG_ 133 ACU_PassSide_Crash "3h";
BA_ "GenSigTimeoutTime_ALL" SG_ 133 ACU_Rear_Crash 200;
BA_ "InvalidValue" SG_ 133 ACU_Rear_Crash "3h";
BA_ "GenSigTimeoutTime_ALL" SG_ 133 ACU_Rollover_Crash 200;
BA_ "InvalidValue" SG_ 133 ACU_Rollover_Crash "3h";
BA_ "InvalidValue" SG_ 294 ALIVE_BMS_AllowChargeCurr "Fh";
BA_ "InvalidValue" SG_ 296 ALIVE_BMS_AllowDischargeCurr "Fh";
BA_ "InvalidValue" SG_ 372 ALIVE_BMS_CurMeas "Fh";
BA_ "GenSigStartValue" SG_ 372 BMS_PackCur_MEAS 32768;
BA_ "GenSigStartValue" SG_ 372 BMS_PackInsuRes 5535;
BA_ "InvalidValue" SG_ 521 ALIVE_BMS_PowerCont "Fh";
BA_ "InvalidValue" SG_ 533 ALIVE_BMS_Sts "Fh";
BA_ "GenSigStartValue" SG_ 533 BMS_SOH 54;
BA_ "GenSigStartValue" SG_ 533 BMS_SOE 54;
BA_ "InvalidValue" SG_ 533 BMS_HV_Sts "FFh";
BA_ "InvalidValue" SG_ 534 ALIVE_BMS_ChgParamReq "Fh";
BA_ "InvalidValue" SG_ 581 ALIVE_BMS_CellTemp "Fh";
BA_ "GenSigStartValue" SG_ 581 BMS_ProbeNumMaxCellTemp 1;
BA_ "GenSigStartValue" SG_ 581 BMS_MinCellTemp 80;
BA_ "GenSigStartValue" SG_ 581 BMS_PackTemp 80;
BA_ "GenSigStartValue" SG_ 581 BMS_MaxCellTemp 80;
BA_ "GenSigStartValue" SG_ 581 BMS_MaxMinDiffCellTemp 80;
BA_ "InvalidValue" SG_ 585 ALIVE_BMS_CoolntInletOutletTmp "Fh";
BA_ "GenSigStartValue" SG_ 585 BMS_CoolantInletTemp 80;
BA_ "GenSigStartValue" SG_ 585 BMS_CoolantOutletTemp 80;
BA_ "GenSigStartValue" SG_ 585 BMS_BDUTemp1 80;
BA_ "GenSigStartValue" SG_ 585 BMS_BDUTemp2 80;
BA_ "InvalidValue" SG_ 592 ALIVE_BMS_CVC_THMReq "Fh";
BA_ "GenSigStartValue" SG_ 592 BMS_InletTemp_Req 40;
BA_ "InvalidValue" SG_ 816 ALIVE_BMS_HistData "Fh";
BA_ "InvalidValue" SG_ 818 ALIVE_BMS_PackInfo "Fh";
BA_ "InvalidValue" SG_ 885 ALIVE_BMS_Relay "Fh";
BA_ "InvalidValue" SG_ 885 BMS_MainPosRelay_STS "7h";
BA_ "InvalidValue" SG_ 885 BMS_PreChgRelay_STS "7h";
BA_ "InvalidValue" SG_ 885 BMS_TotalNegRelay_STS "7h";
BA_ "InvalidValue" SG_ 1110 ALIVE_BMS_ERROR "Fh";
BA_ "GenSigTimeoutTime_ALL" SG_ 1110 BMS_faultnumber 5000;
BA_ "InvalidValue" SG_ 1171 ALIVE_BMS_WarnMsg "Fh";
BA_ "InvalidValue" SG_ 1171 BMS_Warning_DeltaTemperature "FFh";
BA_ "InvalidValue" SG_ 1171 BMS_Warning_BDUTemperatureSts "FFh";
BA_ "GenSigStartValue" SG_ 1952 BMS_CellT1 65;
BA_ "GenSigStartValue" SG_ 1952 BMS_CellT2 65;
BA_ "GenSigStartValue" SG_ 1952 BMS_CellT3 65;
BA_ "GenSigStartValue" SG_ 1952 BMS_CellT4 65;
BA_ "GenSigStartValue" SG_ 1952 BMS_CellT5 65;
BA_ "GenSigStartValue" SG_ 1952 BMS_CellT6 65;
BA_ "GenSigStartValue" SG_ 1952 BMS_CellT7 65;
BA_ "GenSigStartValue" SG_ 1952 BMS_CellT8 65;
BA_ "GenSigStartValue" SG_ 1952 BMS_CellT9 65;
BA_ "GenSigStartValue" SG_ 1952 BMS_CellT10 65;
BA_ "GenSigStartValue" SG_ 1952 BMS_CellT11 65;
BA_ "GenSigStartValue" SG_ 1952 BMS_CellT12 65;
BA_ "GenSigStartValue" SG_ 1952 BMS_CellT13 65;
BA_ "GenSigStartValue" SG_ 1952 BMS_CellT14 65;
BA_ "GenSigStartValue" SG_ 1952 BMS_CellT15 65;
BA_ "GenSigStartValue" SG_ 1952 BMS_CellT16 65;
BA_ "GenSigStartValue" SG_ 1952 BMS_CellT17 65;
BA_ "GenSigStartValue" SG_ 1952 BMS_CellT18 65;
BA_ "GenSigStartValue" SG_ 1952 BMS_CellT19 65;
BA_ "GenSigStartValue" SG_ 1952 BMS_CellT20 65;
BA_ "GenSigStartValue" SG_ 1952 BMS_CellT21 65;
BA_ "GenSigStartValue" SG_ 1952 BMS_CellT22 65;
BA_ "GenSigStartValue" SG_ 1952 BMS_CellT23 65;
BA_ "GenSigStartValue" SG_ 1952 BMS_CellT24 65;
BA_ "GenSigStartValue" SG_ 1952 BMS_CellT25 65;
BA_ "GenSigStartValue" SG_ 1952 BMS_CellT26 65;
BA_ "GenSigStartValue" SG_ 1952 BMS_CellT27 65;
BA_ "GenSigStartValue" SG_ 1952 BMS_CellT28 65;
BA_ "GenSigStartValue" SG_ 1952 BMS_CellT29 65;
BA_ "GenSigStartValue" SG_ 1952 BMS_CellT30 65;
BA_ "GenSigStartValue" SG_ 1952 BMS_CellT31 65;
BA_ "GenSigStartValue" SG_ 1952 BMS_CellT32 65;
BA_ "GenSigStartValue" SG_ 1952 BMS_CellT33 65;
BA_ "GenSigStartValue" SG_ 1952 BMS_CellT34 65;
BA_ "GenSigStartValue" SG_ 1952 BMS_CellT35 65;
BA_ "GenSigStartValue" SG_ 1952 BMS_CellT36 65;
BA_ "GenSigStartValue" SG_ 1952 BMS_BalArea_Temperature1 50;
BA_ "GenSigStartValue" SG_ 1952 BMS_BalArea_Temperature2 50;
BA_ "GenSigStartValue" SG_ 1952 BMS_BalArea_Temperature3 50;
BA_ "GenSigStartValue" SG_ 1952 BMS_BalArea_Temperature4 50;
BA_ "GenSigStartValue" SG_ 1952 BMS_BalArea_Temperature5 50;
BA_ "GenSigStartValue" SG_ 1952 BMS_BalArea_Temperature6 50;
BA_ "GenSigStartValue" SG_ 1952 BMS_BalArea_Temperature7 50;
BA_ "GenSigStartValue" SG_ 1952 BMS_BalArea_Temperature8 50;
BA_ "GenSigStartValue" SG_ 1952 BMS_BPS_pressureValue 50;
BA_ "GenSigStartValue" SG_ 1952 BMS_CVS_Temperature 50;
BA_ "GenSigSendType" SG_ 1939 BMS_XCPTxData 1;
BA_ "InvalidValue" SG_ 169 ALIVE_BCMFL_Temperature "Fh";
BA_ "SystemSignalLongSymbol" SG_ 169 BCMFL_Refrigerant_Temp_Sensor_St "BCMFL_Refrigerant_Temp_Sensor_Sts";
BA_ "InvalidValue" SG_ 170 ALIVE_CVC_Sts1 "Fh";
BA_ "InvalidValue" SG_ 171 ALIVE_CVC_FMCU_Ctrl "Fh";
BA_ "GenSigStartValue" SG_ 171 CVC_FMCU_TargetTqReq 4000;
BA_ "GenSigStartValue" SG_ 171 CVC_FMCU_TargetSpeedReq 20000;
BA_ "InvalidValue" SG_ 171 CVC_FMCU_StsModeReq "Fh";
BA_ "InvalidValue" SG_ 172 ALIVE_CVC_RMCU_Ctrl "Fh";
BA_ "GenSigStartValue" SG_ 172 CVC_RMCU_TargetTqReq 4000;
BA_ "GenSigStartValue" SG_ 172 CVC_RMCU_TargetSpeedReq 20000;
BA_ "InvalidValue" SG_ 217 ALIVE_CVC_HV_DrvSys_status "Fh";
BA_ "InvalidValue" SG_ 217 CVC_HVsystem_status "7h";
BA_ "GenSigStartValue" SG_ 217 CVC_ACT_DriveMode_Valid 1;
BA_ "InvalidValue" SG_ 217 CVC_HV_DRVsystem_status "7h";
BA_ "InvalidValue" SG_ 266 ALIVE_BCM_VOLTAGE "Fh";
BA_ "GenSigStartValue" SG_ 266 UBatt 9205;
BA_ "GenSigStartValue" SG_ 266 LV_Batt_Temp_Reserved 40;
BA_ "GenSigStartValue" SG_ 266 LV_Batt_Current_Reserved 49152;
BA_ "InvalidValue" SG_ 274 ALIVE_CVC_CLAMP_STAT "Fh";
BA_ "InvalidValue" SG_ 306 ALIVE_WCBS_ESC_Status "Fh";
BA_ "InvalidValue" SG_ 306 ESC_SlopeGrade "FFh";
BA_ "InvalidValue" SG_ 344 ALIVE_CVC_EngineControl "Fh";
BA_ "InvalidValue" SG_ 344 CVC_REX_Mode "3h";
BA_ "InvalidValue" SG_ 344 CVC_PCU_StopReq "3h";
BA_ "InvalidValue" SG_ 344 CVC_PCU_StartReq "3h";
BA_ "InvalidValue" SG_ 344 CVC_PCU_ActvDischg_Req "3h";
BA_ "InvalidValue" SG_ 344 CVC_PCU_GenTargetPower "FFFh";
BA_ "InvalidValue" SG_ 344 CVC_PCU_GenTargetVolt "3FFFh";
BA_ "InvalidValue" SG_ 344 CVC_PCU_GenTargetCurr "FFFFh";
BA_ "InvalidValue" SG_ 344 CVC_PCU_CurveSelection "0h";
BA_ "InvalidValue" SG_ 354 ALIVE_CVC_Ctrl "Fh";
BA_ "InvalidValue" SG_ 358 ALIVE_CVC_Status "Fh";
BA_ "GenSigStartValue" SG_ 358 CVC_CruiseSetSpd 30;
BA_ "InvalidValue" SG_ 358 CVC_CruiseSetSpd "FFh";
BA_ "GenSigStartValue" SG_ 358 CVC_REX_StartTimer 600;
BA_ "InvalidValue" SG_ 358 CVC_REX_StartTimer "3FFh";
BA_ "InvalidValue" SG_ 524 ALIVE_CVC_ODO "Fh";
BA_ "GenSigTimeoutTime_ALL" SG_ 525 CRC_WCBS_STATUS 200;
BA_ "GenSigTimeoutTime_ALL" SG_ 525 ALIVE_WCBS_STATUS 200;
BA_ "InvalidValue" SG_ 525 ALIVE_WCBS_STATUS "Fh";
BA_ "GenSigTimeoutTime_ALL" SG_ 525 ABSFailed 200;
BA_ "GenSigTimeoutTime_ALL" SG_ 525 ABSActive 200;
BA_ "GenSigTimeoutTime_ALL" SG_ 525 WCBS_VehicleSpeed 200;
BA_ "GenSigTimeoutTime_ALL" SG_ 525 ESC_VehicleStandstill 200;
BA_ "GenSigTimeoutTime_ALL" SG_ 525 WCBS_VehicleSpeedValid 200;
BA_ "GenSigTimeoutTime_ALL" SG_ 525 ESC_VehicleHoldStat 200;
BA_ "InvalidValue" SG_ 525 WCBS_Veh_DriveCondition "7h";
BA_ "InvalidValue" SG_ 535 ALIVE_CVC_BMS_Information "Fh";
BA_ "InvalidValue" SG_ 563 ALIVE_CVC_FMCU_Limit "Fh";
BA_ "InvalidValue" SG_ 563 CVC_RCU_EngTargetSpdReq "7Fh";
BA_ "InvalidValue" SG_ 565 ALIVE_CVC_RMCU_Limit "Fh";
BA_ "InvalidValue" SG_ 564 ALIVE_CVC_PDU_Ctrl "Fh";
BA_ "GenSigStartValue" SG_ 564 CVC_vDCDCRequest 224;
BA_ "GenSigTimeoutTime_ALL" SG_ 746 InteriorTemperature 500;
BA_ "GenSigStartValue" SG_ 746 CVC_DCChgPosTemp 40;
BA_ "GenSigStartValue" SG_ 746 CVC_DCChgNegTemp 40;
BA_ "GenSigStartValue" SG_ 746 CVC_ACChgLTerminalTemp 40;
BA_ "GenSigStartValue" SG_ 746 CVC_ACChgNTerminalTemp_Reserve 40;
BA_ "GenSigStartValue" SG_ 760 DISP_DATE_DAY 1;
BA_ "GenSigStartValue" SG_ 760 DISP_DATE_MON 1;
BA_ "GenSigStartValue" SG_ 760 DISP_DATE_YR 1;
BA_ "InvalidValue" SG_ 852 CVC_MotorWaterPump_PWM_Req "FFh";
BA_ "InvalidValue" SG_ 852 CVC_BatteryWaterPump_PWM_Req "FFh";
BA_ "InvalidValue" SG_ 852 CVC_DriveCoolWaterFlowRate "FFh";
BA_ "InvalidValue" SG_ 852 CVC_EACAllowedPower "FFh";
BA_ "InvalidValue" SG_ 852 CVC_ElectricFan_PWM_Req "FFh";
BA_ "InvalidValue" SG_ 858 ALIVE_CVC_CP_Req "Fh";
BA_ "InvalidValue" SG_ 858 CVC_LockCP_Req "3h";
BA_ "InvalidValue" SG_ 862 ALIVE_CVC_Vehicle_info "Fh";
BA_ "InvalidValue" SG_ 862 CVC_VehLock_STS "3h";
BA_ "InvalidValue" SG_ 862 CVC_VehSpd_ScreenDisplay "FFh";
BA_ "InvalidValue" SG_ 862 CVC_VehChgAllow "3h";
BA_ "InvalidValue" SG_ 862 CVC_VehDischgAllow "3h";
BA_ "InvalidValue" SG_ 862 Re_InitCharging_Req "3h";
BA_ "InvalidValue" SG_ 862 CVC_GunUnlock_Req "3h";
BA_ "GenSigStartValue" SG_ 862 CVC_ACInputChgCurLim 6;
BA_ "GenSigStartValue" SG_ 884 PTC_PCBT 48;
BA_ "GenSigStartValue" SG_ 889 PTC_InpT 48;
BA_ "GenSigStartValue" SG_ 889 PTC_OutpT 48;
BA_ "GenSigStartValue" SG_ 889 PTC_CrtT 48;
BA_ "GenSigTimeoutTime_ALL" SG_ 1873 CVC_DebugDiag2 500;
BA_ "GenSigTimeoutTime_ALL" SG_ 1873 CVC_DebugDiag1 500;
BA_ "GenSigTimeoutTime_ALL" SG_ 1873 CVC_DebugDiag5 500;
BA_ "GenSigTimeoutTime_ALL" SG_ 1873 CVC_DebugDiag4 500;
BA_ "GenSigTimeoutTime_ALL" SG_ 1873 CVC_DebugDiag3 500;
BA_ "GenSigTimeoutTime_ALL" SG_ 1873 CVC_DebugDiag8 500;
BA_ "GenSigTimeoutTime_ALL" SG_ 1873 CVC_DebugDiag7 500;
BA_ "GenSigTimeoutTime_ALL" SG_ 1873 CVC_DebugDiag6 500;
BA_ "GenSigTimeoutTime_ALL" SG_ 1873 CVC_DebugDiag10 500;
BA_ "GenSigTimeoutTime_ALL" SG_ 1873 CVC_DebugDiag9 500;
BA_ "GenSigTimeoutTime_ALL" SG_ 1873 CVC_DebugDiag13 500;
BA_ "GenSigTimeoutTime_ALL" SG_ 1873 CVC_DebugDiag12 500;
BA_ "GenSigTimeoutTime_ALL" SG_ 1873 CVC_DebugDiag11 500;
BA_ "GenSigTimeoutTime_ALL" SG_ 1873 CVC_DebugDiag16 500;
BA_ "GenSigTimeoutTime_ALL" SG_ 1873 CVC_DebugDiag15 500;
BA_ "GenSigTimeoutTime_ALL" SG_ 1873 CVC_DebugDiag14 500;
BA_ "GenSigTimeoutTime_ALL" SG_ 1873 CVC_DebugDiag18 500;
BA_ "GenSigTimeoutTime_ALL" SG_ 1873 CVC_DebugDiag17 500;
BA_ "GenSigTimeoutTime_ALL" SG_ 1873 CVC_DebugDiag20 500;
BA_ "GenSigTimeoutTime_ALL" SG_ 1873 CVC_DebugDiag19 500;
BA_ "GenSigTimeoutTime_ALL" SG_ 1874 CVC_Debug1 500;
BA_ "GenSigTimeoutTime_ALL" SG_ 1874 CVC_Debug2 500;
BA_ "GenSigTimeoutTime_ALL" SG_ 1874 CVC_Debug3 500;
BA_ "GenSigTimeoutTime_ALL" SG_ 1874 CVC_Debug4 500;
BA_ "GenSigSendType" SG_ 1878 BMS_XCPRxData 1;
BA_ "GenSigSendType" SG_ 1968 Sync_TripCnt 2;
BA_ "GenSigSendType" SG_ 1968 Sync_ResetCnt 2;
BA_ "GenSigSendType" SG_ 1968 Sync_MAC 2;
BA_ "InvalidValue" SG_ 537 ALIVE_EVCC_OBC_Ctrl "Fh";
BA_ "InvalidValue" SG_ 537 EVCC_OBC_StsModeReq "Fh";
BA_ "InvalidValue" SG_ 537 EVCC_StsChgCC "Fh";
BA_ "GenSigStartValue" SG_ 593 EVCC_DCChgPosTemp 40;
BA_ "InvalidValue" SG_ 593 EVCC_DCChgPosTemp "FFh";
BA_ "GenSigStartValue" SG_ 593 EVCC_DCChgNegTemp 40;
BA_ "InvalidValue" SG_ 593 EVCC_DCChgNegTemp "FFh";
BA_ "GenSigStartValue" SG_ 593 EVCC_ACChgL1TerminalTemp 40;
BA_ "InvalidValue" SG_ 593 EVCC_ACChgL1TerminalTemp "FFh";
BA_ "GenSigStartValue" SG_ 593 EVCC_ACChgNTerminalTemp_Reserve 40;
BA_ "InvalidValue" SG_ 593 EVCC_ACChgNTerminalTemp_Reserve "FFh";
BA_ "InvalidValue" SG_ 696 ALIVE_EVCC_VehDischg_Sts "Fh";
BA_ "InvalidValue" SG_ 696 EVCC_VehDischg_Sts "5h";
BA_ "InvalidValue" SG_ 696 EVCC_V2L_adapter_Sts "3h";
BA_ "InvalidValue" SG_ 696 EVCC_ConnectorType_Sts "2h";
BA_ "InvalidValue" SG_ 843 ALIVE_EVCC_EVSE_Info_1 "Fh";
BA_ "InvalidValue" SG_ 845 ALIVE_EVCC_Req "Fh";
BA_ "InvalidValue" SG_ 845 EVCC_STAT_BrakeSts "3h";
BA_ "InvalidValue" SG_ 845 EVCC_Req_InsulationMon "3h";
BA_ "InvalidValue" SG_ 845 EVCC_PnC_Contract_STS "3h";
BA_ "InvalidValue" SG_ 845 EVCC_FcContactor_Req "3h";
BA_ "InvalidValue" SG_ 847 ALIVE_EVCC_EVSE_Info_2 "Fh";
BA_ "GenSigStartValue" SG_ 850 EVCC_ACTemperature 60;
BA_ "GenSigStartValue" SG_ 850 EVCC_Motor_TempSensor 60;
BA_ "GenSigStartValue" SG_ 850 EVCC_SOV2_ControlStatus 1;
BA_ "GenSigStartValue" SG_ 850 EVCC_SOV1_ControlStatus 1;
BA_ "GenSigStartValue" SG_ 850 EVCC_MotorWaterPump_Status 1;
BA_ "GenSigStartValue" SG_ 850 EVCC_BatteryWaterPump_Status 1;
BA_ "GenSigStartValue" SG_ 850 EVCC_ACPressure 546;
BA_ "InvalidValue" SG_ 850 EVCC_ACPressure "3FFFh";
BA_ "GenSigStartValue" SG_ 850 EVCC_PTC_OnOff_Status 1;
BA_ "GenSigStartValue" SG_ 851 EVCC_EAC_OnOff_Status 1;
BA_ "GenSigStartValue" SG_ 851 EVCC_DualPressureSwitch_Status 1;
BA_ "GenSigStartValue" SG_ 851 EVCC_MainRelay_OnOff_Status 1;
BA_ "GenSigStartValue" SG_ 851 EVCC_ElectricFan_OnOff_Sts 1;
BA_ "GenSigStartValue" SG_ 851 EVCC_CL15_Status 1;
BA_ "GenSigStartValue" SG_ 851 EVCC_PGearPressSignal1_Status 1;
BA_ "GenSigStartValue" SG_ 851 EVCC_PGearStsLight_OnOff_Sts 1;
BA_ "GenSigStartValue" SG_ 851 EVCC_PGearPressSignal2_Status 30;
BA_ "GenSigStartValue" SG_ 851 EVCC_ExpValve_OnOff_Status 1;
BA_ "InvalidValue" SG_ 859 ALIVE_EVCC_ACCharging_Req "Fh";
BA_ "InvalidValue" SG_ 892 ALIVE_EVCC_Charging_Sts "Fh";
BA_ "InvalidValue" SG_ 892 EVCC_ChgGun_Sts "7h";
BA_ "InvalidValue" SG_ 892 EVCC_ChgFlap_Sts "3h";
BA_ "InvalidValue" SG_ 892 EVCC_ChgType "7h";
BA_ "InvalidValue" SG_ 892 EVCC_VehChg_Sts "7h";
BA_ "InvalidValue" SG_ 892 EVCC_ChgAuthen_Sts "7h";
BA_ "InvalidValue" SG_ 892 EVCC_PaymentType "7h";
BA_ "InvalidValue" SG_ 892 EVCC_VehChgCompError_Sts "7h";
BA_ "InvalidValue" SG_ 892 EVCC_S3Button_Sts "3h";
VAL_ 133 ACU_Crash_Sts 0 "No_Event" 1 "Crash_Detected" ;
VAL_ 133 ACU_Airbag_Deployment_Status 0 "No_Airbag_Deployment" 1 "Airbag_Deployment" ;
VAL_ 133 ACU_Crash_Intensity 0 "No_Crash" 1 "Crash_Intensity_1" 2 "Crash_Intensity_2" 3 "Crash_Intensity_3" ;
VAL_ 133 ACU_Front_Crash 0 "No_Event" 1 "Front_Crash_Detected" ;
VAL_ 133 ACU_DriverSide_Crash 0 "No_Event" 1 "Driverside_Crash_Detected" ;
VAL_ 133 ACU_PassSide_Crash 0 "No_Event" 1 "PasSide_Crash_Detected" ;
VAL_ 133 ACU_Rear_Crash 0 "No_Event" 1 "Rear_Crash_Detected" ;
VAL_ 133 ACU_Rollover_Crash 0 "No_Event" 1 "Rollover_Crash_Detected" ;
VAL_ 372 BMS_StartOfMeasument_STS 0 "Not start" 1 "Started" ;
VAL_ 372 BMS_CVC_Insulation_Mon_Sts 0 "ON" 1 "OFF" ;
VAL_ 533 BMS_BatBalance_ERR 0 "Error" 1 "normal" ;
VAL_ 533 BMS_Balance_STS 0 "Inactive" 1 "active" ;
VAL_ 533 BMS_IGN_Sts 0 "OFF" 1 "ON" ;
VAL_ 533 BMS_HWCrash_Sts 0 "No Crash" 1 "Crash" ;
VAL_ 533 BMS_HVIL_STS 0 "Closed" 1 "Open & short to battery" 2 "short to ground" 3 "Signal invalid" ;
VAL_ 533 BMS_HVOnOff_STS 0 "HV Off" 1 "Precharge" 2 "HV On" 3 "Fail to HV on" ;
VAL_ 533 BMS_ERR_LEV 0 "No error" 1 "Warning" 2 "Limp Home" 3 "Power down without FTTI" 4 "Delay power down with FTTI" 5 "Emergency off condition" 6 "Fault, needs to shutdown and wakeup" 7 "Battery locked - reserved" ;
VAL_ 533 BMS_Sys_STS 0 "Initialization of power on, self-checking" 1 "Self-check passes, can be high-voltage" 2 "Successful High Voltage Power Up" 3 "Successful Power Down of HV" 4 "Power Down process" 5 "Successful Power Down" 6 "BCU Sleep mode" 7 "Failure, unable to operate" 8 "Invalid" ;
VAL_ 533 BMS_ISU_Status 0 "Normal (> 250 kOhms)" 1 "Level1 (<250 kOhms ~ >100 kOhms)" 3 "Level3 (<100 kOhms)" ;
VAL_ 533 BMS_HV_Sts 0 "HV Off" 1 "Pre Charge" 2 "HV On" 3 "Super_Fast_Charge" 4 "AC Charge" 5 "Undefined" 6 "Undefined" 7 "Undefined" 8 "Undefined" 9 "Undefined" ;
VAL_ 581 BMS_ProbeNumMaxCellTemp 0 "Invalid" 62 "Error" 63 "Invalid" ;
VAL_ 581 BMS_ProbeNumMinCellTemp 0 "Invalid" 62 "Error" 63 "Invalid" ;
VAL_ 585 BMS_CoolantInletTempSts 0 "Normal" 1 "Short circuit Battery" 2 "Short circuit GND" 3 "Invalid" ;
VAL_ 585 BMS_CoolantOutletTempSts 0 "Normal" 1 "Short circuit Battery" 2 "Short circuit GND" 3 "Invalid" ;
VAL_ 592 BMS_CVC_PTCOnOff_Req 0 "OFF" 1 "ON" ;
VAL_ 592 BMS_CVC_ValveOnOff_Req 0 "close" 1 "open" ;
VAL_ 592 BMS_PreHeatCoolReq 0 "Precondition OFF" 1 "Precondition Heating ON" 2 "Precondition Cooling ON" 3 "Invalid value" ;
VAL_ 816 BMS_ContactorAging 0 "Normal" 1 "Warning counter reach 90%" 2 "Fault counter reach 98%" ;
VAL_ 818 BMS_SupplierType 1 "VinFast inhouse" 2 "CATL" 3 "SDI" 4 "Gotion" 5 "Svolt" ;
VAL_ 885 BMS_PreChgRelay_ERR 0 "error" 1 "normal" ;
VAL_ 885 BMS_TotalNegRelay_ERR 0 "Error" 1 "normal" ;
VAL_ 885 BMS_MainPosRelay_ERR 0 "Error" 1 "normal" ;
VAL_ 885 BMS_MainPosRelay_STS 0 "reserved" 1 "open" 2 "closed" 3 "stuck closed" 4 "stuck open" ;
VAL_ 885 BMS_PreChgRelay_STS 0 "reserved" 1 "open" 2 "closed" 3 "stuck closed" 4 "stuck open" ;
VAL_ 885 BMS_TotalNegRelay_STS 0 "reserved" 1 "open" 2 "closed" 3 "stuck closed" 4 "stuck open" ;
VAL_ 1110 BMS_CellLowVol_ERR 0 "Normal" 1 "Warning" 2 "Error" 3 "Safety Error" ;
VAL_ 1110 BMS_HVIL_Err 0 "Normal" 1 "Level1" 2 "Level2" 3 "Level3" ;
VAL_ 1110 BMS_PackInsu_ERR 0 "Lv0-No Err" 1 "Lv1 - Short to ground" 2 "Lv2-Short to vbat and open line" ;
VAL_ 1110 BMS_CellVoltDiff_ERR 0 "Normal" 1 "Warning" 2 "Error" 3 "Safety Error" ;
VAL_ 1110 BMS_ProbeTempDiff_ERR 0 "Normal" 1 "Warning" 2 "Error" 3 "Safety Error" ;
VAL_ 1110 BMS_PackHighVol_ERR 0 "Normal" 1 "Warning" 2 "Error" 3 "Safety Error" ;
VAL_ 1110 BMS_PackLowVol_ERR 0 "Normal" 1 "Warning" 2 "Error" 3 "Safety Error" ;
VAL_ 1110 BMS_CellHighVol_ERR 0 "Normal" 1 "Warning" 2 "Error" 3 "Safety Error" ;
VAL_ 1110 BMS_ProbeHighTemp_ERR 0 "Normal" 1 "Warning" 2 "Error" 3 "Safety Error" ;
VAL_ 1110 BMS_FuseStatus_ERR 0 "Normal" 1 "Fuse blow" ;
VAL_ 1110 BMS_PackOverCurr_ERR 0 "Normal" 1 "Warning" 2 "Error" 3 "Safety Error" ;
VAL_ 1110 BMS_ProbeLowTemp_ERR 0 "Normal" 1 "Warning" 2 "Error" 3 "Safety Error" ;
VAL_ 1110 EHPMon_bErrVehIslnRNvMon 0 "No error" 1 "Error" ;
VAL_ 1110 EHPMon_bErrPackIslnRNvMon 0 "No error" 1 "Error" ;
VAL_ 1171 BMS_PackTempSts 0 "No warning" 1 "Over Temperature Warning" 2 "Under Temperature Warning" ;
VAL_ 1171 BMS_ThermalRunaway 0 "No Warning" 1 "Warning" ;
VAL_ 1171 BMS_BatteryReplacement 0 "No Warning" 1 "Warning" ;
VAL_ 1171 BMS_Warning_PowerDegrade 0 "Normal" 1 "Pack Power Degrade" ;
VAL_ 1171 BMS_Warning_DeltaSoC 0 "Normal" 1 "Delta SOC high" ;
VAL_ 1171 BMS_Warning_HVILSts 0 "Normal" 1 "HVIL error detected" ;
VAL_ 1171 BMS_Warning_Isolation 0 "Normal" 1 "Isolation reached level 3" ;
VAL_ 1171 BMS_Warning_CoolantLeakage 0 "Normal" 1 "Coolant leakage detected" ;
VAL_ 1171 BMS_MalfunctionSts 0 "No Warning" 1 "Warning" ;
VAL_ 1171 BMS_LowBattery 0 "No warning" 1 "Low level" 2 "Extremely low level" ;
VAL_ 1171 BMS_Warning_DeltaTemperature 0 "Normal" 1 "Level 1 warning" 2 "Level 2 extreme" ;
VAL_ 1171 BMS_Warning_BDUTemperatureSts 0 "Normal" 1 "BDU temp warning" 2 "BDU hot" 3 "BDU extreme hot" ;
VAL_ 1171 BMS_Warning_Contactor_Aging 0 "No Warning" 1 "Warning" ;
VAL_ 169 BCMFL_AmbientTempSts 0 "Normal" 1 "Short circuit Battery" 2 "Short circuit GND" 3 "Invalid" ;
VAL_ 169 BCMFL_CoolantTemp_EDS_In_Sts 0 "Normal" 1 "Short circuit Battery" 2 "Short circuit GND" 3 "Invalid" ;
VAL_ 169 BCMFL_CoolantTemp_EDS_Out_Sts 0 "Normal" 1 "Short circuit Battery" 2 "Short circuit GND" 3 "Invalid" ;
VAL_ 169 BCMFL_CoolantTemp_LTR_Out_Sts 0 "Normal" 1 "Short circuit Battery" 2 "Short circuit GND" 3 "Invalid" ;
VAL_ 169 BCMFL_ACLowSideTemperatureSts 0 "Normal" 1 "Short circuit Battery" 2 "Short circuit GND" 3 "Invalid" ;
VAL_ 169 BCMFL_ACLowSidePressureSts 0 "Normal" 1 "Short circuit Battery" 2 "Short circuit GND" 3 "Invalid" ;
VAL_ 169 BCMFL_ACHighSideTemperatureSts 0 "Normal" 1 "Short circuit Battery" 2 "Short circuit GND" 3 "Invalid" ;
VAL_ 169 BCMFL_ACHighSidePressureSts 0 "Normal" 1 "Short circuit Battery" 2 "Short circuit GND" 3 "Invalid" ;
VAL_ 169 BCMFL_CoolantTemp_HtrCore_In_Sts 0 "Normal" 1 "Short circuit Battery" 2 "Short circuit GND" 3 "Invalid" ;
VAL_ 169 BCMFL_Refrigerant_Temp_Sensor_St 0 "Normal" 1 "Short circuit Battery" 2 "Short circuit GND" 3 "Invalid" ;
VAL_ 169 BCMFL_PT_Sensor1_Pressure_Sts 0 "Normal" 1 "Short circuit Battery" 2 "Short circuit GND" 3 "Invalid" ;
VAL_ 169 BCMFL_PT_Sensor2_Pressure_Sts 0 "Normal" 1 "Short circuit Battery" 2 "Short circuit GND" 3 "Invalid" ;
VAL_ 170 CVC_BMS_HVOnOff_REQ 0 "forbid" 1 "allow" ;
VAL_ 171 CVC_FMCU_StsModeReq 0 "Init" 1 "LvStandby（12V）" 5 "Standby" 6 "Torq" 7 "Speed" 9 "ActiveDischarge" 10 "Fault" 11 "PowerOff" 12 "AfterRun" ;
VAL_ 171 CVC_FMCU_Oil_Pump_Relay_Sts 0 "OFF" 1 "ON" ;
VAL_ 171 CVC_FMCU_TargetTqReqV 0 "Vaild" 1 "Invalid" ;
VAL_ 171 CVC_FMCU_TargetSpeedReqV 0 "Vaild" 1 "Invalid" ;
VAL_ 171 CVC_FMCU_VehicleDirect 0 "Forward" 1 "Backward" ;
VAL_ 171 CVC_MCU_AtvDischg_Req 0 "No request" 1 "Request" ;
VAL_ 171 CVC_MCU_CtrlModeReq 0 "Inactive" 1 "TqCtrl" 2 "Speed" 3 "Reserved" ;
VAL_ 172 CVC_RMCU_StsModeReq 0 "Init" 1 "LvStandby（12V）" 5 "Standby" 6 "Torq" 7 "Speed" 9 "ActiveDischarge" 10 "Fault" 11 "PowerOff" 12 "AfterRun" ;
VAL_ 172 CVC_RMCU_Oil_Pump_Relay_Sts 0 "OFF" 1 "ON" ;
VAL_ 172 CVC_RMCU_TargetTqReqV 0 "Vaild" 1 "Invalid" ;
VAL_ 172 CVC_RMCU_TargetSpeedReqV 0 "Vaild" 1 "Invalid" ;
VAL_ 172 CVC_RMCU_VehicleDirect 0 "Forward" 1 "Backward" ;
VAL_ 172 CVC_RMCU_AtvDischg_Req 0 "No request" 1 "Request" ;
VAL_ 172 CVC_RMCU_CtrlModeReq 0 "Inactive" 1 "TqCtrl" 2 "Speed" 3 "Reserved" ;
VAL_ 217 CVC_HVsystem_status 0 "Not ready" 1 "HV On" 2 "ReadyToDrive" 3 "Charging" 4 "Error" 5 "Reserved" 6 "Reserved" 7 "Reserved" ;
VAL_ 217 CVC_ACPD_Percent_Valid 0 "Valid" 1 "Invalid" ;
VAL_ 217 CVC_ACTGear 0 "P" 1 "R" 2 "N" 3 "D" 4 "Reserved" 5 "Reserved" 6 "Reserved" 7 "Fault" ;
VAL_ 217 CVC_ACTGearValid 0 "Valid" 1 "Invalid" ;
VAL_ 217 CVC_ACT_DriveMode 0 "Normal mode" 1 "ECO mode" 2 "Sport mode" 3 "Reserved" 4 "Reserved" 5 "Reserved" 6 "Reserved" 7 "Invalid" ;
VAL_ 217 CVC_ACT_DriveMode_Valid 0 "Valid" 1 "Invalid" ;
VAL_ 217 CVC_HV_DRVsystem_status 0 "Not available" 1 "Normal" 2 "Degration" 3 "Limphome" 4 "Error" 5 "Reserved" 6 "Reserved" 7 "Reserved" ;
VAL_ 217 CVC_Recu_BrakeLight_ON_Req 0 "Brake light OFF" 1 "Brake light ON" 2 "Reserved" 3 "Signal not available" ;
VAL_ 217 CVC_AccPedal_Valid 0 "Valid" 1 "Invalid" ;
VAL_ 217 CVC_StsAccPedalFault 0 "Valid" 1 "Invalid" ;
VAL_ 217 CVC_StsSysFault 0 "Init" 1 "Normal" 3 "Warning" 5 "Derating" 7 "Limphome" 9 "ZeroTorque" 11 "Powerdown" 13 "EmPowerdown" 14 "Invalid" ;
VAL_ 266 LV_BatteryType 0 "Lead Acid Battery" 1 "Lithium Battery" 2 "Reversed" 3 "Invalid" ;
VAL_ 274 CVC_STAT_BLS 0 "BLS not pressed" 1 "BLS pressed" 2 "Reserved" 3 "Signal invalid" ;
VAL_ 274 Vehicle_Operation_State 0 "OFF(Comfort Enable)" 1 "ACC (Park)" 2 "ON (Driver Present)" 3 "Engine start (eMotor running)" 4 "SW Update OTA" 5 "Reserved" 6 "Reserved" 7 "Signal Invalid" ;
VAL_ 280 CVC_VehicleSpeedValid 0 "Invalid" 1 "Vaild" ;
VAL_ 280 CVC_HV_State 0 "HIGH_VOLT_DOWN" 1 "HIGH_VOLT_UP" 2 "HIGH_VOLT_DOWNING" 3 "HIGH_VOLT_UPING" ;
VAL_ 306 ESC_HSA_Control_Status 0 "Inactive" 1 "Active" ;
VAL_ 306 ESC_HSA_Status_Fault 0 "HSA Normale" 1 "HSA Defective" ;
VAL_ 306 ESC_TcsEnableSts 0 "Enabled" 1 "Disabled" ;
VAL_ 306 ESC_EscCtrlActv 0 "Inactive" 1 "Active" ;
VAL_ 306 ESC_TcsCtrlActv 0 "Inactive" 1 "Active" ;
VAL_ 306 ESC_EscFlgFlt 0 "No failure" 1 "Failure" ;
VAL_ 306 ESC_TcsFlgFlt 0 "No failure" 1 "Failure" ;
VAL_ 306 ESC_EscEnableSts 0 "Enabled" 1 "Disabled" ;
VAL_ 306 ESC_HBAFlgFlt 0 "No failure" 1 "Failure" ;
VAL_ 306 ESC_HbaCtrlActv 0 "Inactive" 1 "Active" ;
VAL_ 306 ESC_DTC_Active 0 "Inactive" 1 "Active" ;
VAL_ 306 ESC_BTCSCtrlActv 0 "Inactive" 1 "Active" ;
VAL_ 306 ESC_EngineCtrlActv 0 "Inactive" 1 "Active" ;
VAL_ 344 CVC_REX_Mode 0 "BEV" 1 "REEV" 2 "Reserved" 3 "Invalid" ;
VAL_ 344 CVC_PCU_StopReq 0 "No request" 1 "Request general shutdown" 2 "Request emergency shutdown" 3 "Invalid" ;
VAL_ 344 CVC_PCU_StartReq 0 "No request" 1 "Request" 2 "Reserved" 3 "Invalid" ;
VAL_ 344 CVC_PCU_ActvDischg_Req 0 "No request" 1 "Request" 2 "Reserved" 3 "Invalid" ;
VAL_ 344 CVC_PCU_CurveSelection 0 "Invalid" 1 "Profile 1" 2 "Profile 2" 3 "Profile 3" 4 "Reserved 4" ;
VAL_ 354 CVC_ModeGearSts 0 "Invalid" 1 "P" 2 "R" 3 "N" 4 "D" ;
VAL_ 354 CVC_P_Sts 0 "NO Action" 1 "Press" ;
VAL_ 354 CVC_IMMO_Sts 0 "Init" 1 "Pass" 2 "Fail" ;
VAL_ 354 CVC_RegencyLevInd 0 "Default" 1 "OFF" 2 "Regency Leve1" 3 "Regency Leve2" ;
VAL_ 354 CVC_LimpHomeSts 0 "not in Limphome Mode" 1 "in Limphome Mode" ;
VAL_ 358 CVC_DriveModeSts 0 "Invalid" 1 "Comfort Mode" 2 "Eco Mode" 3 "Sport Mode" ;
VAL_ 358 CVC_DriveReady 0 "Not Ready" 1 "Ready" ;
VAL_ 358 CVC_Fault 0 "No fault" 1 "FaultLevel 1" 2 "FaultLevel 2" 3 "Faultlevel3(Error)" ;
VAL_ 358 CVC_VecFltInd 0 "No fault" 1 "Fault" ;
VAL_ 358 CVC_Creep_Sts 0 "Invalid" 1 "Creep disable" 2 "Creep enable" 3 "Creep function fault" ;
VAL_ 358 CVC_CruiseCtrlSts 0 "OFF" 1 "Standby" 2 "Active" 3 "Override" 4 "Fault" 5 "Reserved" 6 "Reserved" ;
VAL_ 358 CVC_StsBrakePedalSwitch 0 "Reserved" 1 "Not pressed" 2 "Pressed" 3 "Invalid" ;
VAL_ 358 CVC_VehicleMode 0 "EV" 1 "REV" 2 "Fuel" ;
VAL_ 358 CVC_CruiseFaultIndication 0 "No Fault" 1 "Pre-Condition not met" 2 "Function fault" ;
VAL_ 358 CVC_FuelDetectionSwitchState 0 "No COM" 1 "Enable" 2 "Close" 3 "Invalid" ;
VAL_ 358 CVC_FuelDetectionState 0 "No COM" 1 "High Idle" 2 "Low Idle" 3 "Invalid" ;
VAL_ 358 CVC_ParkingChargeRequest 0 "No COM" 1 "Enable" 2 "Close" 3 "Invalid" ;
VAL_ 358 CVC_ParkingChargeModeSet 0 "NORequest" 1 "LOW" 2 "MIDDLE" 3 "HIGH" ;
VAL_ 358 LV_EM_Rampup_Req 0 "No Load Management" 1 "DCDC OFF_No_Rampup" 2 "DCDCRampupTimer_Active" ;
VAL_ 358 LV_PowerSupply_Status 0 "No Fault" 1 "Fault" ;
VAL_ 358 LV_EM_OTA_Req 0 "No OTA LM" 1 "OTA LV Rampup" 2 "OTA_LV_LM_TimerExpired" 3 "OTA_LV_LM_DCDCOFF" ;
VAL_ 358 CVC_STAT_AirDistributionModeLH 0 "OFF" 1 "Vent" 2 "Vent LH + Foot LH" 3 "Foot LH" 4 "Foot LH + Defrost" 5 "Defrost" 6 "Defrost + Face" 7 "Tri Level" ;
VAL_ 358 CVC_STAT_AirDistributionModeRH 0 "OFF" 1 "Vent" 2 "Vent RH + Foot RH" 3 "Foot RH" ;
VAL_ 358 CVC_STAT_DriverOnly 0 "OFF" 1 "ON" 2 "Reserved" 3 "Signal Invalid" ;
VAL_ 524 CVC_OdometerV 0 "Valid" 1 "Invalid" ;
VAL_ 525 ABSFailed 0 "No fault" 1 "Fault" ;
VAL_ 525 ABSActive 0 "Inactive" 1 "Active" ;
VAL_ 525 ESC_VehicleStandstill 0 "NO_VEHICLE_STANDSTILL" 1 "VEHICLE_STANDSTILL" ;
VAL_ 525 WCBS_VehicleSpeedValid 0 "Valid" 1 "Invalid" ;
VAL_ 525 ESC_VehicleHoldStat 0 "No vehicle hold" 1 "vehicle hold" 2 "reserved" 3 "reserved" ;
VAL_ 525 ABS_EBDFailed 0 "EBD Normal" 1 "EBD Failed" ;
VAL_ 525 ABS_HAZActive 0 "Emergency brake light off" 1 "Emergency brake light on" ;
VAL_ 525 ABS_LowBrakeFluid 0 "no failure" 1 "failure" ;
VAL_ 525 EBDActive 0 "Inactive" 1 "Active" ;
VAL_ 525 WCBS_Veh_DriveCondition 0 "Vehicle is stationary" 1 "Vehicle is moving forward" 2 "Vehicle is moving reverse" 3 "Vehicle is stationary rear axle rol" 4 "Vehicle is stationary front axle roll" 5 "Vehicle is stationary all axle roll" 6 "reserved" 7 "Signal invalid" ;
VAL_ 535 CVC_DCChargeRelayP 0 "Open" 1 "Close" ;
VAL_ 535 CVC_DCChargeRelayN 0 "Open" 1 "Close" ;
VAL_ 535 CVC_BMS_PTCOnOff_Sts 0 "off" 1 "on" ;
VAL_ 535 CVC_BMS_ValveOnOff_Sts 0 "close" 1 "open" ;
VAL_ 535 CVC_BMS_PumpFB 0 "OFF" 1 "ON" 2 "Fault" 3 "Reserve" ;
VAL_ 564 CVC_DCDC_StsModeReq 0 "Inactive" 1 "Buck" 2 "Active Discharge(Reserve)" ;
VAL_ 746 CVC_Fan_Sts 0 "Closed" 1 "Low Speed" 2 "High speed" ;
VAL_ 746 CVC_EdrivePump_Sts 0 "Not Work" 1 "Working" 2 "Fault" ;
VAL_ 746 CVC_BatPump_Sts 0 "Not Work" 1 "Working" 2 "Fault" ;
VAL_ 760 DISP_DATE_WDAY 1 "Monday" 2 "Tuesday" 3 "Wednesday" 4 "Thursday" 5 "Friday" 6 "Saturday" 7 "Sunday" 15 "Signal invalid" ;
VAL_ 760 ST_DISP_CTI_DATE 0 "data not valid" 1 "data valid" 3 "UTC" 5 "winter time" 6 "Manually set time" 7 "summer time" 15 "signal invalid" ;
VAL_ 852 CVC_SOV1_ControlReq 0 "Invalid" 1 "OFF" 2 "ON" ;
VAL_ 852 CVC_MotorWaterPump_OnOff_Req 0 "Invalid" 1 "OFF" 2 "ON" ;
VAL_ 852 CVC_MainRelay_OnOff_Req 0 "Invalid" 1 "OFF" 2 "ON" ;
VAL_ 852 CVC_ElectricFan_Enable 0 "Invalid" 1 "OFF" 2 "ON" ;
VAL_ 852 CVC_BatteryWaterPump_OnOff_Req 0 "Invalid" 1 "OFF" 2 "ON" ;
VAL_ 852 CVC_EAC_OnOff_Req 0 "Invalid" 1 "OFF" 2 "ON" ;
VAL_ 852 CVC_PGearStatusLight_OnOff_Req 0 "Invalid" 1 "OFF" 2 "ON" ;
VAL_ 852 CVC_PTC_OnOff_Req 0 "Invalid" 1 "OFF" 2 "ON" ;
VAL_ 852 CVC_ExpValve_OnOff_Req 0 "Invalid" 1 "OFF" 2 "ON" ;
VAL_ 852 CVC_SOV2_ControlReq 0 "Invalid" 1 "OFF" 2 "ON" ;
VAL_ 858 CVC_LockCP_Req 0 "No action" 1 "Lock" 2 "Unlock" 3 "Invalid" ;
VAL_ 862 CVC_VehLock_STS 0 "Locked" 1 "Unlocked" ;
VAL_ 862 CVC_VehChgAllow 0 "Forbid charging" 1 "Not allow, waiting" 2 "Allow charging" 3 "Invalid" ;
VAL_ 862 CVC_VehDischgAllow 0 "Forbid discharging" 1 "Shutdown" 2 "Allow discharging" 3 "Invalid" ;
VAL_ 862 Re_InitCharging_Req 0 "Forbid" 1 "Allow" 2 "Reserved" 3 "Invalid" ;
VAL_ 862 CVC_StopChg_Req 0 "No request" 1 "Request" ;
VAL_ 862 CVC_GunUnlock_Req 0 "No action" 1 "Lock" 2 "Unlock" 3 "Invalid" ;
VAL_ 884 PTC_CrtSts 0 "standby mode" 1 "Power working status" 2 "Fault Status" 3 "Gear working status" ;
VAL_ 884 PTC_HVIntlkFlt 0 "Normal" 1 "Fault" ;
VAL_ 884 PTC_ComLost_ECC 0 "Normal" 1 "Fault" ;
VAL_ 884 PTC_OverCrtFlt 0 "Normal" 1 "Fault" ;
VAL_ 884 PTC_HVUnderVoltFlt 0 "Normal" 1 "Fault" ;
VAL_ 884 PTC_HVOverVoltFlt 0 "Normal" 1 "Fault" ;
VAL_ 884 PTC_ChkBattOverVoltFlt 0 "Normal" 1 "Fault" ;
VAL_ 884 PTC_ChkBattUnderVoltFlt 0 "Normal" 1 "Fault" ;
VAL_ 884 PTC_InlTSnsrFlt 0 "Normal" 1 "Fault" ;
VAL_ 884 PTC_OutlTSnsrFlt 0 "Normal" 1 "Fault" ;
VAL_ 884 PTC_InlOverTFlt 0 "Normal" 1 "Fault" ;
VAL_ 884 PTC_OutlOverTFlt 0 "Normal" 1 "Fault" ;
VAL_ 884 PTC_PCBOverTFlt 0 "Normal" 1 "Fault" ;
VAL_ 884 PTC_PCBTSnsrFlt 0 "Normal" 1 "Fault" ;
VAL_ 884 PTC_PwrOutpFlt 0 "Normal" 1 "Fault" ;
VAL_ 889 PTC_IninSts 0 "Initialization not completed" 1 "Initialization completed" ;
VAL_ 889 PTC_HVPwrSplySts 0 "Not powered" 1 "Powered" ;
VAL_ 889 PTC_ActGear 0 "0 gear" 1 "First gear" 2 "Second gear" 3 "Third gear" 4 "Fourth gear" 5 "Five gears" 6 "Six gears" ;
VAL_ 889 PTC_Mod 0 "Gear working mode" 1 "Power working mode" ;
VAL_ 891 CVC_Front_SOV_OnOff_Sts 0 "Invaild" 1 "OFF" 2 "ON" 3 "Fault" ;
VAL_ 891 CVC_Rear_SOV_OnOff_Sts 0 "Invaild" 1 "OFF" 2 "ON" 3 "Fault" ;
VAL_ 1121 EAC_status 0 "Compressor off" 1 "Compressor on" 2 "Compressor limit" 3 "Pre-Heating" 4 "Reserved" 5 "Reserved" 6 "Init" 7 "Failure of EAC" ;
VAL_ 1873 CVC_DebugDiag2 0 "No Error" 1 "Error Level 1" 2 "Error Level 2" 3 "Error Level 3" 4 "Error Level 4" ;
VAL_ 1873 CVC_DebugDiag1 0 "No Error" 1 "Error Level 1" 2 "Error Level 2" 3 "Error Level 3" 4 "Error Level 4" ;
VAL_ 1873 CVC_DebugDiag5 0 "No Error" 1 "Error Level 1" 2 "Error Level 2" 3 "Error Level 3" 4 "Error Level 4" ;
VAL_ 1873 CVC_DebugDiag4 0 "No Error" 1 "Error Level 1" 2 "Error Level 2" 3 "Error Level 3" 4 "Error Level 4" ;
VAL_ 1873 CVC_DebugDiag3 0 "No Error" 1 "Error Level 1" 2 "Error Level 2" 3 "Error Level 3" 4 "Error Level 4" ;
VAL_ 1873 CVC_DebugDiag8 0 "No Error" 1 "Error Level 1" 2 "Error Level 2" 3 "Error Level 3" 4 "Error Level 4" ;
VAL_ 1873 CVC_DebugDiag7 0 "No Error" 1 "Error Level 1" 2 "Error Level 2" 3 "Error Level 3" 4 "Error Level 4" ;
VAL_ 1873 CVC_DebugDiag6 0 "No Error" 1 "Error Level 1" 2 "Error Level 2" 3 "Error Level 3" 4 "Error Level 4" ;
VAL_ 1873 CVC_DebugDiag10 0 "No Error" 1 "Error Level 1" 2 "Error Level 2" 3 "Error Level 3" 4 "Error Level 4" ;
VAL_ 1873 CVC_DebugDiag9 0 "No Error" 1 "Error Level 1" 2 "Error Level 2" 3 "Error Level 3" 4 "Error Level 4" ;
VAL_ 1873 CVC_DebugDiag13 0 "No Error" 1 "Error Level 1" 2 "Error Level 2" 3 "Error Level 3" 4 "Error Level 4" ;
VAL_ 1873 CVC_DebugDiag12 0 "No Error" 1 "Error Level 1" 2 "Error Level 2" 3 "Error Level 3" 4 "Error Level 4" ;
VAL_ 1873 CVC_DebugDiag11 0 "No Error" 1 "Error Level 1" 2 "Error Level 2" 3 "Error Level 3" 4 "Error Level 4" ;
VAL_ 1873 CVC_DebugDiag16 0 "No Error" 1 "Error Level 1" 2 "Error Level 2" 3 "Error Level 3" 4 "Error Level 4" ;
VAL_ 1873 CVC_DebugDiag15 0 "No Error" 1 "Error Level 1" 2 "Error Level 2" 3 "Error Level 3" 4 "Error Level 4" ;
VAL_ 1873 CVC_DebugDiag14 0 "No Error" 1 "Error Level 1" 2 "Error Level 2" 3 "Error Level 3" 4 "Error Level 4" ;
VAL_ 1873 CVC_DebugDiag18 0 "No Error" 1 "Error Level 1" 2 "Error Level 2" 3 "Error Level 3" 4 "Error Level 4" ;
VAL_ 1873 CVC_DebugDiag17 0 "No Error" 1 "Error Level 1" 2 "Error Level 2" 3 "Error Level 3" 4 "Error Level 4" ;
VAL_ 1873 CVC_DebugDiag20 0 "No Error" 1 "Error Level 1" 2 "Error Level 2" 3 "Error Level 3" 4 "Error Level 4" ;
VAL_ 1873 CVC_DebugDiag19 0 "No Error" 1 "Error Level 1" 2 "Error Level 2" 3 "Error Level 3" 4 "Error Level 4" ;
VAL_ 1874 CVC_Debug4 0 "No Error" 1 "Warning" 2 "Reduced HV System Power" 3 "Reduced Front EDS Power" 4 "Reduced Rear EDS Power" 5 "Front EDS Inhibit" 6 "Rear EDS Inhibit" 7 "Limp Home" 8 "Neutral Request" 9 "Soft Shutdown" 10 "Reduced HV System Power and Reduced Front EDS Power" 11 "Reduced HV System Power and Reduced Rear EDS Power" 12 "Reduced Front EDS Power and Reduced Rear EDS Power" 13 "Reduced HV System Power and Front EDS Inhibit" 14 "Reduced Rear EDS Power and Front EDS Inhibit" 15 "Reduced HV System Power and Rear EDS Inhibit" 16 "Reduced Front EDS Power and Rear EDS Inhibit" 17 "Reduced HV System Power and Limp Home" 18 "Front EDS Inhibit and Limp Home" 19 "Rear EDS Inhibit and Limp Home" 20 "Reduced HV System Power and Neutral Request" 21 "Emergency Shutdown" ;
VAL_ 537 EVCC_OBC_StsModeReq 2 "Standby" 7 "DisCharge" 9 "Heating/Cooling" 10 "Charge allowed" 11 "ShutDown" ;
VAL_ 537 EVCC_S2_Sts 0 "CP open" 1 "S2 open" 2 "S2 Close" 7 "Invalid" ;
VAL_ 537 EVCC_StsChgCC 0 "CC open(CC open)" 1 "Half connection(S3 open)(Reserve)" 2 "1500Ω(DC Charge)" 3 "680Ω(16A)" 4 "220Ω(32A)" 5 "100Ω(63A)" 6 "Signal Fault" ;
VAL_ 593 EVCC_ChargeMode 0 "init" 1 "DC Charging" 2 "Normal AC charge(PWM)" 3 "PLC AC charging" ;
VAL_ 696 EVCC_VehDischg_Sts 0 "Not Ready" 1 "Discharging in-progess" 2 "Ready" 3 "Shutdown" 4 "Stop discharging" 5 "Invalid" ;
VAL_ 696 EVCC_V2L_adapter_Sts 0 "V2L adapter not plugged-in" 1 "V2L adapter plugged-in, locked" 2 "V2L adapter plugged-in, release" 3 "Invalid" ;
VAL_ 696 EVCC_ConnectorType_Sts 0 "No Adapter" 1 "V2L adapter" 2 "Invalid" ;
VAL_ 843 EVSE_DC_Stt 0 "Init" 1 "EVSE not ready" 2 "EVSE ready" 3 "EVSE shutdown" 4 "EVSE utility interrupt event" 5 "EVSE isolation monitoring active" 6 "EVSE emergency shutdown" 7 "EVSE Malfunction" 8 "Reserved by ISO/IEC for future use" 9 "Reserved by ISO/IEC for future use" 10 "Reserved by ISO/IEC for future use" 11 "Reserved by ISO/IEC for future use" 12 "Reserved by ISO/IEC for future use" ;
VAL_ 843 EVSE_CtrlPilot_STS 0 "A" 1 "B" 2 "C" 3 "D" 4 "E" 5 "F" 6 "Error" ;
VAL_ 843 EVSE_IsolationLvl 0 "Init" 1 "Invalid" 2 "Valid" 3 "Warning" 4 "Fault" 5 "No IMD" ;
VAL_ 843 EVSE_VehChgComm_STAT 0 "None" 1 "Scc_StateMachineStatus_Initialized" 2 "SLAC" 3 "WaitForIP" 4 "SECCDiscoveryProtocol" 5 "TLConnection" 6 "SupportedAppProtocol" 7 "SessionSetup" 8 "ServiceDiscovery" 9 "ServiceDetail" 10 "PaymentServiceSelection" 11 "CertificateInstallation" 12 "CertificateUpdate" 13 "PaymentDetails" 14 "Authorization" 15 "ChargeParameterDiscovery" 16 "PowerDelivery" 17 "MeteringReceipt" 18 "ChargingStatus (AC Charging)" 19 "CableCheck" 20 "PreCharge" 21 "CurrentDemand" 22 "WeldingDetection" 23 "Scc_StateMachineStatus_SessionStop" 24 "StopCommunicationSession" 25 "Finished" 26 "Error_WaitingForRetry" 27 "Error_Stopped" ;
VAL_ 843 EVSE_ResponseCode 0 "Init" 1 "No error" 2 "No error, new session established" 3 "No error, old session joined" 4 "No error, certificate expires soon" 5 "Error" 6 "Sequence error" 7 "Error, service ID invalid" 8 "Error, unknown session" 9 "Error, service selection invalid" 10 "Error, payment selection invalid" 11 "Error, Certificate Expired" 12 "Error, Signature Error" 13 "Error, No Certificate Available" 14 "Error, Cert Chain Error" 15 "Error, Challenge Invalid" 16 "Error, Contract Canceled" 17 "Error, Wrong Charge Parameter" 18 "Error, Power Delivery Not Applied" 19 "Error, Tariff Selection Invalid" 20 "Error, Charging Profile Invalid" 21 "Error, Metering Signature Not Valid" 22 "Error, No Charge Service Selected" 23 "Error, Wrong Energy Transfer Mode" 24 "Error, Contactor Error" 25 "Error, Certificate Not Allowed At This EVSE" 26 "Error, Certificate Revoked" ;
VAL_ 845 EVCC_STAT_BrakeSts 0 "Not Pressed" 1 "Pressed" 2 "Reversed" 3 "Invalid" ;
VAL_ 845 EVCC_Req_InsulationMon 0 "ON" 1 "OFF" 2 "Reversed" 3 "Invalid" ;
VAL_ 845 EVCC_PnC_Contract_STS 0 "Not available" 1 "Installed" 2 "Error" 3 "Invalid" ;
VAL_ 845 EVCC_FcContactor_Req 0 "Request open" 1 "Request close" 2 "Reversed" 3 "Invalid" ;
VAL_ 850 EVCC_SOV2_ControlStatus 0 "Invalid" 1 "OFF" 2 "ON" 3 "Fault" ;
VAL_ 850 EVCC_SOV1_ControlStatus 0 "Invalid" 1 "OFF" 2 "ON" 3 "Fault" ;
VAL_ 850 EVCC_MotorWaterPump_Status 0 "Invalid" 1 "OFF" 2 "Normal operation" 3 "Dry" 4 "Fault" ;
VAL_ 850 EVCC_BatteryWaterPump_Status 0 "Invalid" 1 "OFF" 2 "Normal operation" 3 "Dry" 4 "Over & Under Voltage" 5 "Over Heat" ;
VAL_ 850 EVCC_PTC_OnOff_Status 0 "Invalid" 1 "OFF" 2 "ON" 3 "Fault" ;
VAL_ 851 EVCC_EAC_OnOff_Status 0 "Invalid" 1 "OFF" 2 "ON" 3 "Fault" ;
VAL_ 851 EVCC_DualPressureSwitch_Status 0 "Invalid" 1 "OFF" 2 "ON" 3 "Fault" ;
VAL_ 851 EVCC_MainRelay_OnOff_Status 0 "Invalid" 1 "OFF" 2 "ON" 3 "Fault" ;
VAL_ 851 EVCC_ElectricFan_OnOff_Sts 0 "Invalid" 1 "OFF" 2 "ON" 3 "Fault" ;
VAL_ 851 EVCC_CL15_Status 0 "Invalid" 1 "OFF" 2 "ON" 3 "Fault" ;
VAL_ 851 EVCC_PGearPressSignal1_Status 0 "Invalid" 1 "OFF" 2 "ON" 3 "Fault" ;
VAL_ 851 EVCC_PGearStsLight_OnOff_Sts 0 "Invalid" 1 "OFF" 2 "ON" 3 "Fault" ;
VAL_ 851 EVCC_ExpValve_OnOff_Status 0 "Invalid" 1 "OFF" 2 "ON" 3 "Fault" ;
VAL_ 851 EVCC_EACPTCHVIL_Status 0 "Normal" 1 "Error" 2 "Reserved" 3 "Invalid" ;
VAL_ 859 OBC_Req 0 "OBC OFF" 1 "OBC ON NORMAL" 2 "OBC ON VOLTAGE" 3 "OBC_ON_DISCHARGE" ;
VAL_ 892 EVCC_ChgGun_Sts 0 "Gun not plugged-in" 1 "Gun plugged-in, locked" 2 "Gun plugged-in, released" 3 "Error, cannot lock" 4 "Error, cannot release" 5 "Bad connection" 6 "Reversed" 7 "Invalid" ;
VAL_ 892 EVCC_ChgFlap_Sts 0 "Locked" 1 "Unlocked" 2 "Faults" 3 "Invalid" ;
VAL_ 892 EVCC_ChgType 0 "No charging" 1 "Normal AC charging" 2 "PLC AC charging" 3 "DC charging" 4 "V2L" 5 "Reserved" 6 "Reserved" 7 "Invalid" ;
VAL_ 892 EVCC_VehChg_Sts 0 "Not charging" 1 "Charging in-progress" 2 "Waiting to start charging" 3 "Charging complete" 4 "Charge fault" 5 "Reserved" 6 "Reserved" 7 "Invalid" ;
VAL_ 892 EVCC_ChgAuthen_Sts 0 "Not authenticating" 1 "Authenticating" 2 "Authentication success" 3 "Authentication failed" 4 "Forbidden vehicle" 5 "Reserved" 6 "Reserved" 7 "Invalid" ;
VAL_ 892 EVCC_PaymentType 0 "Init" 1 "EIM" 2 "PnC" 3 "Reserved" 4 "Reserved" 5 "Reserved" 6 "Reserved" 7 "Invalid" ;
VAL_ 892 EVCC_VehChgCompError_Sts 0 "No error" 1 "Error level 1" 2 "Error level 2" 3 "Error level 3" 4 "Error level 4" 5 "Reserved" 6 "Reserved" 7 "Reserved" ;
VAL_ 892 EVCC_S3Button_Sts 0 "Not pressed" 1 "Pressed" 2 "Reserved" 3 "Invalid" ;
VAL_ 1145 EVCC_evt_eGunPlugTemp 0 "Normal" 1 "Error" ;
VAL_ 1145 EVCC_evt_eObcSts 0 "Normal" 1 "Error" ;
VAL_ 1145 EVCC_evt_eBmsInsuProc 0 "Normal" 1 "Error" ;
VAL_ 1145 EVCC_evt_eHvBatSupVolt 0 "Normal" 1 "Error" ;
VAL_ 1145 EVCC_evt_eDcfcStsProc 0 "Normal" 1 "Error" ;
VAL_ 1145 EVCC_evt_eDcfcStsSna 0 "Normal" 1 "Error" ;
VAL_ 1145 EVCC_evt_eChrgPortHiVolt 0 "Normal" 1 "Error" ;
VAL_ 1145 EVCC_evt_eTempSnsDatInvd 0 "Normal" 1 "Error" ;
VAL_ 1145 EVCC_evt_FS23LostComm 0 "Normal" 1 "Error" ;
VAL_ 1145 EVCC_evt_eFS23SelfTestFail 0 "Normal" 1 "Error" ;
VAL_ 1145 EVCC_evt_eMcuPwrFail 0 "Normal" 1 "Error" ;
VAL_ 1145 EVCC_evt_eAcuCrs 0 "Normal" 1 "Error" ;
VAL_ 1145 EVCC_WkSource 0 "Invalid" 1 "Gun wake" 2 "IGN wake" 3 "Can wake" 4 "Invalid" ;
VAL_ 1145 EVCC_bSleepValid 0 "Sleep Allow" 1 "No Sleep Allow" ;
